VERSION ""

NS_ :

BS_:

BU_: ECM

BO_ 2566841088 EC_s0: 39 Vector__XXX
 SG_ SupportTSC1CtrlPurposeGroup4Of4 : 304|8@1+ (1,0) [0|255] "" Vector__XXX
 SG_ SupportVariableRateTSC1Message : 272|8@1+ (1,0) [0|255] "" Vector__XXX
 SG_ SupportTSC1CtrlPurposeGroup3Of4 : 296|8@1+ (1,0) [0|255] "" Vector__XXX
 SG_ SupportTSC1CtrlPurposeGroup2Of4 : 288|8@1+ (1,0) [0|255] "" Vector__XXX
 SG_ SupportTSC1CtrlPurposeGroup1Of4 : 280|8@1+ (1,0) [0|255] "" Vector__XXX
 SG_ EngDefaultTorqueLimit : 256|16@1+ (1,0) [0|64255] "Nm" Vector__XXX
 SG_ EngMomentOfInertia : 240|16@1+ (0.004,0) [0|257.02] "kg-m²" Vector__XXX
 SG_ EngExRngRqdSpdCtrlRngUpperLimit : 224|16@1+ (0.125,0) [0|8031.875] "rpm" Vector__XXX
 SG_ EngRqdTorqueCtrlRangeUpperLimit : 216|8@1+ (1,-125) [-125|125] "%" Vector__XXX
 SG_ EngRqdTorqueCtrlRangeLowerLimit : 208|8@1+ (1,-125) [-125|125] "%" Vector__XXX
 SG_ EngRqedSpeedCtrlRangeUpperLimit : 200|8@1+ (10,0) [0|2500] "rpm" Vector__XXX
 SG_ EngRqedSpeedCtrlRangeLowerLimit : 192|8@1+ (10,0) [0|2500] "rpm" Vector__XXX
 SG_ EngMxMomentaryOverrideTimeLimit : 184|8@1+ (0.1,0) [0|25] "s" Vector__XXX
 SG_ EngMxMmntaryOverrideSpeedPoint7 : 168|16@1+ (0.125,0) [0|8031.875] "rpm" Vector__XXX
 SG_ EngReferenceTorque : 152|16@1+ (1,0) [0|64255] "Nm" Vector__XXX
 SG_ EngSpeedAtHighIdlePoint6 : 120|16@1+ (0.125,0) [0|8031.875] "rpm" Vector__XXX
 SG_ EngGainOfEndspeedGovernor : 136|16@1+ (0.00078125,0) [0|50.2] "%/rpm" Vector__XXX
 SG_ EngPercentTorqueAtPoint5 : 112|8@1+ (1,-125) [-125|125] "%" Vector__XXX
 SG_ EngSpeedAtPoint5 : 96|16@1+ (0.125,0) [0|8031.875] "rpm" Vector__XXX
 SG_ EngPercentTorqueAtPoint4 : 88|8@1+ (1,-125) [-125|125] "%" Vector__XXX
 SG_ EngSpeedAtPoint4 : 72|16@1+ (0.125,0) [0|8031.875] "rpm" Vector__XXX
 SG_ EngPercentTorqueAtPoint3 : 64|8@1+ (1,-125) [-125|125] "%" Vector__XXX
 SG_ EngSpeedAtPoint3 : 48|16@1+ (0.125,0) [0|8031.875] "rpm" Vector__XXX
 SG_ EngPercentTorqueAtPoint2 : 40|8@1+ (1,-125) [-125|125] "%" Vector__XXX
 SG_ EngSpeedAtPoint2 : 24|16@1+ (0.125,0) [0|8031.875] "rpm" Vector__XXX
 SG_ EngPercentTorqueAtIdlePoint1 : 16|8@1+ (1,-125) [-125|125] "%" Vector__XXX
 SG_ EngSpeedAtIdlePoint1 : 0|16@1+ (0.125,0) [0|8031.875] "rpm" Vector__XXX

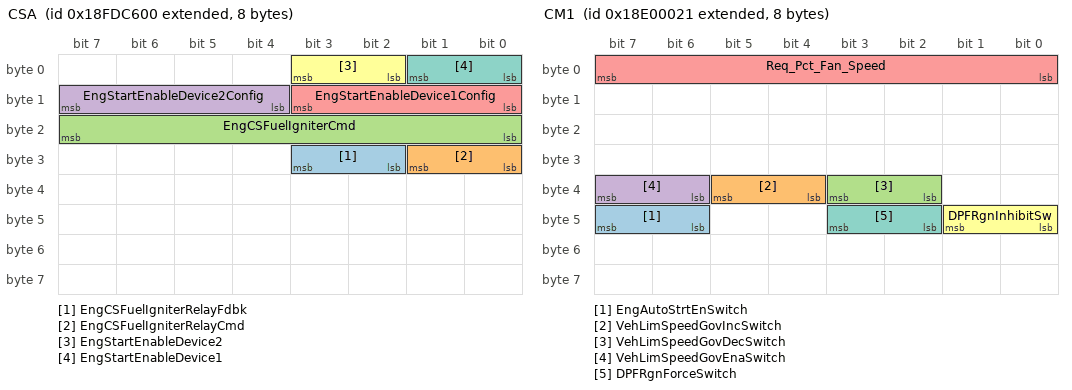
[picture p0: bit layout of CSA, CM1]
BO_ 2566768128 CSA: 8 Vector__XXX
 SG_ EngCSFuelIgniterRelayFdbk : 26|2@1+ (1,0) [0|3] "" Vector__XXX
 SG_ EngCSFuelIgniterRelayCmd : 24|2@1+ (1,0) [0|3] "" Vector__XXX
 SG_ EngCSFuelIgniterCmd : 16|8@1+ (0.4,0) [0|102] "%" Vector__XXX
 SG_ EngStartEnableDevice2Config : 12|4@1+ (1,0) [0|15] "" Vector__XXX
 SG_ EngStartEnableDevice1Config : 8|4@1+ (1,0) [0|15] "" Vector__XXX
 SG_ EngStartEnableDevice2 : 2|2@1+ (1,0) [0|3] "" Vector__XXX
 SG_ EngStartEnableDevice1 : 0|2@1+ (1,0) [0|3] "" Vector__XXX

BO_ 2564816929 CM1: 8 Vector__XXX
 SG_ EngAutoStrtEnSwitch : 46|2@1+ (1,0) [0|0] "" Vector__XXX
 SG_ VehLimSpeedGovIncSwitch : 36|2@1+ (1,0) [0|3] "" Vector__XXX
 SG_ VehLimSpeedGovDecSwitch : 34|2@1+ (1,0) [0|3] "" Vector__XXX
 SG_ VehLimSpeedGovEnaSwitch : 38|2@1+ (1,0) [0|3] "" Vector__XXX
 SG_ Req_Pct_Fan_Speed : 0|8@1+ (0.4,0) [0|100] "%" Vector__XXX
 SG_ DPFRgnInhibitSw : 40|2@1+ (1,0) [0|3] "unitless" Vector__XXX
 SG_ DPFRgnForceSwitch : 42|2@1+ (1,0) [0|3] "unitless" Vector__XXX

BO_ 2566843136 CI: 45 Vector__XXX
 SG_ UnitNumber_B09_B10 : 344|16@1+ (1,0) [0|0] "ASCII" Vector__XXX
 SG_ SerialNumber_B17 : 264|8@1+ (1,0) [0|0] "ASCII" Vector__XXX
 SG_ SerialNumber_B09_B16 : 200|64@1+ (1,0) [0|0] "ASCII" Vector__XXX
 SG_ CI_Delimiter_3 : 272|8@1+ (1,0) [0|0] "ASCII" Vector__XXX
 SG_ CI_Delimiter_2 : 128|8@1+ (1,0) [0|0] "ASCII" Vector__XXX
 SG_ Model_B09_B10 : 112|16@1+ (1,0) [0|0] "ASCII" Vector__XXX
 SG_ CI_Delimiter_1 : 40|8@1+ (1,0) [0|0] "ASCII" Vector__XXX
 SG_ UnitNumber_B01_B08 : 280|64@1+ (1,0) [0|0] "ASCII" Vector__XXX
 SG_ SerialNumber_B01_B08 : 136|64@1+ (1,0) [0|0] "ASCII" Vector__XXX
 SG_ Model_B01_B08 : 48|64@1+ (1,0) [0|0] "ASCII" Vector__XXX
 SG_ Make : 0|40@1+ (1,0) [0|0] "ASCII" Vector__XXX

BO_ 2566844672 CCVS_s0: 8 Vector__XXX
 SG_ EngShutdownOverrideSwitch : 62|2@1+ (1,0) [0|3] "" Vector__XXX
 SG_ EngTestModeSwitch : 60|2@1+ (1,0) [0|3] "" Vector__XXX
 SG_ EngIdleDecrementSwitch : 58|2@1+ (1,0) [0|3] "" Vector__XXX
 SG_ EngIdleIncrementSwitch : 56|2@1+ (1,0) [0|3] "" Vector__XXX
 SG_ CruiseCtrlStates : 53|3@1+ (1,0) [0|7] "" Vector__XXX
 SG_ PTOState : 48|5@1+ (1,0) [0|31] "" Vector__XXX
 SG_ CruiseCtrlSetSpeed : 40|8@1+ (1,0) [0|250] "km/h" Vector__XXX
 SG_ CruiseCtrlAccelerateSwitch : 38|2@1+ (1,0) [0|3] "" Vector__XXX
 SG_ CruiseCtrlResumeSwitch : 36|2@1+ (1,0) [0|3] "" Vector__XXX
 SG_ CruiseCtrlCoastSwitch : 34|2@1+ (1,0) [0|3] "" Vector__XXX
 SG_ CruiseCtrlSetSwitch : 32|2@1+ (1,0) [0|3] "" Vector__XXX
 SG_ ClutchSwitch : 30|2@1+ (1,0) [0|3] "" Vector__XXX
 SG_ BrakeSwitch : 28|2@1+ (1,0) [0|3] "" Vector__XXX
 SG_ CruiseCtrlEnableSwitch : 26|2@1+ (1,0) [0|3] "" Vector__XXX
 SG_ CruiseCtrlActive : 24|2@1+ (1,0) [0|3] "" Vector__XXX
 SG_ WheelBasedVehicleSpeed : 8|16@1+ (0.00390625,0) [0|250.996] "km/h" Vector__XXX
 SG_ CruiseCtrlPauseSwitch : 4|2@1+ (1,0) [0|3] "" Vector__XXX
 SG_ ParkingBrakeSwitch : 2|2@1+ (1,0) [0|3] "" Vector__XXX
 SG_ TwoSpeedAxleSwitch : 0|2@1+ (1,0) [0|3] "" Vector__XXX

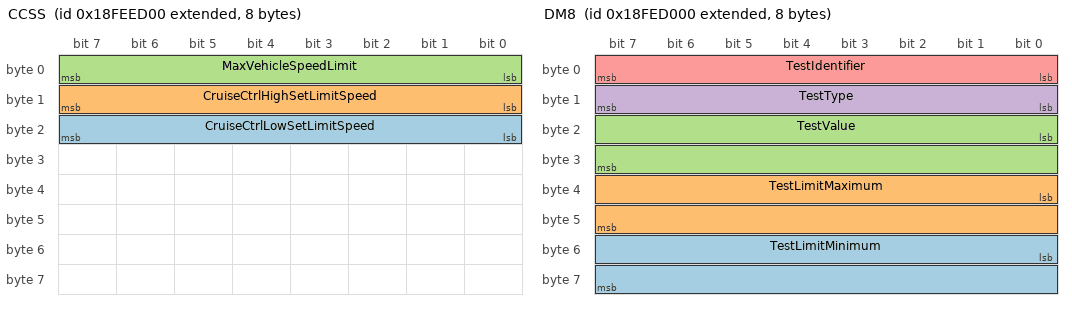
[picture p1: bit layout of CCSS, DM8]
BO_ 2566843648 CCSS: 8 Vector__XXX
 SG_ CruiseCtrlLowSetLimitSpeed : 16|8@1+ (1,0) [0|250] "km/h" Vector__XXX
 SG_ CruiseCtrlHighSetLimitSpeed : 8|8@1+ (1,0) [0|250] "km/h" Vector__XXX
 SG_ MaxVehicleSpeedLimit : 0|8@1+ (1,0) [0|250] "km/h" Vector__XXX

BO_ 2566836224 DM8: 8 Vector__XXX
 SG_ TestLimitMinimum : 48|16@1+ (1,0) [0|64255] "" Vector__XXX
 SG_ TestLimitMaximum : 32|16@1+ (1,0) [0|64255] "" Vector__XXX
 SG_ TestValue : 16|16@1+ (1,0) [0|64255] "" Vector__XXX
 SG_ TestType : 8|8@1+ (1,0) [1|64] "" Vector__XXX
 SG_ TestIdentifier : 0|8@1+ (1,0) [1|64] "" Vector__XXX

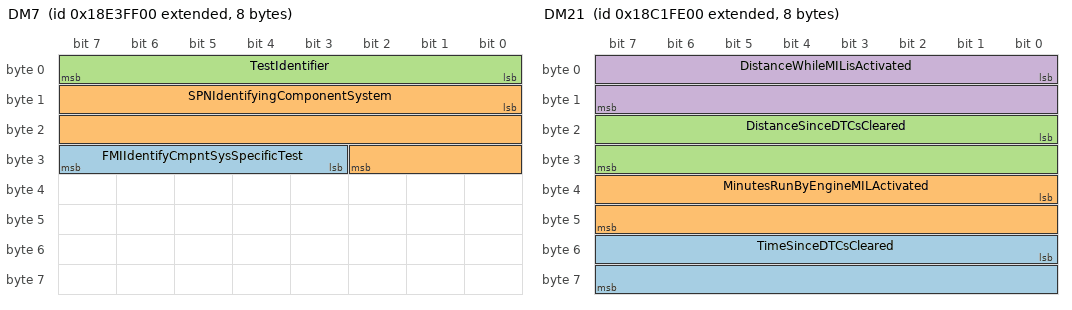
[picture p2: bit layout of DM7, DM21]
BO_ 2565078784 DM7: 8 Vector__XXX
 SG_ FMIIdentifyCmpntSysSpecificTest : 27|5@1+ (1,0) [0|31] "" Vector__XXX
 SG_ SPNIdentifyingComponentSystem : 8|19@1+ (1,0) [0|524287] "" Vector__XXX
 SG_ TestIdentifier : 0|8@1+ (1,0) [1|64] "" Vector__XXX

BO_ 2566835968 DM6: 22 Vector__XXX
 SG_ SPN5 : 144|16@1+ (1,0) [0|65536] "" Vector__XXX
 SG_ SPN4 : 112|16@1+ (1,0) [0|65536] "" Vector__XXX
 SG_ SPN3 : 80|16@1+ (1,0) [0|65536] "" Vector__XXX
 SG_ SPN2 : 48|16@1+ (1,0) [0|65536] "" Vector__XXX
 SG_ SPN1 : 16|16@1+ (1,0) [0|65536] "" Vector__XXX
 SG_ RedStopLampStatus : 4|2@1+ (1,0) [0|3] "" Vector__XXX
 SG_ ProtectLampStatus : 0|2@1+ (1,0) [0|3] "" Vector__XXX
 SG_ AmberWarningLampStatus : 2|2@1+ (1,0) [0|3] "" Vector__XXX
 SG_ MalfunctionIndicatorLampStatus : 6|2@1+ (1,0) [0|3] "" Vector__XXX
 SG_ FailureModeIdentifier5 : 160|5@1+ (1,0) [0|0] "" Vector__XXX
 SG_ FailureModeIdentifier4 : 128|5@1+ (1,0) [0|0] "" Vector__XXX
 SG_ FailureModeIdentifier3 : 96|5@1+ (1,0) [0|0] "" Vector__XXX
 SG_ FailureModeIdentifier2 : 64|5@1+ (1,0) [0|0] "" Vector__XXX
 SG_ SPNConversionMethod5 : 175|1@1+ (1,0) [0|1] "" Vector__XXX
 SG_ SPNConversionMethod4 : 143|1@1+ (1,0) [0|1] "" Vector__XXX
 SG_ SPNConversionMethod3 : 111|1@1+ (1,0) [0|1] "" Vector__XXX
 SG_ SPNConversionMethod2 : 79|1@1+ (1,0) [0|1] "" Vector__XXX
 SG_ OccurenceCount5 : 168|7@1+ (1,0) [0|126] "" Vector__XXX
 SG_ OccurenceCount4 : 136|7@1+ (1,0) [0|126] "" Vector__XXX
 SG_ OccurenceCount3 : 104|7@1+ (1,0) [0|126] "" Vector__XXX
 SG_ OccurenceCount2 : 72|7@1+ (1,0) [0|126] "" Vector__XXX
 SG_ OccurenceCount1 : 40|7@1+ (1,0) [0|126] "" Vector__XXX
 SG_ SPNConversionMethod1 : 47|1@1+ (1,0) [0|1] "" Vector__XXX
 SG_ FailureModeIdentifier1 : 32|5@1+ (1,0) [0|0] "" Vector__XXX
 SG_ SPN5High : 165|3@1+ (1,0) [0|7] "" Vector__XXX
 SG_ SPN4High : 133|3@1+ (1,0) [0|7] "" Vector__XXX
 SG_ SPN3High : 101|3@1+ (1,0) [0|7] "" Vector__XXX
 SG_ SPN2High : 69|3@1+ (1,0) [0|7] "" Vector__XXX
 SG_ SPN1High : 37|3@1+ (1,0) [0|7] "" Vector__XXX

BO_ 2566835712 DM5: 8 Vector__XXX
 SG_ PMFilterMonStatus : 58|1@1+ (1,0) [0|1] "" Vector__XXX
 SG_ NOxCnvrtctlystMonStatus : 59|1@1+ (1,0) [0|1] "" Vector__XXX
 SG_ NHMCCnvrtctlystMonStatus : 60|1@1+ (1,0) [0|1] "" Vector__XXX
 SG_ BstPressCtrlSystemMonStatus : 57|1@1+ (1,0) [0|1] "" Vector__XXX
 SG_ NOxCnvrtctlystMonSupp : 43|1@1+ (1,0) [0|1] "" Vector__XXX
 SG_ PMFilterMonSupp : 42|1@1+ (1,0) [0|1] "" Vector__XXX
 SG_ NHMCCnvrtctlystMonSupp : 44|1@1+ (1,0) [0|1] "" Vector__XXX
 SG_ BstPressCtrlSystemMonSupp : 41|1@1+ (1,0) [0|1] "" Vector__XXX
 SG_ MisfireMonitoringSupport : 24|1@1+ (1,0) [0|0] "" Vector__XXX
 SG_ OBDCompliance : 16|8@1+ (1,0) [0|240] "" Vector__XXX
 SG_ PreviouslyActiveTroubleCodes : 8|8@1+ (1,0) [0|240] "" Vector__XXX
 SG_ ActiveTroubleCodes : 0|8@1+ (1,0) [0|240] "" Vector__XXX
 SG_ SecondAirSystemMonStatus : 51|1@1+ (1,0) [0|1] "" Vector__XXX
 SG_ EvaporativeSystemMonStatus : 50|1@1+ (1,0) [0|1] "" Vector__XXX
 SG_ ACSystemRefrigerantMonStatus : 52|1@1+ (1,0) [0|1] "" Vector__XXX
 SG_ OxygenSensorHeaterMonStatus : 54|1@1+ (1,0) [0|1] "" Vector__XXX
 SG_ OxygenSensorMonStatus : 53|1@1+ (1,0) [0|1] "" Vector__XXX
 SG_ EGRSystemMonitoringStatus : 55|1@1+ (1,0) [0|1] "" Vector__XXX
 SG_ CatalystMonStatus : 48|1@1+ (1,0) [0|1] "" Vector__XXX
 SG_ ColdStartAidSystemMonStatus : 56|1@1+ (1,0) [0|1] "" Vector__XXX
 SG_ HeatedCatalystMonStatus : 49|1@1+ (1,0) [0|0] "" Vector__XXX
 SG_ CatalystMonSupp : 32|1@1+ (1,0) [0|1] "" Vector__XXX
 SG_ ColdStartAidSystemMonSupp : 40|1@1+ (1,0) [0|1] "" Vector__XXX
 SG_ HeatedCatalystMonSupp : 33|1@1+ (1,0) [0|0] "" Vector__XXX
 SG_ EvaporativeSystemMonSupp : 34|1@1+ (1,0) [0|1] "" Vector__XXX
 SG_ SecondAirSystemMonSupp : 35|1@1+ (1,0) [0|1] "" Vector__XXX
 SG_ ACSystemRefrigerantMonSupp : 36|1@1+ (1,0) [0|1] "" Vector__XXX
 SG_ OxygenSensorMonSupp : 37|1@1+ (1,0) [0|1] "" Vector__XXX
 SG_ OxygenSensorHeaterMonSupp : 38|1@1+ (1,0) [0|1] "" Vector__XXX
 SG_ EGRSystemMonitoringSupp : 39|1@1+ (1,0) [0|1] "" Vector__XXX
 SG_ MisfireMonitoringStatus : 28|1@1+ (1,0) [0|0] "" Vector__XXX
 SG_ ComprehensiveCompMonStatus : 30|1@1+ (1,0) [0|1] "" Vector__XXX
 SG_ FuelSystemMonitoringStatus : 29|1@1+ (1,0) [0|1] "" Vector__XXX
 SG_ ComprehensiveComponentMonSupp : 26|1@1+ (1,0) [0|0] "" Vector__XXX
 SG_ FuelSystemMonitoringSupport : 25|1@1+ (1,0) [0|1] "" Vector__XXX

BO_ 2566835456 DM4: 13 Vector__XXX
 SG_ SPN1 : 8|16@1+ (1,0) [0|65536] "" Vector__XXX
 SG_ EngSpeed : 56|16@1+ (0.125,0) [0|8031.875] "rpm" Vector__XXX
 SG_ EngTurboBoostPress : 48|8@1+ (2,0) [0|500] "kPa" Vector__XXX
 SG_ EngPercentLoadAtCurrentSpeed : 72|8@1+ (1,0) [0|250] "%" Vector__XXX
 SG_ WheelBasedVehicleSpeed : 88|16@1+ (0.00390625,0) [0|250.996] "km/h" Vector__XXX
 SG_ OccurenceCount1 : 32|7@1+ (1,0) [0|126] "" Vector__XXX
 SG_ SPNConversionMethod1 : 39|1@1+ (1,0) [0|1] "" Vector__XXX
 SG_ FailureModeIdentifier1 : 24|5@1+ (1,0) [0|0] "" Vector__XXX
 SG_ FreezeFrameLength : 0|8@1+ (1,0) [0|255] "byte" Vector__XXX
 SG_ EngTorqueMode : 40|4@1+ (1,0) [0|15] "" Vector__XXX
 SG_ EngineCoolantTemperature : 80|8@1+ (1,-40) [-40|210] "°C" Vector__XXX
 SG_ SPN1High : 29|3@1+ (1,0) [0|7] "" Vector__XXX

BO_ 2566835200 DM3: 0 Vector__XXX

BO_ 2566763776 DM23: 22 Vector__XXX
 SG_ FailureModeIdentifier5 : 160|5@1+ (1,0) [0|0] "" Vector__XXX
 SG_ FailureModeIdentifier4 : 128|5@1+ (1,0) [0|0] "" Vector__XXX
 SG_ FailureModeIdentifier3 : 96|5@1+ (1,0) [0|0] "" Vector__XXX
 SG_ FailureModeIdentifier2 : 64|5@1+ (1,0) [0|0] "" Vector__XXX
 SG_ FailureModeIdentifier1 : 32|5@1+ (1,0) [0|0] "" Vector__XXX
 SG_ FlashRedStopLamp : 12|2@1+ (1,0) [0|3] "" Vector__XXX
 SG_ FlashProtectLamp : 8|2@1+ (1,0) [0|3] "" Vector__XXX
 SG_ FlashMalfuncIndicatorLamp : 14|2@1+ (1,0) [0|3] "" Vector__XXX
 SG_ FlashAmberWarningLamp : 10|2@1+ (1,0) [0|3] "" Vector__XXX
 SG_ SPN5 : 144|16@1+ (1,0) [0|65536] "" Vector__XXX
 SG_ SPN4 : 112|16@1+ (1,0) [0|65536] "" Vector__XXX
 SG_ SPN3 : 80|16@1+ (1,0) [0|65536] "" Vector__XXX
 SG_ SPN2 : 48|16@1+ (1,0) [0|65536] "" Vector__XXX
 SG_ SPN1 : 16|16@1+ (1,0) [0|65536] "" Vector__XXX
 SG_ RedStopLampStatus : 4|2@1+ (1,0) [0|3] "" Vector__XXX
 SG_ ProtectLampStatus : 0|2@1+ (1,0) [0|3] "" Vector__XXX
 SG_ AmberWarningLampStatus : 2|2@1+ (1,0) [0|3] "" Vector__XXX
 SG_ MalfunctionIndicatorLampStatus : 6|2@1+ (1,0) [0|3] "" Vector__XXX
 SG_ OccurenceCount1 : 40|7@1+ (1,0) [0|126] "" Vector__XXX
 SG_ SPNConversionMethod1 : 47|1@1+ (1,0) [0|1] "" Vector__XXX
 SG_ SPNConversionMethod5 : 175|1@1+ (1,0) [0|1] "" Vector__XXX
 SG_ SPNConversionMethod4 : 143|1@1+ (1,0) [0|1] "" Vector__XXX
 SG_ SPNConversionMethod3 : 111|1@1+ (1,0) [0|1] "" Vector__XXX
 SG_ SPNConversionMethod2 : 79|1@1+ (1,0) [0|1] "" Vector__XXX
 SG_ OccurenceCount5 : 168|7@1+ (1,0) [0|126] "" Vector__XXX
 SG_ OccurenceCount4 : 136|7@1+ (1,0) [0|126] "" Vector__XXX
 SG_ OccurenceCount3 : 104|7@1+ (1,0) [0|126] "" Vector__XXX
 SG_ OccurenceCount2 : 72|7@1+ (1,0) [0|126] "" Vector__XXX
 SG_ SPN5High : 165|3@1+ (1,0) [0|7] "" Vector__XXX
 SG_ SPN4High : 133|3@1+ (1,0) [0|7] "" Vector__XXX
 SG_ SPN3High : 101|3@1+ (1,0) [0|7] "" Vector__XXX
 SG_ SPN2High : 69|3@1+ (1,0) [0|7] "" Vector__XXX
 SG_ SPN1High : 37|3@1+ (1,0) [0|7] "" Vector__XXX

BO_ 2562850304 DM21: 8 Vector__XXX
 SG_ TimeSinceDTCsCleared : 48|16@1+ (1,0) [0|64255] "min" Vector__XXX
 SG_ MinutesRunByEngineMILActivated : 32|16@1+ (1,0) [0|64255] "min" Vector__XXX
 SG_ DistanceSinceDTCsCleared : 16|16@1+ (1,0) [0|64255] "km" Vector__XXX
 SG_ DistanceWhileMILisActivated : 0|16@1+ (1,0) [0|64255] "km" Vector__XXX

BO_ 2562915840 DM20: 11 Vector__XXX
 SG_ ApplSysMonitorDenominator : 72|16@1+ (1,0) [0|65535] "" Vector__XXX
 SG_ ApplSysMonitorNumerator : 56|16@1+ (1,0) [0|65535] "" Vector__XXX
 SG_ SPNofApplSysMonitor : 32|24@1+ (1,0) [0|524287] "" Vector__XXX
 SG_ OBDMonitoringCondEncountered : 16|16@1+ (1,0) [0|65535] "" Vector__XXX
 SG_ IgnitionCycleCounter : 0|16@1+ (1,0) [0|65535] "" Vector__XXX

BO_ 2566834944 DM2_s0: 22 Vector__XXX
 SG_ FailureModeIdentifier5 : 160|5@1+ (1,0) [0|0] "" Vector__XXX
 SG_ FailureModeIdentifier4 : 128|5@1+ (1,0) [0|0] "" Vector__XXX
 SG_ FailureModeIdentifier3 : 96|5@1+ (1,0) [0|0] "" Vector__XXX
 SG_ FailureModeIdentifier2 : 64|5@1+ (1,0) [0|0] "" Vector__XXX
 SG_ FailureModeIdentifier1 : 32|5@1+ (1,0) [0|0] "" Vector__XXX
 SG_ FlashRedStopLamp : 12|2@1+ (1,0) [0|3] "" Vector__XXX
 SG_ FlashProtectLamp : 8|2@1+ (1,0) [0|3] "" Vector__XXX
 SG_ FlashMalfuncIndicatorLamp : 14|2@1+ (1,0) [0|3] "" Vector__XXX
 SG_ FlashAmberWarningLamp : 10|2@1+ (1,0) [0|3] "" Vector__XXX
 SG_ SPN5 : 144|16@1+ (1,0) [0|65536] "" Vector__XXX
 SG_ SPN4 : 112|16@1+ (1,0) [0|65536] "" Vector__XXX
 SG_ SPN3 : 80|16@1+ (1,0) [0|65536] "" Vector__XXX
 SG_ SPN2 : 48|16@1+ (1,0) [0|65536] "" Vector__XXX
 SG_ SPN1 : 16|16@1+ (1,0) [0|65536] "" Vector__XXX
 SG_ RedStopLampStatus : 4|2@1+ (1,0) [0|3] "" Vector__XXX
 SG_ ProtectLampStatus : 0|2@1+ (1,0) [0|3] "" Vector__XXX
 SG_ AmberWarningLampStatus : 2|2@1+ (1,0) [0|3] "" Vector__XXX
 SG_ MalfunctionIndicatorLampStatus : 6|2@1+ (1,0) [0|3] "" Vector__XXX
 SG_ OccurenceCount1 : 40|7@1+ (1,0) [0|126] "" Vector__XXX
 SG_ SPNConversionMethod1 : 47|1@1+ (1,0) [0|1] "" Vector__XXX
 SG_ SPNConversionMethod5 : 175|1@1+ (1,0) [0|1] "" Vector__XXX
 SG_ SPNConversionMethod4 : 143|1@1+ (1,0) [0|1] "" Vector__XXX
 SG_ SPNConversionMethod3 : 111|1@1+ (1,0) [0|1] "" Vector__XXX
 SG_ SPNConversionMethod2 : 79|1@1+ (1,0) [0|1] "" Vector__XXX
 SG_ OccurenceCount5 : 168|7@1+ (1,0) [0|126] "" Vector__XXX
 SG_ OccurenceCount4 : 136|7@1+ (1,0) [0|126] "" Vector__XXX
 SG_ OccurenceCount3 : 104|7@1+ (1,0) [0|126] "" Vector__XXX
 SG_ OccurenceCount2 : 72|7@1+ (1,0) [0|126] "" Vector__XXX
 SG_ SPN5High : 165|3@1+ (1,0) [0|7] "" Vector__XXX
 SG_ SPN4High : 133|3@1+ (1,0) [0|7] "" Vector__XXX
 SG_ SPN3High : 101|3@1+ (1,0) [0|7] "" Vector__XXX
 SG_ SPN2High : 69|3@1+ (1,0) [0|7] "" Vector__XXX
 SG_ SPN1High : 37|3@1+ (1,0) [0|7] "" Vector__XXX

BO_ 2631078400 DM19: 20 Vector__XXX
 SG_ CalibrationID4 : 128|32@1+ (1,0) [0|4294967295] "" Vector__XXX
 SG_ CalibrationID3 : 96|32@1+ (1,0) [0|4294967295] "" Vector__XXX
 SG_ CalibrationID2 : 64|32@1+ (1,0) [0|4294967295] "" Vector__XXX
 SG_ CalibrationID1 : 32|32@1+ (1,0) [0|4294967295] "" Vector__XXX
 SG_ CalibrationVerificationNumber : 0|32@1+ (1,0) [0|4294967295] "" Vector__XXX

BO_ 2566837248 DM12: 22 Vector__XXX
 SG_ FlashRedStopLamp : 12|2@1+ (1,0) [0|3] "" Vector__XXX
 SG_ FlashProtectLamp : 8|2@1+ (1,0) [0|3] "" Vector__XXX
 SG_ FlashMalfuncIndicatorLamp : 14|2@1+ (1,0) [0|3] "" Vector__XXX
 SG_ FlashAmberWarningLamp : 10|2@1+ (1,0) [0|3] "" Vector__XXX
 SG_ FailureModeIdentifier5 : 160|5@1+ (1,0) [0|0] "" Vector__XXX
 SG_ FailureModeIdentifier4 : 128|5@1+ (1,0) [0|0] "" Vector__XXX
 SG_ FailureModeIdentifier3 : 96|5@1+ (1,0) [0|0] "" Vector__XXX
 SG_ FailureModeIdentifier2 : 64|5@1+ (1,0) [0|0] "" Vector__XXX
 SG_ FailureModeIdentifier1 : 32|5@1+ (1,0) [0|0] "" Vector__XXX
 SG_ SPN5 : 144|16@1+ (1,0) [0|65536] "" Vector__XXX
 SG_ SPN4 : 112|16@1+ (1,0) [0|65536] "" Vector__XXX
 SG_ SPN3 : 80|16@1+ (1,0) [0|65536] "" Vector__XXX
 SG_ SPN2 : 48|16@1+ (1,0) [0|65536] "" Vector__XXX
 SG_ SPN1 : 16|16@1+ (1,0) [0|65536] "" Vector__XXX
 SG_ RedStopLampStatus : 4|2@1+ (1,0) [0|3] "" Vector__XXX
 SG_ ProtectLampStatus : 0|2@1+ (1,0) [0|3] "" Vector__XXX
 SG_ AmberWarningLampStatus : 2|2@1+ (1,0) [0|3] "" Vector__XXX
 SG_ MalfunctionIndicatorLampStatus : 6|2@1+ (1,0) [0|3] "" Vector__XXX
 SG_ OccurenceCount1 : 40|7@1+ (1,0) [0|126] "" Vector__XXX
 SG_ SPNConversionMethod1 : 47|1@1+ (1,0) [0|1] "" Vector__XXX
 SG_ SPNConversionMethod5 : 175|1@1+ (1,0) [0|1] "" Vector__XXX
 SG_ SPNConversionMethod4 : 143|1@1+ (1,0) [0|1] "" Vector__XXX
 SG_ SPNConversionMethod3 : 111|1@1+ (1,0) [0|1] "" Vector__XXX
 SG_ SPNConversionMethod2 : 79|1@1+ (1,0) [0|1] "" Vector__XXX
 SG_ OccurenceCount5 : 168|7@1+ (1,0) [0|126] "" Vector__XXX
 SG_ OccurenceCount4 : 136|7@1+ (1,0) [0|126] "" Vector__XXX
 SG_ OccurenceCount3 : 104|7@1+ (1,0) [0|126] "" Vector__XXX
 SG_ OccurenceCount2 : 72|7@1+ (1,0) [0|126] "" Vector__XXX
 SG_ SPN5High : 165|3@1+ (1,0) [0|7] "" Vector__XXX
 SG_ SPN4High : 133|3@1+ (1,0) [0|7] "" Vector__XXX
 SG_ SPN3High : 101|3@1+ (1,0) [0|7] "" Vector__XXX
 SG_ SPN2High : 69|3@1+ (1,0) [0|7] "" Vector__XXX
 SG_ SPN1High : 37|3@1+ (1,0) [0|7] "" Vector__XXX

BO_ 2566836992 DM11: 0 Vector__XXX

BO_ 2566836736 DM10: 8 Vector__XXX
 SG_ TestIdentifierSupported : 0|64@1+ (1,0) [1|1.8446744074E+019] "" Vector__XXX

BO_ 2565603072 TPDT_s0: 8 Vector__XXX
 SG_ SequenceNumber : 0|8@1+ (1,0) [0|252] "" Vector__XXX

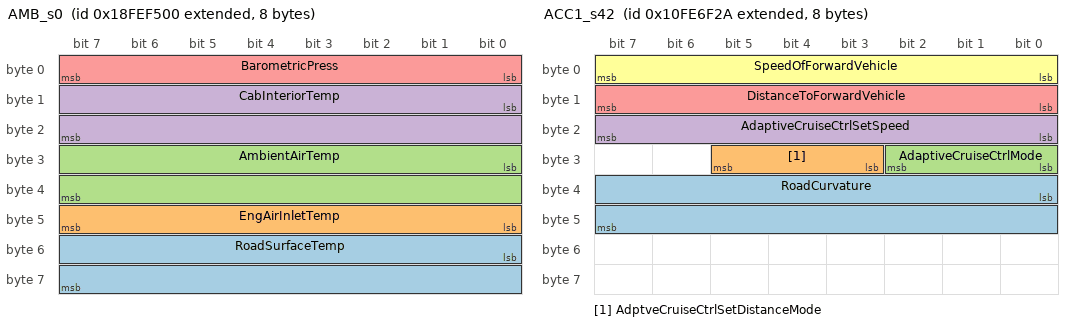
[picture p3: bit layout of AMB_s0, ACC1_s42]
BO_ 2566845696 AMB_s0: 8 Vector__XXX
 SG_ RoadSurfaceTemp : 48|16@1+ (0.03125,-273) [-273|1735] "°C" Vector__XXX
 SG_ EngAirInletTemp : 40|8@1+ (1,-40) [-40|210] "°C" Vector__XXX
 SG_ AmbientAirTemp : 24|16@1+ (0.03125,-273) [-273|1735] "°C" Vector__XXX
 SG_ CabInteriorTemp : 8|16@1+ (0.03125,-273) [-273|1735] "°C" Vector__XXX
 SG_ BarometricPress : 0|8@1+ (0.5,0) [0|125] "kPa" Vector__XXX

BO_ 2633935360 AF2: 8 Vector__XXX
 SG_ EngDsiredAbsIntakeManifoldPress : 8|16@1+ (0.1,0) [0|6425.5] "kPa" Vector__XXX

BO_ 2432593706 ACC1_s42: 8 Vector__XXX
 SG_ RoadCurvature : 32|16@1+ (0.0078125,-250) [-250|251.992] "1/km" Vector__XXX
 SG_ AdptveCruiseCtrlSetDistanceMode : 27|3@1+ (1,0) [0|7] "" Vector__XXX
 SG_ AdaptiveCruiseCtrlMode : 24|3@1+ (1,0) [0|7] "" Vector__XXX
 SG_ AdaptiveCruiseCtrlSetSpeed : 16|8@1+ (1,0) [0|250] "km/h" Vector__XXX
 SG_ DistanceToForwardVehicle : 8|8@1+ (1,0) [0|250] "m" Vector__XXX
 SG_ SpeedOfForwardVehicle : 0|8@1+ (1,0) [0|250] "km/h" Vector__XXX

BO_ 2566763520 ATI2: 8 Vector__XXX
 SG_ ParticulateTrapIntakeGasTemp : 16|16@1- (0.03125,-273) [-273|1735] "DegC" Vector__XXX
 SG_ ExhaustGasTemp1 : 0|16@1+ (0.03125,-273) [-273|1735] "°C" Vector__XXX

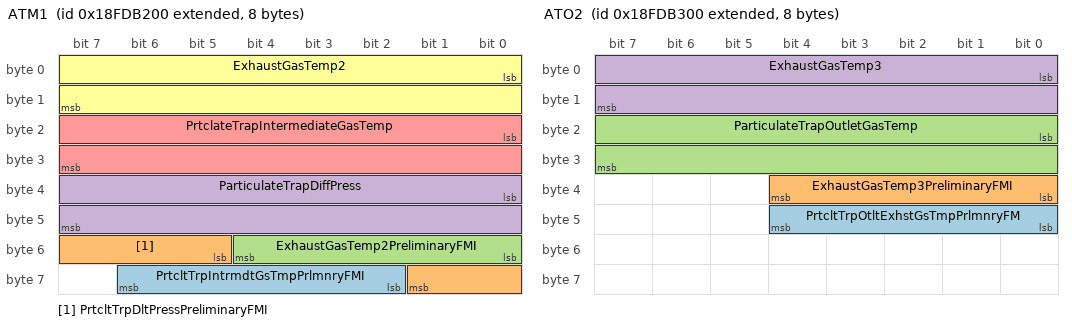
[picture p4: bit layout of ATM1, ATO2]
BO_ 2566763008 ATM1: 8 Vector__XXX
 SG_ PrtcltTrpIntrmdtGsTmpPrlmnryFMI : 58|5@1+ (1,0) [0|31] "" Vector__XXX
 SG_ PrtcltTrpDltPressPreliminaryFMI : 53|5@1+ (1,0) [0|31] "" Vector__XXX
 SG_ ExhaustGasTemp2PreliminaryFMI : 48|5@1+ (1,0) [0|31] "" Vector__XXX
 SG_ ParticulateTrapDiffPress : 32|16@1+ (0.1,0) [0|6425.5] "kPa" Vector__XXX
 SG_ PrtclateTrapIntermediateGasTemp : 16|16@1+ (0.03125,-273) [-273|1735] "°C" Vector__XXX
 SG_ ExhaustGasTemp2 : 0|16@1+ (0.03125,-273) [-273|1735] "°C" Vector__XXX

BO_ 2566763264 ATO2: 8 Vector__XXX
 SG_ PrtcltTrpOtltExhstGsTmpPrlmnryFM : 40|5@1+ (1,0) [0|31] "" Vector__XXX
 SG_ ExhaustGasTemp3PreliminaryFMI : 32|5@1+ (1,0) [0|31] "" Vector__XXX
 SG_ ParticulateTrapOutletGasTemp : 16|16@1+ (0.03125,-273) [-273|1735] "°C" Vector__XXX
 SG_ ExhaustGasTemp3 : 0|16@1+ (0.03125,-273) [-273|1735] "°C" Vector__XXX

CM_ BO_ 2566841088 "Engine Configuration";
CM_ SG_ 2566841088 SupportTSC1CtrlPurposeGroup4Of4 "This parameter indicates which TSC1 control purposes are supported in group 4 of 4.";
CM_ SG_ 2566841088 SupportTSC1CtrlPurposeGroup3Of4 "This parameter indicates which TSC1 control purposes are supported in group 3 of 4.";
CM_ SG_ 2566841088 SupportTSC1CtrlPurposeGroup2Of4 "This parameter indicates which TSC1 control purposes are supported in group 2 of 4.";
CM_ SG_ 2566841088 SupportTSC1CtrlPurposeGroup1Of4 "This parameter indicates which TSC1 control purposes are supported in group 1 of 4.";
CM_ SG_ 2566841088 EngDefaultTorqueLimit "Companion parameter to Transmission Torque Limit (SPN 1845).";
CM_ SG_ 2566841088 EngMomentOfInertia "Moment of inertia for the engine, including items driven full-time by the engine such as fuel, oil and cooling pumps.";
CM_ SG_ 2566841088 EngRqdTorqueCtrlRangeUpperLimit "The maximum engine torque that the engine will allow when operating in a torque control/limit mode.";
CM_ SG_ 2566841088 EngRqdTorqueCtrlRangeLowerLimit "The minimum engine torque that the engine will allow when operating in a torque control/limit mode.";
CM_ SG_ 2566841088 EngRqedSpeedCtrlRangeLowerLimit "The minimum engine speed that the engine will allow when operating in a speed control/limit mode.";
CM_ SG_ 2566841088 EngMxMomentaryOverrideTimeLimit "The maximum time limit allowed to override the engine's high idle speed.";
CM_ SG_ 2566841088 EngMxMmntaryOverrideSpeedPoint7 "The maximum engine speed above high idle allowed by the engine control during a momentary high idle override.";
CM_ SG_ 2566841088 EngReferenceTorque "This parameter is the 100% reference value for all defined indicated engine torque parameters.";
CM_ SG_ 2566841088 EngSpeedAtHighIdlePoint6 "Engine speed of high idle (point 6) of the engine torque map (see PGN 65251 and supporting document).";
CM_ SG_ 2566841088 EngSpeedAtPoint5 "Engine speed of point 3, 4, and 5 of the engine torque map (see PGN 65251 and supporting document).";
CM_ SG_ 2566841088 EngSpeedAtPoint4 "Engine speed of point 3, 4, and 5 of the engine torque map (see PGN 65251 and supporting document).";
CM_ SG_ 2566841088 EngSpeedAtPoint3 "Engine speed of point 3, 4, and 5 of the engine torque map (see PGN 65251 and supporting document).";
CM_ SG_ 2566841088 EngSpeedAtPoint2 "Engine speed of point 2 of the engine torque map (see PGN 65251 and supporting document).";
CM_ SG_ 2566841088 EngPercentTorqueAtIdlePoint1 "The torque limit that indicates the available engine torque which can be provided by the engine at idle speed.";
CM_ BO_ 2566768128 "Cold Start Aids";
CM_ SG_ 2566768128 EngCSFuelIgniterRelayFdbk "Feedback state of the cold start fuel igniter relay";
CM_ SG_ 2566768128 EngCSFuelIgniterRelayCmd "Command to control the cold start fuel igniter relay";
CM_ SG_ 2566768128 EngCSFuelIgniterCmd "Cold start fuel igniter control command
";
CM_ SG_ 2566768128 EngStartEnableDevice2Config "The start enable device installed for start enable device 2.";
CM_ SG_ 2566768128 EngStartEnableDevice1Config "The start enable device installed for start enable device 1.";
CM_ SG_ 2566768128 EngStartEnableDevice2 "Devices that assist an engine in starting, e.";
CM_ SG_ 2566768128 EngStartEnableDevice1 "Devices that assist an Engine in starting, e.";
CM_ BO_ 2564816929 "Cab Message 1";
CM_ SG_ 2564816929 EngAutoStrtEnSwitch "Engine Automatic Start Enable Switch";
CM_ SG_ 2564816929 VehLimSpeedGovIncSwitch "Switch signal which increases the Vehicle Limiting Speed Governor.";
CM_ SG_ 2564816929 VehLimSpeedGovDecSwitch "Switch signal which decreases the Vehicle Limiting Speed Governor.";
CM_ SG_ 2564816929 VehLimSpeedGovEnaSwitch "Switch signal which enables the Vehicle Limiting Speed Governor (VLSG) such that the vehicle speed may be either increased or decreased when the engine is
off idle.";
CM_ SG_ 2564816929 DPFRgnInhibitSw "corrected the spn in db version 1";
CM_ SG_ 2564816929 DPFRgnForceSwitch "corrected the spn in db version1";
CM_ BO_ 2566843136 "Component Identification";
CM_ SG_ 2566843136 UnitNumber_B09_B10 "Newly added to the db ver1
Note: The Unit Number field is 10 bytes long.  This represents the last 2 bytes.";
CM_ SG_ 2566843136 SerialNumber_B17 "Newly added to the db ver1
Note: The Serial Number field is 17 bytes long.  This represents the last byte.";
CM_ SG_ 2566843136 SerialNumber_B09_B16 "Newly added to the db ver1
Note: The Serial Number field is 17 bytes long.  This represents the middle 8 bytes.";
CM_ SG_ 2566843136 CI_Delimiter_3 "This represents the field delimiter * in the CI message.";
CM_ SG_ 2566843136 CI_Delimiter_2 "This represents the field delimiter * in the CI message.";
CM_ SG_ 2566843136 Model_B09_B10 "Newly added to the db ver1
Note: The Model field is 10 bytes long.  This represents the last 2 bytes.";
CM_ SG_ 2566843136 CI_Delimiter_1 "This represents the field delimiter * in the CI message.";
CM_ SG_ 2566843136 UnitNumber_B01_B08 "Newly added to the db ver1
Note: The Unit Number field is 10 bytes long.  This represents the first 8 bytes.";
CM_ SG_ 2566843136 SerialNumber_B01_B08 "Newly added to the db ver1
Note: The Serial Number field is 17 bytes long.  This represents the first 8 bytes.";
CM_ SG_ 2566843136 Model_B01_B08 "Newly added to the db ver1
Note: The Model field is 10 bytes long.  This represents the first 8 bytes.";
CM_ BO_ 2566844672 "Cruise Control/Vehicle Speed";
CM_ SG_ 2566844672 EngShutdownOverrideSwitch "Switch signal which indicates the position of the engine shutdown override switch.";
CM_ SG_ 2566844672 EngTestModeSwitch "Switch signal which indicates the position of the engine test mode switch.";
CM_ SG_ 2566844672 EngIdleDecrementSwitch "Switch signal which indicates the position of the idle decrement switch.";
CM_ SG_ 2566844672 EngIdleIncrementSwitch "Switch signal which indicates the position of the idle increment switch.";
CM_ SG_ 2566844672 CruiseCtrlStates "This parameter is used to indicate the current state, or mode, of operation by the cruise control device.";
CM_ SG_ 2566844672 PTOState "This parameter is used to indicate the current state or mode of operation by the power takeoff (PTO) device.";
CM_ SG_ 2566844672 CruiseCtrlSetSpeed "Value of set (chosen) velocity of velocity control system.";
CM_ SG_ 2566844672 CruiseCtrlAccelerateSwitch "Switch signal of the cruise control activator which indicates that the activator is in the position “accelerate.";
CM_ SG_ 2566844672 CruiseCtrlResumeSwitch "Switch signal of the cruise control activator which indicates that the activator is in the position “resume.";
CM_ SG_ 2566844672 CruiseCtrlCoastSwitch "Switch signal of the cruise control activator which indicates that the activator is in the position “coast (decelerate).";
CM_ SG_ 2566844672 CruiseCtrlSetSwitch "Switch signal of the cruise control activator which indicates that the activator is in the position “set.";
CM_ SG_ 2566844672 ClutchSwitch "Switch signal which indicates that the clutch pedal is being pressed.";
CM_ SG_ 2566844672 BrakeSwitch "Switch signal which indicates that the driver operated brake foot pedal is being pressed.";
CM_ SG_ 2566844672 CruiseCtrlEnableSwitch "Switch signal which indicates that it is possible to manage the cruise control function.";
CM_ SG_ 2566844672 CruiseCtrlActive "Cruise control is switched on.";
CM_ SG_ 2566844672 WheelBasedVehicleSpeed "Speed of the vehicle as calculated from wheel or tailshaft speed.";
CM_ SG_ 2566844672 CruiseCtrlPauseSwitch "Switch signal which indicates the position of the Cruise Control Pause Switch used on Remote Cruise Control applications.";
CM_ SG_ 2566844672 ParkingBrakeSwitch "Switch signal which indicates when the parking brake is set.";
CM_ SG_ 2566844672 TwoSpeedAxleSwitch "Switch signal which indicates the current axle range.";
CM_ BO_ 2566843648 "Cruise Control/Vehicle Speed Setup";
CM_ SG_ 2566843648 CruiseCtrlHighSetLimitSpeed "Maximum vehicle velocity at which cruise can be set.";
CM_ SG_ 2566843648 MaxVehicleSpeedLimit "Maximum vehicle velocity allowed.";
CM_ BO_ 2566836224 "Test results for non-continously monitored systems.";
CM_ SG_ 2566836224 TestLimitMinimum "The threshold which the test value must be above to pass the test.";
CM_ SG_ 2566836224 TestLimitMaximum "The threshold which the test value must be below to pass the test.";
CM_ SG_ 2566836224 TestValue "The test value collected during the test.";
CM_ SG_ 2566836224 TestType "Identifies the non-continously monitored component identifier that was tested.";
CM_ SG_ 2566836224 TestIdentifier "Designates the test to be run.";
CM_ BO_ 2565078784 "Command non-continously monitored test
changed the DA to All";
CM_ SG_ 2565078784 FMIIdentifyCmpntSysSpecificTest "THis Parameter identifies the failure mode identifier wich represents the tests that shall be run in the compoent system that will be tested
Added to the db ver1";
CM_ SG_ 2565078784 SPNIdentifyingComponentSystem "This parameter identfies the compoent system that will be tested.
Added to the ver1 db";
CM_ SG_ 2565078784 TestIdentifier "Designates the test to be run.";
CM_ BO_ 2566835968 "Continously monitored systems test results";
CM_ SG_ 2566835968 SPN5 "SPN #5 (Conversion Version 4)";
CM_ SG_ 2566835968 SPN4 "SPN #4 (Conversion Version 4)";
CM_ SG_ 2566835968 SPN3 "SPN #3 (Conversion Version 4)";
CM_ SG_ 2566835968 SPN2 "SPN #2 (Conversion Version 4)";
CM_ SG_ 2566835968 SPN1 "SPN #1 (Conversion Version 4)";
CM_ SG_ 2566835968 RedStopLampStatus "This lamp is uesed to relay trouble code information that is of a severe enought condition that it warrants stopping the vehicle.";
CM_ SG_ 2566835968 ProtectLampStatus "This lamp is used to relay trouble code informatio that is reporting a problem with a vehicle system that is most
probably not electronic subsystem related.";
CM_ SG_ 2566835968 AmberWarningLampStatus "This lamp is used to relay trouble code information that is reporting a problem with the vehicle system but the vehicle need
not be immediately stopped.";
CM_ SG_ 2566835968 MalfunctionIndicatorLampStatus "A lamp used to relay only emissions-related trouble code information.";
CM_ SG_ 2566835968 FailureModeIdentifier5 "The FMI defines the type of failure detected in the subsystem identified by an SPN.";
CM_ SG_ 2566835968 FailureModeIdentifier4 "The FMI defines the type of failure detected in the subsystem identified by an SPN.";
CM_ SG_ 2566835968 FailureModeIdentifier3 "The FMI defines the type of failure detected in the subsystem identified by an SPN.";
CM_ SG_ 2566835968 FailureModeIdentifier2 "The FMI defines the type of failure detected in the subsystem identified by an SPN.";
CM_ SG_ 2566835968 OccurenceCount5 "The 7 bit occurence count field contains the number of times a fault has gone from active to previously active.";
CM_ SG_ 2566835968 OccurenceCount4 "The 7 bit occurence count field contains the number of times a fault has gone from active to previously active.";
CM_ SG_ 2566835968 OccurenceCount3 "The 7 bit occurence count field contains the number of times a fault has gone from active to previously active.";
CM_ SG_ 2566835968 OccurenceCount2 "The 7 bit occurence count field contains the number of times a fault has gone from active to previously active.";
CM_ SG_ 2566835968 OccurenceCount1 "The 7 bit occurence count field contains the number of times a fault has gone from active to previously active.";
CM_ SG_ 2566835968 FailureModeIdentifier1 "The FMI defines the type of failure detected in the subsystem identified by an SPN.";
CM_ SG_ 2566835968 SPN5High "SPN #5 (Conversion Version 4)";
CM_ SG_ 2566835968 SPN4High "SPN #4 (Conversion Version 4)";
CM_ SG_ 2566835968 SPN3High "SPN #3 (Conversion Version 4)";
CM_ SG_ 2566835968 SPN2High "SPN #2 (Conversion Version 4)";
CM_ SG_ 2566835968 SPN1High "SPN #1 (Conversion Version 4)";
CM_ BO_ 2566835712 "Diagnostic readiness 1";
CM_ SG_ 2566835712 PMFilterMonStatus "Newly added bit to the spn 1223
";
CM_ SG_ 2566835712 NOxCnvrtctlystMonStatus "Newly added bit to the spn 1223
";
CM_ SG_ 2566835712 NHMCCnvrtctlystMonStatus "Newly added bit to the spn 1223
";
CM_ SG_ 2566835712 BstPressCtrlSystemMonStatus "Newly added bit to the spn 1223
";
CM_ SG_ 2566835712 NOxCnvrtctlystMonSupp "Newly added bit to the spn 3305
";
CM_ SG_ 2566835712 PMFilterMonSupp "Newly added bit to the spn 1222

";
CM_ SG_ 2566835712 NHMCCnvrtctlystMonSupp "Newly added bit to the spn 3305
";
CM_ SG_ 2566835712 BstPressCtrlSystemMonSupp "Newly added bit to the spn 1222
";
CM_ SG_ 2566835712 OBDCompliance "Identifies the OBD compliance capabilityof the responding controller.";
CM_ SG_ 2566835712 PreviouslyActiveTroubleCodes "Identifies the number of previously active trouble codes that are present in a specific controller.";
CM_ SG_ 2566835712 ActiveTroubleCodes "Identifies the number of active trouble codes that are present in a specific controller.";
CM_ BO_ 2566835456 "Freeze frame parameters";
CM_ SG_ 2566835456 SPN1 "SPN #1 (Conversion Version 4)";
CM_ SG_ 2566835456 EngSpeed "Actual engine speed which is calculated over a minimum crankshaft angle of 720 degrees divided by the number of cylinders.";
CM_ SG_ 2566835456 EngTurboBoostPress "Gage pressure of air measured downstream on the compressor discharge side of the turbocharger.";
CM_ SG_ 2566835456 WheelBasedVehicleSpeed "Speed of the vehicle as calculated from wheel or tailshaft speed.";
CM_ SG_ 2566835456 OccurenceCount1 "The 7 bit occurence count field contains the number of times a fault has gone from active to previously active.";
CM_ SG_ 2566835456 FailureModeIdentifier1 "The FMI defines the type of failure detected in the subsystem identified by an SPN.";
CM_ SG_ 2566835456 FreezeFrameLength "The freeze frame length shall be equal to the number of bytes in the required parameters plus the number of bytes in the
manufacturer specific parameters.";
CM_ SG_ 2566835456 EngTorqueMode "State signal which indicates which engine torque mode is currently generating, limiting, or controlling the torque.";
CM_ SG_ 2566835456 SPN1High "SPN #1 (Conversion Version 4)";
CM_ BO_ 2566835200 "Diagnostic data clear/reset of previously active DTCs.";
CM_ BO_ 2566763776 "Previously active emission related faults.";
CM_ SG_ 2566763776 FailureModeIdentifier5 "The FMI defines the type of failure detected in the subsystem identified by an SPN.";
CM_ SG_ 2566763776 FailureModeIdentifier4 "The FMI defines the type of failure detected in the subsystem identified by an SPN.";
CM_ SG_ 2566763776 FailureModeIdentifier3 "The FMI defines the type of failure detected in the subsystem identified by an SPN.";
CM_ SG_ 2566763776 FailureModeIdentifier2 "The FMI defines the type of failure detected in the subsystem identified by an SPN.";
CM_ SG_ 2566763776 FailureModeIdentifier1 "The FMI defines the type of failure detected in the subsystem identified by an SPN.";
CM_ SG_ 2566763776 FlashRedStopLamp "This parameter provides the capability to flash the RSL (SPN 3039).";
CM_ SG_ 2566763776 FlashProtectLamp "This parameter provides the capability to flash the engine protect lamp (SPN 3041).";
CM_ SG_ 2566763776 FlashMalfuncIndicatorLamp "This parameter provides the capability to flash the MIL (SPN 3038).";
CM_ SG_ 2566763776 FlashAmberWarningLamp "This parameter provides the capability to flash the AWL (SPN 3040). ";
CM_ SG_ 2566763776 SPN5 "SPN #5 (Conversion Version 4)";
CM_ SG_ 2566763776 SPN4 "SPN #4 (Conversion Version 4)";
CM_ SG_ 2566763776 SPN3 "SPN #3 (Conversion Version 4)";
CM_ SG_ 2566763776 SPN2 "SPN #2 (Conversion Version 4)";
CM_ SG_ 2566763776 SPN1 "SPN #1 (Conversion Version 4)";
CM_ SG_ 2566763776 RedStopLampStatus "This lamp is uesed to relay trouble code information that is of a severe enought condition that it warrants stopping the vehicle.";
CM_ SG_ 2566763776 ProtectLampStatus "This lamp is used to relay trouble code informatio that is reporting a problem with a vehicle system that is most
probably not electronic subsystem related.";
CM_ SG_ 2566763776 AmberWarningLampStatus "This lamp is used to relay trouble code information that is reporting a problem with the vehicle system but the vehicle need
not be immediately stopped.";
CM_ SG_ 2566763776 MalfunctionIndicatorLampStatus "A lamp used to relay only emissions-related trouble code information.";
CM_ SG_ 2566763776 OccurenceCount1 "The 7 bit occurence count field contains the number of times a fault has gone from active to previously active.";
CM_ SG_ 2566763776 OccurenceCount5 "The 7 bit occurence count field contains the number of times a fault has gone from active to previously active.";
CM_ SG_ 2566763776 OccurenceCount4 "The 7 bit occurence count field contains the number of times a fault has gone from active to previously active.";
CM_ SG_ 2566763776 OccurenceCount3 "The 7 bit occurence count field contains the number of times a fault has gone from active to previously active.";
CM_ SG_ 2566763776 OccurenceCount2 "The 7 bit occurence count field contains the number of times a fault has gone from active to previously active.";
CM_ SG_ 2566763776 SPN5High "SPN #5 (Conversion Version 4)";
CM_ SG_ 2566763776 SPN4High "SPN #4 (Conversion Version 4)";
CM_ SG_ 2566763776 SPN3High "SPN #3 (Conversion Version 4)";
CM_ SG_ 2566763776 SPN2High "SPN #2 (Conversion Version 4)";
CM_ SG_ 2566763776 SPN1High "SPN #1 (Conversion Version 4)";
CM_ BO_ 2562850304 "Diagnostic readiness 2";
CM_ SG_ 2562850304 TimeSinceDTCsCleared "Time accumulated since DTCs were cleared (via an external test equipment or possibly, a battery disconnect) (SPN=?).
corrected the spn from 3145 to 3296.version1 database";
CM_ SG_ 2562850304 MinutesRunByEngineMILActivated "Accumulated count (in minutes) while the MIL is activated (on) (SPN=?).
corrected the spn from 3144 to 3295 version1";
CM_ SG_ 2562850304 DistanceSinceDTCsCleared "Distance accumulated since DTCs were cleared (SPN=?)
version 1 corrected the spn from 3143 to 3294 ";
CM_ SG_ 2562850304 DistanceWhileMILisActivated "The kilometers accumulated while the MIL is activated (SPN 3060).";
CM_ BO_ 2562915840 "Monitor Performance Ratio";
CM_ SG_ 2562915840 ApplSysMonitorDenominator "The number of times a vehicle has been operated that constitutes a driving cycle where this Applicable System Monitor could be operated per regulatory requirements (SPN 3068).";
CM_ SG_ 2562915840 ApplSysMonitorNumerator "The number of times a vehicle has been operated such that all conditions necessary for the Applicable System Monitor to detect a malfunction have been encountered (SPN 3067).";
CM_ SG_ 2562915840 SPNofApplSysMonitor "Contain the SPN of the system monitor for which Monitor ratio is being reported (SPN 3066).";
CM_ SG_ 2562915840 OBDMonitoringCondEncountered "Displays the number of times that the vehicle has been operated in the specified OBD monitoring conditions (SPN 3049).";
CM_ SG_ 2562915840 IgnitionCycleCounter "A single counter that defines the number of ignition cycles (SPN 3048).";
CM_ BO_ 2566834944 "Previously active diagnostic trouble codes";
CM_ SG_ 2566834944 FailureModeIdentifier5 "The FMI defines the type of failure detected in the subsystem identified by an SPN.";
CM_ SG_ 2566834944 FailureModeIdentifier4 "The FMI defines the type of failure detected in the subsystem identified by an SPN.";
CM_ SG_ 2566834944 FailureModeIdentifier3 "The FMI defines the type of failure detected in the subsystem identified by an SPN.";
CM_ SG_ 2566834944 FailureModeIdentifier2 "The FMI defines the type of failure detected in the subsystem identified by an SPN.";
CM_ SG_ 2566834944 FailureModeIdentifier1 "The FMI defines the type of failure detected in the subsystem identified by an SPN.";
CM_ SG_ 2566834944 FlashRedStopLamp "This parameter provides the capability to flash the RSL (SPN 3039).";
CM_ SG_ 2566834944 FlashProtectLamp "This parameter provides the capability to flash the engine protect lamp (SPN 3041).";
CM_ SG_ 2566834944 FlashMalfuncIndicatorLamp "This parameter provides the capability to flash the MIL (SPN 3038).";
CM_ SG_ 2566834944 FlashAmberWarningLamp "This parameter provides the capability to flash the AWL (SPN 3040). ";
CM_ SG_ 2566834944 SPN5 "SPN #5 (Conversion Version 4)";
CM_ SG_ 2566834944 SPN4 "SPN #4 (Conversion Version 4)";
CM_ SG_ 2566834944 SPN3 "SPN #3 (Conversion Version 4)";
CM_ SG_ 2566834944 SPN2 "SPN #2 (Conversion Version 4)";
CM_ SG_ 2566834944 SPN1 "SPN #1 (Conversion Version 4)";
CM_ SG_ 2566834944 RedStopLampStatus "This lamp is uesed to relay trouble code information that is of a severe enought condition that it warrants stopping the vehicle.";
CM_ SG_ 2566834944 ProtectLampStatus "This lamp is used to relay trouble code informatio that is reporting a problem with a vehicle system that is most
probably not electronic subsystem related.";
CM_ SG_ 2566834944 AmberWarningLampStatus "This lamp is used to relay trouble code information that is reporting a problem with the vehicle system but the vehicle need
not be immediately stopped.";
CM_ SG_ 2566834944 MalfunctionIndicatorLampStatus "A lamp used to relay only emissions-related trouble code information.";
CM_ SG_ 2566834944 OccurenceCount1 "The 7 bit occurence count field contains the number of times a fault has gone from active to previously active.";
CM_ SG_ 2566834944 OccurenceCount5 "The 7 bit occurence count field contains the number of times a fault has gone from active to previously active.";
CM_ SG_ 2566834944 OccurenceCount4 "The 7 bit occurence count field contains the number of times a fault has gone from active to previously active.";
CM_ SG_ 2566834944 OccurenceCount3 "The 7 bit occurence count field contains the number of times a fault has gone from active to previously active.";
CM_ SG_ 2566834944 OccurenceCount2 "The 7 bit occurence count field contains the number of times a fault has gone from active to previously active.";
CM_ SG_ 2566834944 SPN5High "SPN #5 (Conversion Version 4)";
CM_ SG_ 2566834944 SPN4High "SPN #4 (Conversion Version 4)";
CM_ SG_ 2566834944 SPN3High "SPN #3 (Conversion Version 4)";
CM_ SG_ 2566834944 SPN2High "SPN #2 (Conversion Version 4)";
CM_ SG_ 2566834944 SPN1High "SPN #1 (Conversion Version 4)";
CM_ BO_ 2631078400 "Calibration Information";
CM_ BO_ 2566837248 "Emissions-related active diagnostic trouble codes.";
CM_ SG_ 2566837248 FlashRedStopLamp "This parameter provides the capability to flash the RSL (SPN 3039).";
CM_ SG_ 2566837248 FlashProtectLamp "This parameter provides the capability to flash the engine protect lamp (SPN 3041).";
CM_ SG_ 2566837248 FlashMalfuncIndicatorLamp "This parameter provides the capability to flash the MIL (SPN 3038).";
CM_ SG_ 2566837248 FlashAmberWarningLamp "This parameter provides the capability to flash the AWL (SPN 3040). ";
CM_ SG_ 2566837248 FailureModeIdentifier5 "The FMI defines the type of failure detected in the subsystem identified by an SPN.";
CM_ SG_ 2566837248 FailureModeIdentifier4 "The FMI defines the type of failure detected in the subsystem identified by an SPN.";
CM_ SG_ 2566837248 FailureModeIdentifier3 "The FMI defines the type of failure detected in the subsystem identified by an SPN.";
CM_ SG_ 2566837248 FailureModeIdentifier2 "The FMI defines the type of failure detected in the subsystem identified by an SPN.";
CM_ SG_ 2566837248 FailureModeIdentifier1 "The FMI defines the type of failure detected in the subsystem identified by an SPN.";
CM_ SG_ 2566837248 SPN5 "SPN #5 (Conversion Version 4)";
CM_ SG_ 2566837248 SPN4 "SPN #4 (Conversion Version 4)";
CM_ SG_ 2566837248 SPN3 "SPN #3 (Conversion Version 4)";
CM_ SG_ 2566837248 SPN2 "SPN #2 (Conversion Version 4)";
CM_ SG_ 2566837248 SPN1 "SPN #1 (Conversion Version 4)";
CM_ SG_ 2566837248 RedStopLampStatus "This lamp is uesed to relay trouble code information that is of a severe enought condition that it warrants stopping the vehicle.";
CM_ SG_ 2566837248 ProtectLampStatus "This lamp is used to relay trouble code informatio that is reporting a problem with a vehicle system that is most
probably not electronic subsystem related.";
CM_ SG_ 2566837248 AmberWarningLampStatus "This lamp is used to relay trouble code information that is reporting a problem with the vehicle system but the vehicle need
not be immediately stopped.";
CM_ SG_ 2566837248 MalfunctionIndicatorLampStatus "A lamp used to relay only emissions-related trouble code information.";
CM_ SG_ 2566837248 OccurenceCount1 "The 7 bit occurence count field contains the number of times a fault has gone from active to previously active.";
CM_ SG_ 2566837248 OccurenceCount5 "The 7 bit occurence count field contains the number of times a fault has gone from active to previously active.";
CM_ SG_ 2566837248 OccurenceCount4 "The 7 bit occurence count field contains the number of times a fault has gone from active to previously active.";
CM_ SG_ 2566837248 OccurenceCount3 "The 7 bit occurence count field contains the number of times a fault has gone from active to previously active.";
CM_ SG_ 2566837248 OccurenceCount2 "The 7 bit occurence count field contains the number of times a fault has gone from active to previously active.";
CM_ SG_ 2566837248 SPN5High "SPN #5 (Conversion Version 4)";
CM_ SG_ 2566837248 SPN4High "SPN #4 (Conversion Version 4)";
CM_ SG_ 2566837248 SPN3High "SPN #3 (Conversion Version 4)";
CM_ SG_ 2566837248 SPN2High "SPN #2 (Conversion Version 4)";
CM_ SG_ 2566837248 SPN1High "SPN #1 (Conversion Version 4)";
CM_ BO_ 2566836992 "Diagnostic data clear/Reset for active DTCs";
CM_ BO_ 2566836736 "Non-continously monitored systems test identifiers support";
CM_ SG_ 2566836736 TestIdentifierSupported "Indicates the test identifiers that the controller supports.";
CM_ BO_ 2565603072 "Transport Protocol - Data Transfer";
CM_ BO_ 2566845696 "Ambient Conditions";
CM_ SG_ 2566845696 RoadSurfaceTemp "Indicated temperature of road surface over which vehicle is operating.";
CM_ SG_ 2566845696 EngAirInletTemp "Temperature of air entering vehicle air induction system.";
CM_ SG_ 2566845696 AmbientAirTemp "Temperature of air surrounding vehicle.";
CM_ SG_ 2566845696 CabInteriorTemp "Temperature of air inside the part of the vehicle that encloses the driver and vehicle operating controls.";
CM_ SG_ 2566845696 BarometricPress "Absolute air pressure of the atmosphere.";
CM_ BO_ 2633935360 "Alternate Fuel 2";
CM_ SG_ 2633935360 EngDsiredAbsIntakeManifoldPress "The desired absolute intake manifold pressure of the engine.";
CM_ BO_ 2432593706 "Adaptive Cruise Control";
CM_ SG_ 2432593706 RoadCurvature "Estimated value of the current road curvature for use by the adaptive cruise control system.";
CM_ SG_ 2432593706 AdptveCruiseCtrlSetDistanceMode "Selected distance mode for adaptive cruise control.";
CM_ SG_ 2432593706 AdaptiveCruiseCtrlMode "This parameter is used to indicate the current state, or mode, of operation by the Adaptive Cruise Control (ACC) device.";
CM_ SG_ 2432593706 AdaptiveCruiseCtrlSetSpeed "Value of the desired (chosen) velocity of the adaptive cruise control system.";
CM_ SG_ 2432593706 DistanceToForwardVehicle "Distance to the preceding vehicle situated within 250 m in the same lane and moving in the same direction.";
CM_ SG_ 2432593706 SpeedOfForwardVehicle "Absolute velocity of the preceding vehicle situated within 250 m in the same lane and moving in the same direction.";
CM_ BO_ 2566763520 "After Treatment Intake Gas 2";
CM_ SG_ 2566763520 ParticulateTrapIntakeGasTemp "Newly added to db ver1";
CM_ SG_ 2566763520 ExhaustGasTemp1 "The reading from the exhaust gas temperature sensor located farthest upstream in the after-treatment system.";
CM_ BO_ 2566763008 "After Treatment Intermediate Gas 1";
CM_ SG_ 2566763008 PrtcltTrpIntrmdtGsTmpPrlmnryFMI "changed the spn from 3288 to 3254 version 1 database";
CM_ SG_ 2566763008 PrtcltTrpDltPressPreliminaryFMI "changed the spn from 3287 to 3253";
CM_ SG_ 2566763008 ExhaustGasTemp2PreliminaryFMI "changed the spn from 3286 to 3252 in version 1 database";
CM_ SG_ 2566763008 ParticulateTrapDiffPress "Exhaust differential pressure measured between the intake and exhaust of a particulate trap.
changed the spn from 3285 to 3251 version1";
CM_ SG_ 2566763008 PrtclateTrapIntermediateGasTemp "Temperature of engine combustion byproducts at a mid-point in the particulate trap.
Changed the SPN from 3284 to 3250 version 1
";
CM_ SG_ 2566763008 ExhaustGasTemp2 "changed the SPN from 3283 to 3249";
CM_ BO_ 2566763264 "After Treatment Outlet Gas 2";
CM_ SG_ 2566763264 ExhaustGasTemp3PreliminaryFMI "corrected the spn from 3281 to 3247";
CM_ SG_ 2566763264 ParticulateTrapOutletGasTemp "Temperature of engine combustion byproducts leaving the particulate trap exhaust.
corrected the spn from 3280 to 3246";
CM_ SG_ 2566763264 ExhaustGasTemp3 "The reading from the exhaust gas temperature sensor located farthest downstream in the after-treatment system.
corrected the database from spn 3279 to 3245";
BA_DEF_ SG_  "Status" STRING ;
BA_DEF_ SG_  "Variable" STRING ;
BA_DEF_ SG_  "SigType" STRING ;
BA_DEF_ SG_  "SPN" INT 0 524287;
BA_DEF_ SG_  "DDI" INT 0 65535;
BA_DEF_ SG_  "SAEDocument" STRING ;
BA_DEF_ BO_  "GenMsgRequestable" INT 0 1;
BA_DEF_ BO_  "GenMsgSendType" ENUM  "cyclic","reserved","cyclicIfActive","reserved","reserved","reserved","reserved","On Request","noMsgSendType";
BA_DEF_ BO_  "VFrameFormat" ENUM  "StandardCAN","ExtendedCAN","reserved","J1939PG";
BA_DEF_ BO_  "SingleFrame" INT 0 1;
BA_DEF_ BO_  "GenMsgCycleTime" INT 0 3600000;
BA_DEF_ BO_  "SAE_Document" STRING ;
BA_DEF_DEF_  "Status" "";
BA_DEF_DEF_  "Variable" "";
BA_DEF_DEF_  "SigType" "";
BA_DEF_DEF_  "SPN" 0;
BA_DEF_DEF_  "DDI" 0;
BA_DEF_DEF_  "SAEDocument" "";
BA_DEF_DEF_  "GenMsgRequestable" 1;
BA_DEF_DEF_  "GenMsgSendType" "noMsgSendType";
BA_DEF_DEF_  "VFrameFormat" "J1939PG";
BA_DEF_DEF_  "SingleFrame" 1;
BA_DEF_DEF_  "GenMsgCycleTime" 0;
BA_DEF_DEF_  "SAE_Document" "";
BA_ "SAE_Document" BO_ 2566841088 "J1939-71";
BA_ "SAE_Document" BO_ 2566768128 "J1939-71";
BA_ "GenMsgSendType" BO_ 2564816929 0;
BA_ "GenMsgCycleTime" BO_ 2564816929 1000;
BA_ "SAE_Document" BO_ 2564816929 "J1939-71";
BA_ "GenMsgSendType" BO_ 2566843136 7;
BA_ "SAE_Document" BO_ 2566843136 "J1939-71";
BA_ "GenMsgSendType" BO_ 2566844672 0;
BA_ "GenMsgCycleTime" BO_ 2566844672 100;
BA_ "SAE_Document" BO_ 2566844672 "J1939-71";
BA_ "GenMsgSendType" BO_ 2566843648 7;
BA_ "SAE_Document" BO_ 2566843648 "J1939-71";
BA_ "SAE_Document" BO_ 2566836224 "J1939-73";
BA_ "SAE_Document" BO_ 2565078784 "J1939-73";
BA_ "SAE_Document" BO_ 2566835968 "J1939-73";
BA_ "SAE_Document" BO_ 2566835712 "J1939-73";
BA_ "SAE_Document" BO_ 2566835456 "J1939-73";
BA_ "SAE_Document" BO_ 2566835200 "J1939-73";
BA_ "SAE_Document" BO_ 2566763776 "J1939-73";
BA_ "SAE_Document" BO_ 2562850304 "J1939-73";
BA_ "SAE_Document" BO_ 2562915840 "J1939-73";
BA_ "SAE_Document" BO_ 2566834944 "J1939-73";
BA_ "SAE_Document" BO_ 2631078400 "J1939-73";
BA_ "SAE_Document" BO_ 2566837248 "J1939-73";
BA_ "SAE_Document" BO_ 2566836992 "J1939-73";
BA_ "SAE_Document" BO_ 2566836736 "J1939-73";
BA_ "SAE_Document" BO_ 2565603072 "J1939-21";
BA_ "GenMsgSendType" BO_ 2566845696 0;
BA_ "GenMsgCycleTime" BO_ 2566845696 1000;
BA_ "SAE_Document" BO_ 2566845696 "J1939-71";
BA_ "GenMsgSendType" BO_ 2633935360 7;
BA_ "SAE_Document" BO_ 2633935360 "J1939-71";
BA_ "GenMsgSendType" BO_ 2432593706 0;
BA_ "GenMsgCycleTime" BO_ 2432593706 100;
BA_ "SAE_Document" BO_ 2432593706 "J1939-71";
BA_ "GenMsgSendType" BO_ 2566763520 0;
BA_ "GenMsgCycleTime" BO_ 2566763520 500;
BA_ "SAE_Document" BO_ 2566763520 "J1939-71";
BA_ "GenMsgSendType" BO_ 2566763008 0;
BA_ "GenMsgCycleTime" BO_ 2566763008 500;
BA_ "SAE_Document" BO_ 2566763008 "J1939-71";
BA_ "GenMsgSendType" BO_ 2566763264 0;
BA_ "GenMsgCycleTime" BO_ 2566763264 500;
BA_ "SAE_Document" BO_ 2566763264 "J1939-71";
BA_ "SigType" SG_ 2566841088 SupportTSC1CtrlPurposeGroup4Of4 "RANGE";
BA_ "SPN" SG_ 2566841088 SupportTSC1CtrlPurposeGroup4Of4 3348;
BA_ "SAEDocument" SG_ 2566841088 SupportTSC1CtrlPurposeGroup4Of4 "J1939-71";
BA_ "Status" SG_ 2566841088 SupportTSC1CtrlPurposeGroup4Of4 "Not needed";
BA_ "SigType" SG_ 2566841088 SupportVariableRateTSC1Message "RANGE";
BA_ "SPN" SG_ 2566841088 SupportVariableRateTSC1Message 3344;
BA_ "SAEDocument" SG_ 2566841088 SupportVariableRateTSC1Message "J1939-71";
BA_ "Status" SG_ 2566841088 SupportVariableRateTSC1Message "Not needed";
BA_ "SigType" SG_ 2566841088 SupportTSC1CtrlPurposeGroup3Of4 "RANGE";
BA_ "SPN" SG_ 2566841088 SupportTSC1CtrlPurposeGroup3Of4 3347;
BA_ "SAEDocument" SG_ 2566841088 SupportTSC1CtrlPurposeGroup3Of4 "J1939-71";
BA_ "Status" SG_ 2566841088 SupportTSC1CtrlPurposeGroup3Of4 "Not needed";
BA_ "SigType" SG_ 2566841088 SupportTSC1CtrlPurposeGroup2Of4 "RANGE";
BA_ "SPN" SG_ 2566841088 SupportTSC1CtrlPurposeGroup2Of4 3346;
BA_ "SAEDocument" SG_ 2566841088 SupportTSC1CtrlPurposeGroup2Of4 "J1939-71";
BA_ "Status" SG_ 2566841088 SupportTSC1CtrlPurposeGroup2Of4 "Not needed";
BA_ "SigType" SG_ 2566841088 SupportTSC1CtrlPurposeGroup1Of4 "RANGE";
BA_ "SPN" SG_ 2566841088 SupportTSC1CtrlPurposeGroup1Of4 3345;
BA_ "SAEDocument" SG_ 2566841088 SupportTSC1CtrlPurposeGroup1Of4 "J1939-71";
BA_ "Status" SG_ 2566841088 SupportTSC1CtrlPurposeGroup1Of4 "Not needed";
BA_ "Variable" SG_ 2566841088 EngDefaultTorqueLimit "Com_dEngCfgPByte6";
BA_ "Status" SG_ 2566841088 EngDefaultTorqueLimit "3.4.0";
BA_ "SigType" SG_ 2566841088 EngDefaultTorqueLimit "RANGE";
BA_ "SPN" SG_ 2566841088 EngDefaultTorqueLimit 1846;
BA_ "SAEDocument" SG_ 2566841088 EngDefaultTorqueLimit "J1939-71";
BA_ "SigType" SG_ 2566841088 EngMomentOfInertia "RANGE";
BA_ "SPN" SG_ 2566841088 EngMomentOfInertia 1794;
BA_ "SAEDocument" SG_ 2566841088 EngMomentOfInertia "J1939-71";
BA_ "Status" SG_ 2566841088 EngMomentOfInertia "3.4.0";
BA_ "Variable" SG_ 2566841088 EngMomentOfInertia "Function of Tra_stTraType_C";
BA_ "SigType" SG_ 2566841088 EngExRngRqdSpdCtrlRngUpperLimit "RANGE";
BA_ "SPN" SG_ 2566841088 EngExRngRqdSpdCtrlRngUpperLimit 1712;
BA_ "SAEDocument" SG_ 2566841088 EngExRngRqdSpdCtrlRngUpperLimit "J1939-71";
BA_ "Status" SG_ 2566841088 EngExRngRqdSpdCtrlRngUpperLimit "Not needed";
BA_ "Status" SG_ 2566841088 EngRqdTorqueCtrlRangeUpperLimit "3.4.0";
BA_ "Variable" SG_ 2566841088 EngRqdTorqueCtrlRangeUpperLimit "Frm_trqLimMaxEngCfg_C";
BA_ "SigType" SG_ 2566841088 EngRqdTorqueCtrlRangeUpperLimit "RANGE";
BA_ "SPN" SG_ 2566841088 EngRqdTorqueCtrlRangeUpperLimit 538;
BA_ "SAEDocument" SG_ 2566841088 EngRqdTorqueCtrlRangeUpperLimit "J1939-71";
BA_ "Status" SG_ 2566841088 EngRqdTorqueCtrlRangeLowerLimit "3.4.0";
BA_ "Variable" SG_ 2566841088 EngRqdTorqueCtrlRangeLowerLimit "Frm_trqLimMinEngCfg_C";
BA_ "SigType" SG_ 2566841088 EngRqdTorqueCtrlRangeLowerLimit "RANGE";
BA_ "SPN" SG_ 2566841088 EngRqdTorqueCtrlRangeLowerLimit 537;
BA_ "SAEDocument" SG_ 2566841088 EngRqdTorqueCtrlRangeLowerLimit "J1939-71";
BA_ "SigType" SG_ 2566841088 EngRqedSpeedCtrlRangeUpperLimit "RANGE";
BA_ "SPN" SG_ 2566841088 EngRqedSpeedCtrlRangeUpperLimit 536;
BA_ "SAEDocument" SG_ 2566841088 EngRqedSpeedCtrlRangeUpperLimit "J1939-71";
BA_ "Status" SG_ 2566841088 EngRqedSpeedCtrlRangeUpperLimit "3.5.0";
BA_ "Variable" SG_ 2566841088 EngRqedSpeedCtrlRangeUpperLimit "HLSDem_nProShftEngMax";
BA_ "SigType" SG_ 2566841088 EngRqedSpeedCtrlRangeLowerLimit "RANGE";
BA_ "SPN" SG_ 2566841088 EngRqedSpeedCtrlRangeLowerLimit 535;
BA_ "SAEDocument" SG_ 2566841088 EngRqedSpeedCtrlRangeLowerLimit "J1939-71";
BA_ "Status" SG_ 2566841088 EngRqedSpeedCtrlRangeLowerLimit "3.4.0";
BA_ "Variable" SG_ 2566841088 EngRqedSpeedCtrlRangeLowerLimit "HLSDem_nSetPLoDia_C";
BA_ "Variable" SG_ 2566841088 EngMxMomentaryOverrideTimeLimit "RngMod_tiMaxCfgPnt7";
BA_ "SigType" SG_ 2566841088 EngMxMomentaryOverrideTimeLimit "RANGE";
BA_ "SPN" SG_ 2566841088 EngMxMomentaryOverrideTimeLimit 534;
BA_ "SAEDocument" SG_ 2566841088 EngMxMomentaryOverrideTimeLimit "J1939-71";
BA_ "Status" SG_ 2566841088 EngMxMomentaryOverrideTimeLimit "2.1.0";
BA_ "Variable" SG_ 2566841088 EngMxMmntaryOverrideSpeedPoint7 "HLSDem_nEngCfgPnt7";
BA_ "SigType" SG_ 2566841088 EngMxMmntaryOverrideSpeedPoint7 "RANGE";
BA_ "SPN" SG_ 2566841088 EngMxMmntaryOverrideSpeedPoint7 533;
BA_ "SAEDocument" SG_ 2566841088 EngMxMmntaryOverrideSpeedPoint7 "J1939-71";
BA_ "Status" SG_ 2566841088 EngMxMmntaryOverrideSpeedPoint7 "2.1.0";
BA_ "Variable" SG_ 2566841088 EngReferenceTorque "Frm_trqRef_C";
BA_ "SigType" SG_ 2566841088 EngReferenceTorque "RANGE";
BA_ "SPN" SG_ 2566841088 EngReferenceTorque 544;
BA_ "SAEDocument" SG_ 2566841088 EngReferenceTorque "J1939-71";
BA_ "Status" SG_ 2566841088 EngReferenceTorque "2.1.0";
BA_ "Variable" SG_ 2566841088 EngSpeedAtHighIdlePoint6 "HLSDem_nEngCfgPnt6";
BA_ "SigType" SG_ 2566841088 EngSpeedAtHighIdlePoint6 "RANGE";
BA_ "SPN" SG_ 2566841088 EngSpeedAtHighIdlePoint6 532;
BA_ "SAEDocument" SG_ 2566841088 EngSpeedAtHighIdlePoint6 "J1939-71";
BA_ "Status" SG_ 2566841088 EngSpeedAtHighIdlePoint6 "2.1.0";
BA_ "Variable" SG_ 2566841088 EngGainOfEndspeedGovernor "HLSDem_facFdbk";
BA_ "SigType" SG_ 2566841088 EngGainOfEndspeedGovernor "RANGE";
BA_ "SPN" SG_ 2566841088 EngGainOfEndspeedGovernor 545;
BA_ "SAEDocument" SG_ 2566841088 EngGainOfEndspeedGovernor "J1939-71";
BA_ "Status" SG_ 2566841088 EngGainOfEndspeedGovernor "2.1.0";
BA_ "Variable" SG_ 2566841088 EngPercentTorqueAtPoint5 "RngMod_trqCfgPnt5";
BA_ "SigType" SG_ 2566841088 EngPercentTorqueAtPoint5 "RANGE";
BA_ "SPN" SG_ 2566841088 EngPercentTorqueAtPoint5 543;
BA_ "SAEDocument" SG_ 2566841088 EngPercentTorqueAtPoint5 "J1939-71";
BA_ "Status" SG_ 2566841088 EngPercentTorqueAtPoint5 "2.1.0";
BA_ "Variable" SG_ 2566841088 EngSpeedAtPoint5 "RngMod_nCfgPnt5";
BA_ "SigType" SG_ 2566841088 EngSpeedAtPoint5 "RANGE";
BA_ "SPN" SG_ 2566841088 EngSpeedAtPoint5 531;
BA_ "SAEDocument" SG_ 2566841088 EngSpeedAtPoint5 "J1939-71";
BA_ "Status" SG_ 2566841088 EngSpeedAtPoint5 "2.1.0";
BA_ "Variable" SG_ 2566841088 EngPercentTorqueAtPoint4 "RngMod_trqCfgPnt4";
BA_ "SigType" SG_ 2566841088 EngPercentTorqueAtPoint4 "RANGE";
BA_ "SPN" SG_ 2566841088 EngPercentTorqueAtPoint4 542;
BA_ "SAEDocument" SG_ 2566841088 EngPercentTorqueAtPoint4 "J1939-71";
BA_ "Status" SG_ 2566841088 EngPercentTorqueAtPoint4 "2.1.0";
BA_ "Variable" SG_ 2566841088 EngSpeedAtPoint4 "RngMod_nCfgPnt4";
BA_ "SigType" SG_ 2566841088 EngSpeedAtPoint4 "RANGE";
BA_ "SPN" SG_ 2566841088 EngSpeedAtPoint4 530;
BA_ "SAEDocument" SG_ 2566841088 EngSpeedAtPoint4 "J1939-71";
BA_ "Status" SG_ 2566841088 EngSpeedAtPoint4 "2.1.0";
BA_ "Variable" SG_ 2566841088 EngPercentTorqueAtPoint3 "RngMod_trqCfgPnt3";
BA_ "SigType" SG_ 2566841088 EngPercentTorqueAtPoint3 "RANGE";
BA_ "SPN" SG_ 2566841088 EngPercentTorqueAtPoint3 541;
BA_ "SAEDocument" SG_ 2566841088 EngPercentTorqueAtPoint3 "J1939-71";
BA_ "Status" SG_ 2566841088 EngPercentTorqueAtPoint3 "2.1.0";
BA_ "Variable" SG_ 2566841088 EngSpeedAtPoint3 "RngMod_nCfgPnt3";
BA_ "SigType" SG_ 2566841088 EngSpeedAtPoint3 "RANGE";
BA_ "SPN" SG_ 2566841088 EngSpeedAtPoint3 529;
BA_ "SAEDocument" SG_ 2566841088 EngSpeedAtPoint3 "J1939-71";
BA_ "Status" SG_ 2566841088 EngSpeedAtPoint3 "2.1.0";
BA_ "Variable" SG_ 2566841088 EngPercentTorqueAtPoint2 "RngMod_trqCfgPnt2";
BA_ "SigType" SG_ 2566841088 EngPercentTorqueAtPoint2 "RANGE";
BA_ "SPN" SG_ 2566841088 EngPercentTorqueAtPoint2 540;
BA_ "SAEDocument" SG_ 2566841088 EngPercentTorqueAtPoint2 "J1939-71";
BA_ "Status" SG_ 2566841088 EngPercentTorqueAtPoint2 "2.1.0";
BA_ "Variable" SG_ 2566841088 EngSpeedAtPoint2 "RngMod_nCfgPnt2";
BA_ "SigType" SG_ 2566841088 EngSpeedAtPoint2 "RANGE";
BA_ "SPN" SG_ 2566841088 EngSpeedAtPoint2 528;
BA_ "SAEDocument" SG_ 2566841088 EngSpeedAtPoint2 "J1939-71";
BA_ "Status" SG_ 2566841088 EngSpeedAtPoint2 "2.1.0";
BA_ "Variable" SG_ 2566841088 EngPercentTorqueAtIdlePoint1 "RngMod_trqCfgPnt1";
BA_ "SigType" SG_ 2566841088 EngPercentTorqueAtIdlePoint1 "RANGE";
BA_ "SPN" SG_ 2566841088 EngPercentTorqueAtIdlePoint1 539;
BA_ "SAEDocument" SG_ 2566841088 EngPercentTorqueAtIdlePoint1 "J1939-71";
BA_ "Status" SG_ 2566841088 EngPercentTorqueAtIdlePoint1 "2.1.0";
BA_ "Variable" SG_ 2566841088 EngSpeedAtIdlePoint1 "RngMod_nCfgPnt1";
BA_ "SigType" SG_ 2566841088 EngSpeedAtIdlePoint1 "RANGE";
BA_ "SPN" SG_ 2566841088 EngSpeedAtIdlePoint1 188;
BA_ "SAEDocument" SG_ 2566841088 EngSpeedAtIdlePoint1 "J1939-71";
BA_ "Status" SG_ 2566841088 EngSpeedAtIdlePoint1 "2.1.0";
BA_ "Status" SG_ 2566768128 EngCSFuelIgniterRelayFdbk "3.2.0";
BA_ "SPN" SG_ 2566768128 EngCSFuelIgniterRelayFdbk 5550;
BA_ "Variable" SG_ 2566768128 EngCSFuelIgniterRelayFdbk "GlwPlg_stSVS";
BA_ "Status" SG_ 2566768128 EngCSFuelIgniterRelayCmd "3.4.x";
BA_ "SPN" SG_ 2566768128 EngCSFuelIgniterRelayCmd 5549;
BA_ "Variable" SG_ 2566768128 EngCSFuelIgniterRelayCmd "GlwPlg_stOn";
BA_ "Status" SG_ 2566768128 EngCSFuelIgniterCmd "3.2.0";
BA_ "SigType" SG_ 2566768128 EngCSFuelIgniterCmd "RANGE";
BA_ "SPN" SG_ 2566768128 EngCSFuelIgniterCmd 5548;
BA_ "SAEDocument" SG_ 2566768128 EngCSFuelIgniterCmd "J1939-71";
BA_ "Variable" SG_ 2566768128 EngCSFuelIgniterCmd "GlwPlg_rPs";
BA_ "SigType" SG_ 2566768128 EngStartEnableDevice2Config "DISCRETE";
BA_ "SPN" SG_ 2566768128 EngStartEnableDevice2Config 2898;
BA_ "SAEDocument" SG_ 2566768128 EngStartEnableDevice2Config "J1939-71";
BA_ "Status" SG_ 2566768128 EngStartEnableDevice2Config "Not needed";
BA_ "SigType" SG_ 2566768128 EngStartEnableDevice1Config "DISCRETE";
BA_ "SPN" SG_ 2566768128 EngStartEnableDevice1Config 2899;
BA_ "SAEDocument" SG_ 2566768128 EngStartEnableDevice1Config "J1939-71";
BA_ "Variable" SG_ 2566768128 EngStartEnableDevice1Config "Com_stStrtEnableDev1_C";
BA_ "Status" SG_ 2566768128 EngStartEnableDevice1Config "2.3.0";
BA_ "SigType" SG_ 2566768128 EngStartEnableDevice2 "DISCRETE";
BA_ "SPN" SG_ 2566768128 EngStartEnableDevice2 1804;
BA_ "SAEDocument" SG_ 2566768128 EngStartEnableDevice2 "J1939-71";
BA_ "Status" SG_ 2566768128 EngStartEnableDevice2 "Not needed";
BA_ "Variable" SG_ 2566768128 EngStartEnableDevice1 "Com_stFlmeStrt";
BA_ "SigType" SG_ 2566768128 EngStartEnableDevice1 "DISCRETE";
BA_ "SPN" SG_ 2566768128 EngStartEnableDevice1 626;
BA_ "SAEDocument" SG_ 2566768128 EngStartEnableDevice1 "J1939-71";
BA_ "Status" SG_ 2566768128 EngStartEnableDevice1 "3.4.9";
BA_ "SigType" SG_ 2564816929 EngAutoStrtEnSwitch "DISCRETE";
BA_ "Status" SG_ 2564816929 EngAutoStrtEnSwitch "Requested 3.9.0";
BA_ "SPN" SG_ 2564816929 EngAutoStrtEnSwitch 1656;
BA_ "Variable" SG_ 2564816929 EngAutoStrtEnSwitch "Com_stAutoStartStop";
BA_ "SAEDocument" SG_ 2564816929 EngAutoStrtEnSwitch "J1939-71";
BA_ "SAEDocument" SG_ 2564816929 VehLimSpeedGovIncSwitch "J1939-71";
BA_ "SPN" SG_ 2564816929 VehLimSpeedGovIncSwitch 1654;
BA_ "SigType" SG_ 2564816929 VehLimSpeedGovIncSwitch "DISCRETE";
BA_ "Variable" SG_ 2564816929 VehLimSpeedGovIncSwitch "Com_stVslIncrSwt";
BA_ "Status" SG_ 2564816929 VehLimSpeedGovIncSwitch "3.4.0";
BA_ "SAEDocument" SG_ 2564816929 VehLimSpeedGovDecSwitch "J1939-71";
BA_ "SPN" SG_ 2564816929 VehLimSpeedGovDecSwitch 1655;
BA_ "SigType" SG_ 2564816929 VehLimSpeedGovDecSwitch "DISCRETE";
BA_ "Variable" SG_ 2564816929 VehLimSpeedGovDecSwitch "Com_stVslDecrSwt";
BA_ "Status" SG_ 2564816929 VehLimSpeedGovDecSwitch "3.4.0";
BA_ "Status" SG_ 2564816929 VehLimSpeedGovEnaSwitch "3.4.0";
BA_ "Variable" SG_ 2564816929 VehLimSpeedGovEnaSwitch "Com_stVMSAdjBtn";
BA_ "SigType" SG_ 2564816929 VehLimSpeedGovEnaSwitch "DISCRETE";
BA_ "SPN" SG_ 2564816929 VehLimSpeedGovEnaSwitch 1653;
BA_ "SAEDocument" SG_ 2564816929 VehLimSpeedGovEnaSwitch "J1939-71";
BA_ "Variable" SG_ 2564816929 Req_Pct_Fan_Speed "Com_rFanReq";
BA_ "Status" SG_ 2564816929 Req_Pct_Fan_Speed "3.1.0";
BA_ "SAEDocument" SG_ 2564816929 Req_Pct_Fan_Speed "J1939-71";
BA_ "SPN" SG_ 2564816929 Req_Pct_Fan_Speed 986;
BA_ "SigType" SG_ 2564816929 Req_Pct_Fan_Speed "RANGE";
BA_ "Status" SG_ 2564816929 DPFRgnInhibitSw "2.2.0";
BA_ "Variable" SG_ 2564816929 DPFRgnInhibitSw "PFltRgn_stRgnInhExt";
BA_ "SPN" SG_ 2564816929 DPFRgnInhibitSw 3695;
BA_ "Variable" SG_ 2564816929 DPFRgnForceSwitch "PFltSrv_stRgnDemExt";
BA_ "Status" SG_ 2564816929 DPFRgnForceSwitch "2.2.0";
BA_ "SPN" SG_ 2564816929 DPFRgnForceSwitch 3696;
BA_ "Status" SG_ 2566843136 UnitNumber_B09_B10 "2.1.0";
BA_ "Variable" SG_ 2566843136 UnitNumber_B09_B10 "Frm_dCI_CA";
BA_ "SigType" SG_ 2566843136 UnitNumber_B09_B10 "RANGE";
BA_ "SPN" SG_ 2566843136 UnitNumber_B09_B10 233;
BA_ "SAEDocument" SG_ 2566843136 UnitNumber_B09_B10 "J1939_71";
BA_ "Status" SG_ 2566843136 SerialNumber_B17 "2.1.0";
BA_ "Variable" SG_ 2566843136 SerialNumber_B17 "Frm_dCI_CA";
BA_ "SigType" SG_ 2566843136 SerialNumber_B17 "RANGE";
BA_ "SPN" SG_ 2566843136 SerialNumber_B17 588;
BA_ "SAEDocument" SG_ 2566843136 SerialNumber_B17 "J1939_71";
BA_ "Status" SG_ 2566843136 SerialNumber_B09_B16 "2.1.0";
BA_ "Variable" SG_ 2566843136 SerialNumber_B09_B16 "Frm_dCI_CA";
BA_ "SigType" SG_ 2566843136 SerialNumber_B09_B16 "RANGE";
BA_ "SPN" SG_ 2566843136 SerialNumber_B09_B16 588;
BA_ "SAEDocument" SG_ 2566843136 SerialNumber_B09_B16 "J1939_71";
BA_ "Status" SG_ 2566843136 CI_Delimiter_3 "Ok";
BA_ "Variable" SG_ 2566843136 CI_Delimiter_3 "N/A";
BA_ "SigType" SG_ 2566843136 CI_Delimiter_3 "RANGE";
BA_ "SAEDocument" SG_ 2566843136 CI_Delimiter_3 "J1939_71";
BA_ "Status" SG_ 2566843136 CI_Delimiter_2 "Ok";
BA_ "Variable" SG_ 2566843136 CI_Delimiter_2 "N/A";
BA_ "SigType" SG_ 2566843136 CI_Delimiter_2 "RANGE";
BA_ "SAEDocument" SG_ 2566843136 CI_Delimiter_2 "J1939_71";
BA_ "Status" SG_ 2566843136 Model_B09_B10 "2.1.0";
BA_ "Variable" SG_ 2566843136 Model_B09_B10 "Frm_dCI_CA";
BA_ "SigType" SG_ 2566843136 Model_B09_B10 "RANGE";
BA_ "SPN" SG_ 2566843136 Model_B09_B10 587;
BA_ "SAEDocument" SG_ 2566843136 Model_B09_B10 "J1939_71";
BA_ "Status" SG_ 2566843136 CI_Delimiter_1 "Ok";
BA_ "Variable" SG_ 2566843136 CI_Delimiter_1 "N/A";
BA_ "SigType" SG_ 2566843136 CI_Delimiter_1 "RANGE";
BA_ "SAEDocument" SG_ 2566843136 CI_Delimiter_1 "J1939_71";
BA_ "Variable" SG_ 2566843136 UnitNumber_B01_B08 "Frm_dCI_CA";
BA_ "SigType" SG_ 2566843136 UnitNumber_B01_B08 "RANGE";
BA_ "SPN" SG_ 2566843136 UnitNumber_B01_B08 233;
BA_ "SAEDocument" SG_ 2566843136 UnitNumber_B01_B08 "J1939_71";
BA_ "Status" SG_ 2566843136 UnitNumber_B01_B08 "2.1.0";
BA_ "Variable" SG_ 2566843136 SerialNumber_B01_B08 "Frm_dCI_CA";
BA_ "SigType" SG_ 2566843136 SerialNumber_B01_B08 "RANGE";
BA_ "SPN" SG_ 2566843136 SerialNumber_B01_B08 588;
BA_ "SAEDocument" SG_ 2566843136 SerialNumber_B01_B08 "J1939_71";
BA_ "Status" SG_ 2566843136 SerialNumber_B01_B08 "2.1.0";
BA_ "Variable" SG_ 2566843136 Model_B01_B08 "Frm_dCI_CA";
BA_ "SigType" SG_ 2566843136 Model_B01_B08 "RANGE";
BA_ "SPN" SG_ 2566843136 Model_B01_B08 587;
BA_ "SAEDocument" SG_ 2566843136 Model_B01_B08 "J1939_71";
BA_ "Status" SG_ 2566843136 Model_B01_B08 "2.1.0";
BA_ "Variable" SG_ 2566843136 Make "Frm_dCI_CA";
BA_ "SPN" SG_ 2566843136 Make 586;
BA_ "SAEDocument" SG_ 2566843136 Make "J1939_71";
BA_ "SigType" SG_ 2566843136 Make "RANGE";
BA_ "Status" SG_ 2566843136 Make "2.1.0";
BA_ "SigType" SG_ 2566844672 EngShutdownOverrideSwitch "DISCRETE";
BA_ "SPN" SG_ 2566844672 EngShutdownOverrideSwitch 1237;
BA_ "SAEDocument" SG_ 2566844672 EngShutdownOverrideSwitch "J1939-71";
BA_ "Status" SG_ 2566844672 EngShutdownOverrideSwitch "Not needed";
BA_ "Variable" SG_ 2566844672 EngTestModeSwitch "Com_swtEngTstMode";
BA_ "SigType" SG_ 2566844672 EngTestModeSwitch "DISCRETE";
BA_ "SPN" SG_ 2566844672 EngTestModeSwitch 966;
BA_ "SAEDocument" SG_ 2566844672 EngTestModeSwitch "J1939-71";
BA_ "Status" SG_ 2566844672 EngTestModeSwitch "2.1.0";
BA_ "Variable" SG_ 2566844672 EngIdleDecrementSwitch "Com_swtEngIdlDec";
BA_ "SigType" SG_ 2566844672 EngIdleDecrementSwitch "DISCRETE";
BA_ "SPN" SG_ 2566844672 EngIdleDecrementSwitch 967;
BA_ "SAEDocument" SG_ 2566844672 EngIdleDecrementSwitch "J1939-71";
BA_ "Status" SG_ 2566844672 EngIdleDecrementSwitch "2.1.0";
BA_ "Variable" SG_ 2566844672 EngIdleIncrementSwitch "Com_swtEngIdlInc";
BA_ "SigType" SG_ 2566844672 EngIdleIncrementSwitch "DISCRETE";
BA_ "SPN" SG_ 2566844672 EngIdleIncrementSwitch 968;
BA_ "SAEDocument" SG_ 2566844672 EngIdleIncrementSwitch "J1939-71";
BA_ "Status" SG_ 2566844672 EngIdleIncrementSwitch "2.1.0";
BA_ "Variable" SG_ 2566844672 CruiseCtrlStates "Com_stCrCtlModeState";
BA_ "SigType" SG_ 2566844672 CruiseCtrlStates "DISCRETE";
BA_ "SPN" SG_ 2566844672 CruiseCtrlStates 527;
BA_ "SAEDocument" SG_ 2566844672 CruiseCtrlStates "J1939-71";
BA_ "Status" SG_ 2566844672 CruiseCtrlStates "2.1.0";
BA_ "Variable" SG_ 2566844672 PTOState "Com_stPTOState";
BA_ "SigType" SG_ 2566844672 PTOState "DISCRETE";
BA_ "SPN" SG_ 2566844672 PTOState 976;
BA_ "SAEDocument" SG_ 2566844672 PTOState "J1939-71";
BA_ "Status" SG_ 2566844672 PTOState "2.1.0";
BA_ "Variable" SG_ 2566844672 CruiseCtrlSetSpeed "CrCtl_vDes";
BA_ "SigType" SG_ 2566844672 CruiseCtrlSetSpeed "RANGE";
BA_ "SPN" SG_ 2566844672 CruiseCtrlSetSpeed 86;
BA_ "SAEDocument" SG_ 2566844672 CruiseCtrlSetSpeed "J1939-71";
BA_ "Status" SG_ 2566844672 CruiseCtrlSetSpeed "2.1.0";
BA_ "Variable" SG_ 2566844672 CruiseCtrlAccelerateSwitch "Com_swtCrCtlAccl";
BA_ "SigType" SG_ 2566844672 CruiseCtrlAccelerateSwitch "DISCRETE";
BA_ "SPN" SG_ 2566844672 CruiseCtrlAccelerateSwitch 602;
BA_ "SAEDocument" SG_ 2566844672 CruiseCtrlAccelerateSwitch "J1939-71";
BA_ "Status" SG_ 2566844672 CruiseCtrlAccelerateSwitch "Change requested 3.6.0";
BA_ "Variable" SG_ 2566844672 CruiseCtrlResumeSwitch "Com_swtCrCtlResu";
BA_ "SigType" SG_ 2566844672 CruiseCtrlResumeSwitch "DISCRETE";
BA_ "SPN" SG_ 2566844672 CruiseCtrlResumeSwitch 601;
BA_ "SAEDocument" SG_ 2566844672 CruiseCtrlResumeSwitch "J1939-71";
BA_ "Status" SG_ 2566844672 CruiseCtrlResumeSwitch "Change requested 3.6.0";
BA_ "Variable" SG_ 2566844672 CruiseCtrlCoastSwitch "Com_swtCrCtlDecl";
BA_ "SigType" SG_ 2566844672 CruiseCtrlCoastSwitch "DISCRETE";
BA_ "SPN" SG_ 2566844672 CruiseCtrlCoastSwitch 600;
BA_ "SAEDocument" SG_ 2566844672 CruiseCtrlCoastSwitch "J1939-71";
BA_ "Status" SG_ 2566844672 CruiseCtrlCoastSwitch "Change requested 3.6.0";
BA_ "Variable" SG_ 2566844672 CruiseCtrlSetSwitch "Com_swtCrCtl";
BA_ "SigType" SG_ 2566844672 CruiseCtrlSetSwitch "DISCRETE";
BA_ "SPN" SG_ 2566844672 CruiseCtrlSetSwitch 599;
BA_ "SAEDocument" SG_ 2566844672 CruiseCtrlSetSwitch "J1939-71";
BA_ "Status" SG_ 2566844672 CruiseCtrlSetSwitch "Change requested 3.6.0";
BA_ "Variable" SG_ 2566844672 ClutchSwitch "Clth_st";
BA_ "SigType" SG_ 2566844672 ClutchSwitch "DISCRETE";
BA_ "SPN" SG_ 2566844672 ClutchSwitch 598;
BA_ "SAEDocument" SG_ 2566844672 ClutchSwitch "J1939-71";
BA_ "Status" SG_ 2566844672 ClutchSwitch "2.1.0";
BA_ "Variable" SG_ 2566844672 BrakeSwitch "Brk_st";
BA_ "SigType" SG_ 2566844672 BrakeSwitch "DISCRETE";
BA_ "SPN" SG_ 2566844672 BrakeSwitch 597;
BA_ "SAEDocument" SG_ 2566844672 BrakeSwitch "J1939-71";
BA_ "Status" SG_ 2566844672 BrakeSwitch "2.1.0";
BA_ "SigType" SG_ 2566844672 CruiseCtrlEnableSwitch "DISCRETE";
BA_ "SPN" SG_ 2566844672 CruiseCtrlEnableSwitch 596;
BA_ "SAEDocument" SG_ 2566844672 CruiseCtrlEnableSwitch "J1939-71";
BA_ "Status" SG_ 2566844672 CruiseCtrlEnableSwitch "3.4.0";
BA_ "Variable" SG_ 2566844672 CruiseCtrlEnableSwitch "Com_CrCtlEnblSwt";
BA_ "Variable" SG_ 2566844672 CruiseCtrlActive "CrCtl_stReq";
BA_ "SigType" SG_ 2566844672 CruiseCtrlActive "DISCRETE";
BA_ "SPN" SG_ 2566844672 CruiseCtrlActive 595;
BA_ "SAEDocument" SG_ 2566844672 CruiseCtrlActive "J1939-71";
BA_ "Status" SG_ 2566844672 CruiseCtrlActive "2.1.0";
BA_ "Variable" SG_ 2566844672 WheelBasedVehicleSpeed "VehV_v";
BA_ "SigType" SG_ 2566844672 WheelBasedVehicleSpeed "RANGE";
BA_ "SPN" SG_ 2566844672 WheelBasedVehicleSpeed 84;
BA_ "SAEDocument" SG_ 2566844672 WheelBasedVehicleSpeed "J1939-71";
BA_ "Status" SG_ 2566844672 WheelBasedVehicleSpeed "2.1.0";
BA_ "SigType" SG_ 2566844672 CruiseCtrlPauseSwitch "DISCRETE";
BA_ "SPN" SG_ 2566844672 CruiseCtrlPauseSwitch 1633;
BA_ "SAEDocument" SG_ 2566844672 CruiseCtrlPauseSwitch "J1939-71";
BA_ "Status" SG_ 2566844672 CruiseCtrlPauseSwitch "Not needed";
BA_ "Variable" SG_ 2566844672 ParkingBrakeSwitch "HndBrk_stDebVal";
BA_ "SigType" SG_ 2566844672 ParkingBrakeSwitch "DISCRETE";
BA_ "SPN" SG_ 2566844672 ParkingBrakeSwitch 70;
BA_ "SAEDocument" SG_ 2566844672 ParkingBrakeSwitch "J1939-71";
BA_ "Status" SG_ 2566844672 ParkingBrakeSwitch "2.1.0";
BA_ "SigType" SG_ 2566844672 TwoSpeedAxleSwitch "DISCRETE";
BA_ "SPN" SG_ 2566844672 TwoSpeedAxleSwitch 69;
BA_ "SAEDocument" SG_ 2566844672 TwoSpeedAxleSwitch "J1939-71";
BA_ "Variable" SG_ 2566844672 TwoSpeedAxleSwitch "VehV_swtTwoSpdAxleSel or Com_stTwoSpdAxlSwt";
BA_ "Status" SG_ 2566844672 TwoSpeedAxleSwitch "3.4.0";
BA_ "Variable" SG_ 2566843648 CruiseCtrlLowSetLimitSpeed "CrCtl_vMin";
BA_ "SigType" SG_ 2566843648 CruiseCtrlLowSetLimitSpeed "RANGE";
BA_ "SPN" SG_ 2566843648 CruiseCtrlLowSetLimitSpeed 88;
BA_ "SAEDocument" SG_ 2566843648 CruiseCtrlLowSetLimitSpeed "J1939-71";
BA_ "Status" SG_ 2566843648 CruiseCtrlLowSetLimitSpeed "2.1.0";
BA_ "Variable" SG_ 2566843648 CruiseCtrlHighSetLimitSpeed "CrCtl_vMax";
BA_ "SigType" SG_ 2566843648 CruiseCtrlHighSetLimitSpeed "RANGE";
BA_ "SPN" SG_ 2566843648 CruiseCtrlHighSetLimitSpeed 87;
BA_ "SAEDocument" SG_ 2566843648 CruiseCtrlHighSetLimitSpeed "J1939-71";
BA_ "Status" SG_ 2566843648 CruiseCtrlHighSetLimitSpeed "2.1.0";
BA_ "Variable" SG_ 2566843648 MaxVehicleSpeedLimit "LLim_vMax";
BA_ "SigType" SG_ 2566843648 MaxVehicleSpeedLimit "RANGE";
BA_ "SPN" SG_ 2566843648 MaxVehicleSpeedLimit 74;
BA_ "SAEDocument" SG_ 2566843648 MaxVehicleSpeedLimit "J1939-71";
BA_ "Status" SG_ 2566843648 MaxVehicleSpeedLimit "2.1.0";
BA_ "Status" SG_ 2566836224 TestLimitMinimum "Ok";
BA_ "SigType" SG_ 2566836224 TestLimitMinimum "RANGE";
BA_ "SPN" SG_ 2566836224 TestLimitMinimum 1228;
BA_ "SAEDocument" SG_ 2566836224 TestLimitMinimum "J1939-73";
BA_ "Variable" SG_ 2566836224 TestLimitMinimum "N/A";
BA_ "Status" SG_ 2566836224 TestLimitMaximum "Ok";
BA_ "SigType" SG_ 2566836224 TestLimitMaximum "RANGE";
BA_ "SPN" SG_ 2566836224 TestLimitMaximum 1227;
BA_ "SAEDocument" SG_ 2566836224 TestLimitMaximum "J1939-73";
BA_ "Variable" SG_ 2566836224 TestLimitMaximum "N/A";
BA_ "Status" SG_ 2566836224 TestValue "Ok";
BA_ "SigType" SG_ 2566836224 TestValue "RANGE";
BA_ "SPN" SG_ 2566836224 TestValue 1226;
BA_ "SAEDocument" SG_ 2566836224 TestValue "J1939-73";
BA_ "Variable" SG_ 2566836224 TestValue "N/A";
BA_ "Status" SG_ 2566836224 TestType "Ok";
BA_ "SigType" SG_ 2566836224 TestType "RANGE";
BA_ "SPN" SG_ 2566836224 TestType 1225;
BA_ "SAEDocument" SG_ 2566836224 TestType "J1939-73";
BA_ "Variable" SG_ 2566836224 TestType "N/A";
BA_ "Status" SG_ 2566836224 TestIdentifier "Ok";
BA_ "SigType" SG_ 2566836224 TestIdentifier "RANGE";
BA_ "SPN" SG_ 2566836224 TestIdentifier 1224;
BA_ "SAEDocument" SG_ 2566836224 TestIdentifier "J1939-73";
BA_ "Variable" SG_ 2566836224 TestIdentifier "N/A";
BA_ "Status" SG_ 2565078784 FMIIdentifyCmpntSysSpecificTest "2.1.0";
BA_ "SigType" SG_ 2565078784 FMIIdentifyCmpntSysSpecificTest "RANGE";
BA_ "SPN" SG_ 2565078784 FMIIdentifyCmpntSysSpecificTest 4149;
BA_ "SAEDocument" SG_ 2565078784 FMIIdentifyCmpntSysSpecificTest "J1939-73";
BA_ "Variable" SG_ 2565078784 FMIIdentifyCmpntSysSpecificTest "N/A";
BA_ "Status" SG_ 2565078784 SPNIdentifyingComponentSystem "2.1.0";
BA_ "SigType" SG_ 2565078784 SPNIdentifyingComponentSystem "RANGE";
BA_ "SPN" SG_ 2565078784 SPNIdentifyingComponentSystem 4148;
BA_ "SAEDocument" SG_ 2565078784 SPNIdentifyingComponentSystem "J1939-73";
BA_ "Variable" SG_ 2565078784 SPNIdentifyingComponentSystem "N/A";
BA_ "Status" SG_ 2565078784 TestIdentifier "2.1.0";
BA_ "SigType" SG_ 2565078784 TestIdentifier "RANGE";
BA_ "SPN" SG_ 2565078784 TestIdentifier 1224;
BA_ "SAEDocument" SG_ 2565078784 TestIdentifier "J1939-73";
BA_ "Variable" SG_ 2565078784 TestIdentifier "N/A";
BA_ "Status" SG_ 2566835968 SPN5 "2.1.0";
BA_ "SAEDocument" SG_ 2566835968 SPN5 "J1939-73";
BA_ "Variable" SG_ 2566835968 SPN5 "N/A";
BA_ "SPN" SG_ 2566835968 SPN5 1214;
BA_ "Status" SG_ 2566835968 SPN4 "2.1.0";
BA_ "SAEDocument" SG_ 2566835968 SPN4 "J1939-73";
BA_ "Variable" SG_ 2566835968 SPN4 "N/A";
BA_ "SPN" SG_ 2566835968 SPN4 1214;
BA_ "Status" SG_ 2566835968 SPN3 "2.1.0";
BA_ "SAEDocument" SG_ 2566835968 SPN3 "J1939-73";
BA_ "Variable" SG_ 2566835968 SPN3 "N/A";
BA_ "SPN" SG_ 2566835968 SPN3 1214;
BA_ "Status" SG_ 2566835968 SPN2 "2.1.0";
BA_ "SAEDocument" SG_ 2566835968 SPN2 "J1939-73";
BA_ "Variable" SG_ 2566835968 SPN2 "N/A";
BA_ "SPN" SG_ 2566835968 SPN2 1214;
BA_ "Status" SG_ 2566835968 SPN1 "2.1.0";
BA_ "SPN" SG_ 2566835968 SPN1 1214;
BA_ "SAEDocument" SG_ 2566835968 SPN1 "J1939-73";
BA_ "Variable" SG_ 2566835968 SPN1 "N/A";
BA_ "Status" SG_ 2566835968 RedStopLampStatus "2.1.0";
BA_ "SigType" SG_ 2566835968 RedStopLampStatus "DISCRETE";
BA_ "SPN" SG_ 2566835968 RedStopLampStatus 623;
BA_ "SAEDocument" SG_ 2566835968 RedStopLampStatus "J1939-73";
BA_ "Variable" SG_ 2566835968 RedStopLampStatus "N/A";
BA_ "Status" SG_ 2566835968 ProtectLampStatus "2.1.0";
BA_ "SigType" SG_ 2566835968 ProtectLampStatus "DISCRETE";
BA_ "SPN" SG_ 2566835968 ProtectLampStatus 987;
BA_ "SAEDocument" SG_ 2566835968 ProtectLampStatus "J1939-73";
BA_ "Variable" SG_ 2566835968 ProtectLampStatus "N/A";
BA_ "Status" SG_ 2566835968 AmberWarningLampStatus "2.1.0";
BA_ "SigType" SG_ 2566835968 AmberWarningLampStatus "DISCRETE";
BA_ "SPN" SG_ 2566835968 AmberWarningLampStatus 624;
BA_ "SAEDocument" SG_ 2566835968 AmberWarningLampStatus "J1939-73";
BA_ "Variable" SG_ 2566835968 AmberWarningLampStatus "N/A";
BA_ "Status" SG_ 2566835968 MalfunctionIndicatorLampStatus "2.1.0";
BA_ "SigType" SG_ 2566835968 MalfunctionIndicatorLampStatus "DISCRETE";
BA_ "SPN" SG_ 2566835968 MalfunctionIndicatorLampStatus 1213;
BA_ "SAEDocument" SG_ 2566835968 MalfunctionIndicatorLampStatus "J1939-73";
BA_ "Variable" SG_ 2566835968 MalfunctionIndicatorLampStatus "N/A";
BA_ "Status" SG_ 2566835968 FailureModeIdentifier5 "2.1.0";
BA_ "SAEDocument" SG_ 2566835968 FailureModeIdentifier5 "J1939-73";
BA_ "Variable" SG_ 2566835968 FailureModeIdentifier5 "N/A";
BA_ "SPN" SG_ 2566835968 FailureModeIdentifier5 1215;
BA_ "Status" SG_ 2566835968 FailureModeIdentifier4 "2.1.0";
BA_ "SAEDocument" SG_ 2566835968 FailureModeIdentifier4 "J1939-73";
BA_ "Variable" SG_ 2566835968 FailureModeIdentifier4 "N/A";
BA_ "SPN" SG_ 2566835968 FailureModeIdentifier4 1215;
BA_ "Status" SG_ 2566835968 FailureModeIdentifier3 "2.1.0";
BA_ "SAEDocument" SG_ 2566835968 FailureModeIdentifier3 "J1939-73";
BA_ "Variable" SG_ 2566835968 FailureModeIdentifier3 "N/A";
BA_ "SPN" SG_ 2566835968 FailureModeIdentifier3 1215;
BA_ "Status" SG_ 2566835968 FailureModeIdentifier2 "2.1.0";
BA_ "SAEDocument" SG_ 2566835968 FailureModeIdentifier2 "J1939-73";
BA_ "Variable" SG_ 2566835968 FailureModeIdentifier2 "N/A";
BA_ "SPN" SG_ 2566835968 FailureModeIdentifier2 1215;
BA_ "Status" SG_ 2566835968 SPNConversionMethod5 "2.1.0";
BA_ "SAEDocument" SG_ 2566835968 SPNConversionMethod5 "J1939-73";
BA_ "Variable" SG_ 2566835968 SPNConversionMethod5 "N/A";
BA_ "SPN" SG_ 2566835968 SPNConversionMethod5 1706;
BA_ "Status" SG_ 2566835968 SPNConversionMethod4 "2.1.0";
BA_ "SAEDocument" SG_ 2566835968 SPNConversionMethod4 "J1939-73";
BA_ "Variable" SG_ 2566835968 SPNConversionMethod4 "N/A";
BA_ "SPN" SG_ 2566835968 SPNConversionMethod4 1706;
BA_ "Status" SG_ 2566835968 SPNConversionMethod3 "2.1.0";
BA_ "SAEDocument" SG_ 2566835968 SPNConversionMethod3 "J1939-73";
BA_ "Variable" SG_ 2566835968 SPNConversionMethod3 "N/A";
BA_ "SPN" SG_ 2566835968 SPNConversionMethod3 1706;
BA_ "Status" SG_ 2566835968 SPNConversionMethod2 "2.1.0";
BA_ "SAEDocument" SG_ 2566835968 SPNConversionMethod2 "J1939-73";
BA_ "Variable" SG_ 2566835968 SPNConversionMethod2 "N/A";
BA_ "SPN" SG_ 2566835968 SPNConversionMethod2 1706;
BA_ "Status" SG_ 2566835968 OccurenceCount5 "2.1.0";
BA_ "SigType" SG_ 2566835968 OccurenceCount5 "RANGE";
BA_ "SAEDocument" SG_ 2566835968 OccurenceCount5 "J1939-73";
BA_ "Variable" SG_ 2566835968 OccurenceCount5 "N/A";
BA_ "SPN" SG_ 2566835968 OccurenceCount5 1216;
BA_ "Status" SG_ 2566835968 OccurenceCount4 "2.1.0";
BA_ "SigType" SG_ 2566835968 OccurenceCount4 "RANGE";
BA_ "SAEDocument" SG_ 2566835968 OccurenceCount4 "J1939-73";
BA_ "Variable" SG_ 2566835968 OccurenceCount4 "N/A";
BA_ "SPN" SG_ 2566835968 OccurenceCount4 1216;
BA_ "Status" SG_ 2566835968 OccurenceCount3 "2.1.0";
BA_ "SigType" SG_ 2566835968 OccurenceCount3 "RANGE";
BA_ "SAEDocument" SG_ 2566835968 OccurenceCount3 "J1939-73";
BA_ "Variable" SG_ 2566835968 OccurenceCount3 "N/A";
BA_ "SPN" SG_ 2566835968 OccurenceCount3 1216;
BA_ "Status" SG_ 2566835968 OccurenceCount2 "2.1.0";
BA_ "SigType" SG_ 2566835968 OccurenceCount2 "RANGE";
BA_ "SAEDocument" SG_ 2566835968 OccurenceCount2 "J1939-73";
BA_ "Variable" SG_ 2566835968 OccurenceCount2 "N/A";
BA_ "SPN" SG_ 2566835968 OccurenceCount2 1216;
BA_ "Status" SG_ 2566835968 OccurenceCount1 "2.1.0";
BA_ "SigType" SG_ 2566835968 OccurenceCount1 "RANGE";
BA_ "SPN" SG_ 2566835968 OccurenceCount1 1216;
BA_ "SAEDocument" SG_ 2566835968 OccurenceCount1 "J1939-73";
BA_ "Variable" SG_ 2566835968 OccurenceCount1 "N/A";
BA_ "Status" SG_ 2566835968 SPNConversionMethod1 "2.1.0";
BA_ "SPN" SG_ 2566835968 SPNConversionMethod1 1706;
BA_ "SAEDocument" SG_ 2566835968 SPNConversionMethod1 "J1939-73";
BA_ "Variable" SG_ 2566835968 SPNConversionMethod1 "N/A";
BA_ "Status" SG_ 2566835968 FailureModeIdentifier1 "2.1.0";
BA_ "SPN" SG_ 2566835968 FailureModeIdentifier1 1215;
BA_ "SAEDocument" SG_ 2566835968 FailureModeIdentifier1 "J1939-73";
BA_ "Variable" SG_ 2566835968 FailureModeIdentifier1 "N/A";
BA_ "Status" SG_ 2566835968 SPN5High "2.1.0";
BA_ "SAEDocument" SG_ 2566835968 SPN5High "J1939-73";
BA_ "Variable" SG_ 2566835968 SPN5High "N/A";
BA_ "SPN" SG_ 2566835968 SPN5High 1214;
BA_ "Status" SG_ 2566835968 SPN4High "2.1.0";
BA_ "SAEDocument" SG_ 2566835968 SPN4High "J1939-73";
BA_ "Variable" SG_ 2566835968 SPN4High "N/A";
BA_ "SPN" SG_ 2566835968 SPN4High 1214;
BA_ "Status" SG_ 2566835968 SPN3High "2.1.0";
BA_ "SAEDocument" SG_ 2566835968 SPN3High "J1939-73";
BA_ "Variable" SG_ 2566835968 SPN3High "N/A";
BA_ "SPN" SG_ 2566835968 SPN3High 1214;
BA_ "Status" SG_ 2566835968 SPN2High "2.1.0";
BA_ "SAEDocument" SG_ 2566835968 SPN2High "J1939-73";
BA_ "Variable" SG_ 2566835968 SPN2High "N/A";
BA_ "SPN" SG_ 2566835968 SPN2High 1214;
BA_ "Status" SG_ 2566835968 SPN1High "2.1.0";
BA_ "SPN" SG_ 2566835968 SPN1High 1214;
BA_ "SAEDocument" SG_ 2566835968 SPN1High "J1939-73";
BA_ "Variable" SG_ 2566835968 SPN1High "N/A";
BA_ "Status" SG_ 2566835712 PMFilterMonStatus "2.1.0";
BA_ "SPN" SG_ 2566835712 PMFilterMonStatus 1223;
BA_ "SAEDocument" SG_ 2566835712 PMFilterMonStatus "J1939-73";
BA_ "Variable" SG_ 2566835712 PMFilterMonStatus "N/A";
BA_ "Status" SG_ 2566835712 NOxCnvrtctlystMonStatus "2.1.0";
BA_ "SPN" SG_ 2566835712 NOxCnvrtctlystMonStatus 1223;
BA_ "SAEDocument" SG_ 2566835712 NOxCnvrtctlystMonStatus "J1939-73";
BA_ "Variable" SG_ 2566835712 NOxCnvrtctlystMonStatus "N/A";
BA_ "Status" SG_ 2566835712 NHMCCnvrtctlystMonStatus "2.1.0";
BA_ "SPN" SG_ 2566835712 NHMCCnvrtctlystMonStatus 1223;
BA_ "SAEDocument" SG_ 2566835712 NHMCCnvrtctlystMonStatus "J1939-73";
BA_ "Variable" SG_ 2566835712 NHMCCnvrtctlystMonStatus "N/A";
BA_ "Status" SG_ 2566835712 BstPressCtrlSystemMonStatus "2.1.0";
BA_ "SPN" SG_ 2566835712 BstPressCtrlSystemMonStatus 1223;
BA_ "SAEDocument" SG_ 2566835712 BstPressCtrlSystemMonStatus "J1939-73";
BA_ "Variable" SG_ 2566835712 BstPressCtrlSystemMonStatus "N/A";
BA_ "Status" SG_ 2566835712 NOxCnvrtctlystMonSupp "2.1.0";
BA_ "SPN" SG_ 2566835712 NOxCnvrtctlystMonSupp 1222;
BA_ "SAEDocument" SG_ 2566835712 NOxCnvrtctlystMonSupp "J1939-73";
BA_ "Variable" SG_ 2566835712 NOxCnvrtctlystMonSupp "N/A";
BA_ "Status" SG_ 2566835712 PMFilterMonSupp "2.1.0";
BA_ "SPN" SG_ 2566835712 PMFilterMonSupp 1222;
BA_ "SAEDocument" SG_ 2566835712 PMFilterMonSupp "J1939-73";
BA_ "Variable" SG_ 2566835712 PMFilterMonSupp "N/A";
BA_ "Status" SG_ 2566835712 NHMCCnvrtctlystMonSupp "2.1.0";
BA_ "SPN" SG_ 2566835712 NHMCCnvrtctlystMonSupp 1222;
BA_ "SAEDocument" SG_ 2566835712 NHMCCnvrtctlystMonSupp "J1939-73";
BA_ "Variable" SG_ 2566835712 NHMCCnvrtctlystMonSupp "N/A";
BA_ "Status" SG_ 2566835712 BstPressCtrlSystemMonSupp "2.1.0";
BA_ "SPN" SG_ 2566835712 BstPressCtrlSystemMonSupp 1222;
BA_ "SAEDocument" SG_ 2566835712 BstPressCtrlSystemMonSupp "J1939-73";
BA_ "Variable" SG_ 2566835712 BstPressCtrlSystemMonSupp "N/A";
BA_ "Status" SG_ 2566835712 MisfireMonitoringSupport "2.1.0";
BA_ "SPN" SG_ 2566835712 MisfireMonitoringSupport 1221;
BA_ "SAEDocument" SG_ 2566835712 MisfireMonitoringSupport "J1939-73";
BA_ "Variable" SG_ 2566835712 MisfireMonitoringSupport "N/A";
BA_ "Status" SG_ 2566835712 OBDCompliance "2.1.0";
BA_ "SigType" SG_ 2566835712 OBDCompliance "RANGE";
BA_ "SPN" SG_ 2566835712 OBDCompliance 1220;
BA_ "SAEDocument" SG_ 2566835712 OBDCompliance "J1939-73";
BA_ "Variable" SG_ 2566835712 OBDCompliance "N/A";
BA_ "Status" SG_ 2566835712 PreviouslyActiveTroubleCodes "2.1.0";
BA_ "SigType" SG_ 2566835712 PreviouslyActiveTroubleCodes "RANGE";
BA_ "SPN" SG_ 2566835712 PreviouslyActiveTroubleCodes 1219;
BA_ "SAEDocument" SG_ 2566835712 PreviouslyActiveTroubleCodes "J1939-73";
BA_ "Variable" SG_ 2566835712 PreviouslyActiveTroubleCodes "N/A";
BA_ "Status" SG_ 2566835712 ActiveTroubleCodes "2.1.0";
BA_ "SigType" SG_ 2566835712 ActiveTroubleCodes "RANGE";
BA_ "SPN" SG_ 2566835712 ActiveTroubleCodes 1218;
BA_ "SAEDocument" SG_ 2566835712 ActiveTroubleCodes "J1939-73";
BA_ "Variable" SG_ 2566835712 ActiveTroubleCodes "N/A";
BA_ "Status" SG_ 2566835712 SecondAirSystemMonStatus "2.1.0";
BA_ "SPN" SG_ 2566835712 SecondAirSystemMonStatus 1223;
BA_ "SAEDocument" SG_ 2566835712 SecondAirSystemMonStatus "J1939-73";
BA_ "Variable" SG_ 2566835712 SecondAirSystemMonStatus "N/A";
BA_ "Status" SG_ 2566835712 EvaporativeSystemMonStatus "2.1.0";
BA_ "SPN" SG_ 2566835712 EvaporativeSystemMonStatus 1223;
BA_ "SAEDocument" SG_ 2566835712 EvaporativeSystemMonStatus "J1939-73";
BA_ "Variable" SG_ 2566835712 EvaporativeSystemMonStatus "N/A";
BA_ "Status" SG_ 2566835712 ACSystemRefrigerantMonStatus "2.1.0";
BA_ "SPN" SG_ 2566835712 ACSystemRefrigerantMonStatus 1223;
BA_ "SAEDocument" SG_ 2566835712 ACSystemRefrigerantMonStatus "J1939-73";
BA_ "Variable" SG_ 2566835712 ACSystemRefrigerantMonStatus "N/A";
BA_ "Status" SG_ 2566835712 OxygenSensorHeaterMonStatus "2.1.0";
BA_ "SPN" SG_ 2566835712 OxygenSensorHeaterMonStatus 1223;
BA_ "SAEDocument" SG_ 2566835712 OxygenSensorHeaterMonStatus "J1939-73";
BA_ "Variable" SG_ 2566835712 OxygenSensorHeaterMonStatus "N/A";
BA_ "Status" SG_ 2566835712 OxygenSensorMonStatus "2.1.0";
BA_ "SPN" SG_ 2566835712 OxygenSensorMonStatus 1223;
BA_ "SAEDocument" SG_ 2566835712 OxygenSensorMonStatus "J1939-73";
BA_ "Variable" SG_ 2566835712 OxygenSensorMonStatus "N/A";
BA_ "Status" SG_ 2566835712 EGRSystemMonitoringStatus "2.1.0";
BA_ "SPN" SG_ 2566835712 EGRSystemMonitoringStatus 1223;
BA_ "SAEDocument" SG_ 2566835712 EGRSystemMonitoringStatus "J1939-73";
BA_ "Variable" SG_ 2566835712 EGRSystemMonitoringStatus "N/A";
BA_ "Status" SG_ 2566835712 CatalystMonStatus "2.1.0";
BA_ "SPN" SG_ 2566835712 CatalystMonStatus 1223;
BA_ "SAEDocument" SG_ 2566835712 CatalystMonStatus "J1939-73";
BA_ "Variable" SG_ 2566835712 CatalystMonStatus "N/A";
BA_ "Status" SG_ 2566835712 ColdStartAidSystemMonStatus "2.1.0";
BA_ "SPN" SG_ 2566835712 ColdStartAidSystemMonStatus 1223;
BA_ "SAEDocument" SG_ 2566835712 ColdStartAidSystemMonStatus "J1939-73";
BA_ "Variable" SG_ 2566835712 ColdStartAidSystemMonStatus "N/A";
BA_ "Status" SG_ 2566835712 HeatedCatalystMonStatus "2.1.0";
BA_ "SPN" SG_ 2566835712 HeatedCatalystMonStatus 1223;
BA_ "SAEDocument" SG_ 2566835712 HeatedCatalystMonStatus "J1939-73";
BA_ "Variable" SG_ 2566835712 HeatedCatalystMonStatus "N/A";
BA_ "Status" SG_ 2566835712 CatalystMonSupp "2.1.0";
BA_ "SPN" SG_ 2566835712 CatalystMonSupp 1222;
BA_ "SAEDocument" SG_ 2566835712 CatalystMonSupp "J1939-73";
BA_ "Variable" SG_ 2566835712 CatalystMonSupp "N/A";
BA_ "Status" SG_ 2566835712 ColdStartAidSystemMonSupp "2.1.0";
BA_ "SPN" SG_ 2566835712 ColdStartAidSystemMonSupp 1222;
BA_ "SAEDocument" SG_ 2566835712 ColdStartAidSystemMonSupp "J1939-73";
BA_ "Variable" SG_ 2566835712 ColdStartAidSystemMonSupp "N/A";
BA_ "Status" SG_ 2566835712 HeatedCatalystMonSupp "2.1.0";
BA_ "SPN" SG_ 2566835712 HeatedCatalystMonSupp 1222;
BA_ "SAEDocument" SG_ 2566835712 HeatedCatalystMonSupp "J1939-73";
BA_ "Variable" SG_ 2566835712 HeatedCatalystMonSupp "N/A";
BA_ "Status" SG_ 2566835712 EvaporativeSystemMonSupp "2.1.0";
BA_ "SPN" SG_ 2566835712 EvaporativeSystemMonSupp 1222;
BA_ "SAEDocument" SG_ 2566835712 EvaporativeSystemMonSupp "J1939-73";
BA_ "Variable" SG_ 2566835712 EvaporativeSystemMonSupp "N/A";
BA_ "Status" SG_ 2566835712 SecondAirSystemMonSupp "2.1.0";
BA_ "SPN" SG_ 2566835712 SecondAirSystemMonSupp 1222;
BA_ "SAEDocument" SG_ 2566835712 SecondAirSystemMonSupp "J1939-73";
BA_ "Variable" SG_ 2566835712 SecondAirSystemMonSupp "N/A";
BA_ "Status" SG_ 2566835712 ACSystemRefrigerantMonSupp "2.1.0";
BA_ "SPN" SG_ 2566835712 ACSystemRefrigerantMonSupp 1222;
BA_ "SAEDocument" SG_ 2566835712 ACSystemRefrigerantMonSupp "J1939-73";
BA_ "Variable" SG_ 2566835712 ACSystemRefrigerantMonSupp "N/A";
BA_ "Status" SG_ 2566835712 OxygenSensorMonSupp "2.1.0";
BA_ "SPN" SG_ 2566835712 OxygenSensorMonSupp 1222;
BA_ "SAEDocument" SG_ 2566835712 OxygenSensorMonSupp "J1939-73";
BA_ "Variable" SG_ 2566835712 OxygenSensorMonSupp "N/A";
BA_ "Status" SG_ 2566835712 OxygenSensorHeaterMonSupp "2.1.0";
BA_ "SPN" SG_ 2566835712 OxygenSensorHeaterMonSupp 1222;
BA_ "SAEDocument" SG_ 2566835712 OxygenSensorHeaterMonSupp "J1939-73";
BA_ "Variable" SG_ 2566835712 OxygenSensorHeaterMonSupp "N/A";
BA_ "Status" SG_ 2566835712 EGRSystemMonitoringSupp "2.1.0";
BA_ "SPN" SG_ 2566835712 EGRSystemMonitoringSupp 1222;
BA_ "SAEDocument" SG_ 2566835712 EGRSystemMonitoringSupp "J1939-73";
BA_ "Variable" SG_ 2566835712 EGRSystemMonitoringSupp "N/A";
BA_ "Status" SG_ 2566835712 MisfireMonitoringStatus "2.1.0";
BA_ "SPN" SG_ 2566835712 MisfireMonitoringStatus 1221;
BA_ "SAEDocument" SG_ 2566835712 MisfireMonitoringStatus "J1939-73";
BA_ "Variable" SG_ 2566835712 MisfireMonitoringStatus "N/A";
BA_ "Status" SG_ 2566835712 ComprehensiveCompMonStatus "2.1.0";
BA_ "SPN" SG_ 2566835712 ComprehensiveCompMonStatus 1221;
BA_ "SAEDocument" SG_ 2566835712 ComprehensiveCompMonStatus "J1939-73";
BA_ "Variable" SG_ 2566835712 ComprehensiveCompMonStatus "N/A";
BA_ "Status" SG_ 2566835712 FuelSystemMonitoringStatus "2.1.0";
BA_ "SPN" SG_ 2566835712 FuelSystemMonitoringStatus 1221;
BA_ "SAEDocument" SG_ 2566835712 FuelSystemMonitoringStatus "J1939-73";
BA_ "Variable" SG_ 2566835712 FuelSystemMonitoringStatus "N/A";
BA_ "Status" SG_ 2566835712 ComprehensiveComponentMonSupp "2.1.0";
BA_ "SPN" SG_ 2566835712 ComprehensiveComponentMonSupp 1221;
BA_ "SAEDocument" SG_ 2566835712 ComprehensiveComponentMonSupp "J1939-73";
BA_ "Variable" SG_ 2566835712 ComprehensiveComponentMonSupp "N/A";
BA_ "Status" SG_ 2566835712 FuelSystemMonitoringSupport "2.1.0";
BA_ "SPN" SG_ 2566835712 FuelSystemMonitoringSupport 1221;
BA_ "SAEDocument" SG_ 2566835712 FuelSystemMonitoringSupport "J1939-73";
BA_ "Variable" SG_ 2566835712 FuelSystemMonitoringSupport "N/A";
BA_ "Status" SG_ 2566835456 SPN1 "2.1.0";
BA_ "SPN" SG_ 2566835456 SPN1 1214;
BA_ "SAEDocument" SG_ 2566835456 SPN1 "J1939-73";
BA_ "Variable" SG_ 2566835456 SPN1 "N/A";
BA_ "Variable" SG_ 2566835456 EngSpeed "N/A";
BA_ "Status" SG_ 2566835456 EngSpeed "2.1.0";
BA_ "SigType" SG_ 2566835456 EngSpeed "RANGE";
BA_ "SPN" SG_ 2566835456 EngSpeed 190;
BA_ "SAEDocument" SG_ 2566835456 EngSpeed "J1939-71";
BA_ "Variable" SG_ 2566835456 EngTurboBoostPress "N/A";
BA_ "Status" SG_ 2566835456 EngTurboBoostPress "2.1.0";
BA_ "SigType" SG_ 2566835456 EngTurboBoostPress "RANGE";
BA_ "SPN" SG_ 2566835456 EngTurboBoostPress 102;
BA_ "SAEDocument" SG_ 2566835456 EngTurboBoostPress "J1939-71";
BA_ "Variable" SG_ 2566835456 EngPercentLoadAtCurrentSpeed "N/A";
BA_ "Status" SG_ 2566835456 EngPercentLoadAtCurrentSpeed "2.1.0";
BA_ "SigType" SG_ 2566835456 EngPercentLoadAtCurrentSpeed "RANGE";
BA_ "SPN" SG_ 2566835456 EngPercentLoadAtCurrentSpeed 92;
BA_ "SAEDocument" SG_ 2566835456 EngPercentLoadAtCurrentSpeed "J1939-71";
BA_ "Variable" SG_ 2566835456 WheelBasedVehicleSpeed "N/A";
BA_ "Status" SG_ 2566835456 WheelBasedVehicleSpeed "2.1.0";
BA_ "SigType" SG_ 2566835456 WheelBasedVehicleSpeed "RANGE";
BA_ "SPN" SG_ 2566835456 WheelBasedVehicleSpeed 84;
BA_ "SAEDocument" SG_ 2566835456 WheelBasedVehicleSpeed "J1939-71";
BA_ "Status" SG_ 2566835456 OccurenceCount1 "2.1.0";
BA_ "SigType" SG_ 2566835456 OccurenceCount1 "RANGE";
BA_ "SPN" SG_ 2566835456 OccurenceCount1 1216;
BA_ "SAEDocument" SG_ 2566835456 OccurenceCount1 "J1939-73";
BA_ "Variable" SG_ 2566835456 OccurenceCount1 "N/A";
BA_ "Status" SG_ 2566835456 SPNConversionMethod1 "2.1.0";
BA_ "SPN" SG_ 2566835456 SPNConversionMethod1 1706;
BA_ "SAEDocument" SG_ 2566835456 SPNConversionMethod1 "J1939-73";
BA_ "Variable" SG_ 2566835456 SPNConversionMethod1 "N/A";
BA_ "Status" SG_ 2566835456 FailureModeIdentifier1 "2.1.0";
BA_ "SPN" SG_ 2566835456 FailureModeIdentifier1 1215;
BA_ "SAEDocument" SG_ 2566835456 FailureModeIdentifier1 "J1939-73";
BA_ "Variable" SG_ 2566835456 FailureModeIdentifier1 "N/A";
BA_ "Status" SG_ 2566835456 FreezeFrameLength "2.1.0";
BA_ "SPN" SG_ 2566835456 FreezeFrameLength 1217;
BA_ "SAEDocument" SG_ 2566835456 FreezeFrameLength "J1939-73";
BA_ "Variable" SG_ 2566835456 FreezeFrameLength "N/A";
BA_ "Status" SG_ 2566835456 EngTorqueMode "2.1.0";
BA_ "SigType" SG_ 2566835456 EngTorqueMode "DISCRETE";
BA_ "SPN" SG_ 2566835456 EngTorqueMode 899;
BA_ "SAEDocument" SG_ 2566835456 EngTorqueMode "J1939-71";
BA_ "Variable" SG_ 2566835456 EngTorqueMode "N/A";
BA_ "Variable" SG_ 2566835456 EngineCoolantTemperature "N/A";
BA_ "Status" SG_ 2566835456 EngineCoolantTemperature "2.1.0";
BA_ "SigType" SG_ 2566835456 EngineCoolantTemperature "RANGE";
BA_ "SPN" SG_ 2566835456 EngineCoolantTemperature 110;
BA_ "SAEDocument" SG_ 2566835456 EngineCoolantTemperature "J1939-71";
BA_ "Status" SG_ 2566835456 SPN1High "2.1.0";
BA_ "SPN" SG_ 2566835456 SPN1High 1214;
BA_ "SAEDocument" SG_ 2566835456 SPN1High "J1939-73";
BA_ "Variable" SG_ 2566835456 SPN1High "N/A";
BA_ "SAEDocument" SG_ 2566763776 FailureModeIdentifier5 "J1939-73";
BA_ "Variable" SG_ 2566763776 FailureModeIdentifier5 "N/A";
BA_ "Status" SG_ 2566763776 FailureModeIdentifier5 "2.1.0";
BA_ "SPN" SG_ 2566763776 FailureModeIdentifier5 1215;
BA_ "SAEDocument" SG_ 2566763776 FailureModeIdentifier4 "J1939-73";
BA_ "Variable" SG_ 2566763776 FailureModeIdentifier4 "N/A";
BA_ "Status" SG_ 2566763776 FailureModeIdentifier4 "2.1.0";
BA_ "SPN" SG_ 2566763776 FailureModeIdentifier4 1215;
BA_ "SAEDocument" SG_ 2566763776 FailureModeIdentifier3 "J1939-73";
BA_ "Variable" SG_ 2566763776 FailureModeIdentifier3 "N/A";
BA_ "Status" SG_ 2566763776 FailureModeIdentifier3 "2.1.0";
BA_ "SPN" SG_ 2566763776 FailureModeIdentifier3 1215;
BA_ "SAEDocument" SG_ 2566763776 FailureModeIdentifier2 "J1939-73";
BA_ "Variable" SG_ 2566763776 FailureModeIdentifier2 "N/A";
BA_ "Status" SG_ 2566763776 FailureModeIdentifier2 "2.1.0";
BA_ "SPN" SG_ 2566763776 FailureModeIdentifier2 1215;
BA_ "SPN" SG_ 2566763776 FailureModeIdentifier1 1215;
BA_ "SAEDocument" SG_ 2566763776 FailureModeIdentifier1 "J1939-73";
BA_ "Variable" SG_ 2566763776 FailureModeIdentifier1 "N/A";
BA_ "Status" SG_ 2566763776 FailureModeIdentifier1 "2.1.0";
BA_ "SPN" SG_ 2566763776 FlashRedStopLamp 3039;
BA_ "SAEDocument" SG_ 2566763776 FlashRedStopLamp "J1939-73";
BA_ "Variable" SG_ 2566763776 FlashRedStopLamp "N/A";
BA_ "Status" SG_ 2566763776 FlashRedStopLamp "2.1.0";
BA_ "SPN" SG_ 2566763776 FlashProtectLamp 3041;
BA_ "SAEDocument" SG_ 2566763776 FlashProtectLamp "J1939-73";
BA_ "Variable" SG_ 2566763776 FlashProtectLamp "N/A";
BA_ "Status" SG_ 2566763776 FlashProtectLamp "2.1.0";
BA_ "SigType" SG_ 2566763776 FlashMalfuncIndicatorLamp "DISCRETE";
BA_ "SPN" SG_ 2566763776 FlashMalfuncIndicatorLamp 3038;
BA_ "SAEDocument" SG_ 2566763776 FlashMalfuncIndicatorLamp "J1939-73";
BA_ "Variable" SG_ 2566763776 FlashMalfuncIndicatorLamp "N/A";
BA_ "Status" SG_ 2566763776 FlashMalfuncIndicatorLamp "2.1.0";
BA_ "SPN" SG_ 2566763776 FlashAmberWarningLamp 3040;
BA_ "SAEDocument" SG_ 2566763776 FlashAmberWarningLamp "J1939-73";
BA_ "Variable" SG_ 2566763776 FlashAmberWarningLamp "N/A";
BA_ "Status" SG_ 2566763776 FlashAmberWarningLamp "2.1.0";
BA_ "SAEDocument" SG_ 2566763776 SPN5 "J1939-73";
BA_ "Variable" SG_ 2566763776 SPN5 "N/A";
BA_ "Status" SG_ 2566763776 SPN5 "2.1.0";
BA_ "SPN" SG_ 2566763776 SPN5 1214;
BA_ "SAEDocument" SG_ 2566763776 SPN4 "J1939-73";
BA_ "Variable" SG_ 2566763776 SPN4 "N/A";
BA_ "Status" SG_ 2566763776 SPN4 "2.1.0";
BA_ "SPN" SG_ 2566763776 SPN4 1214;
BA_ "SAEDocument" SG_ 2566763776 SPN3 "J1939-73";
BA_ "Variable" SG_ 2566763776 SPN3 "N/A";
BA_ "Status" SG_ 2566763776 SPN3 "2.1.0";
BA_ "SPN" SG_ 2566763776 SPN3 1214;
BA_ "SAEDocument" SG_ 2566763776 SPN2 "J1939-73";
BA_ "Variable" SG_ 2566763776 SPN2 "N/A";
BA_ "Status" SG_ 2566763776 SPN2 "2.1.0";
BA_ "SPN" SG_ 2566763776 SPN2 1214;
BA_ "SPN" SG_ 2566763776 SPN1 1214;
BA_ "SAEDocument" SG_ 2566763776 SPN1 "J1939-73";
BA_ "Variable" SG_ 2566763776 SPN1 "N/A";
BA_ "Status" SG_ 2566763776 SPN1 "2.1.0";
BA_ "SigType" SG_ 2566763776 RedStopLampStatus "DISCRETE";
BA_ "SPN" SG_ 2566763776 RedStopLampStatus 623;
BA_ "SAEDocument" SG_ 2566763776 RedStopLampStatus "J1939-73";
BA_ "Variable" SG_ 2566763776 RedStopLampStatus "N/A";
BA_ "Status" SG_ 2566763776 RedStopLampStatus "2.1.0";
BA_ "SigType" SG_ 2566763776 ProtectLampStatus "DISCRETE";
BA_ "SPN" SG_ 2566763776 ProtectLampStatus 987;
BA_ "SAEDocument" SG_ 2566763776 ProtectLampStatus "J1939-73";
BA_ "Variable" SG_ 2566763776 ProtectLampStatus "N/A";
BA_ "Status" SG_ 2566763776 ProtectLampStatus "2.1.0";
BA_ "SigType" SG_ 2566763776 AmberWarningLampStatus "DISCRETE";
BA_ "SPN" SG_ 2566763776 AmberWarningLampStatus 624;
BA_ "SAEDocument" SG_ 2566763776 AmberWarningLampStatus "J1939-73";
BA_ "Variable" SG_ 2566763776 AmberWarningLampStatus "N/A";
BA_ "Status" SG_ 2566763776 AmberWarningLampStatus "2.1.0";
BA_ "SigType" SG_ 2566763776 MalfunctionIndicatorLampStatus "DISCRETE";
BA_ "SPN" SG_ 2566763776 MalfunctionIndicatorLampStatus 1213;
BA_ "SAEDocument" SG_ 2566763776 MalfunctionIndicatorLampStatus "J1939-73";
BA_ "Variable" SG_ 2566763776 MalfunctionIndicatorLampStatus "N/A";
BA_ "Status" SG_ 2566763776 MalfunctionIndicatorLampStatus "2.1.0";
BA_ "SigType" SG_ 2566763776 OccurenceCount1 "RANGE";
BA_ "SPN" SG_ 2566763776 OccurenceCount1 1216;
BA_ "SAEDocument" SG_ 2566763776 OccurenceCount1 "J1939-73";
BA_ "Variable" SG_ 2566763776 OccurenceCount1 "N/A";
BA_ "Status" SG_ 2566763776 OccurenceCount1 "2.1.0";
BA_ "SPN" SG_ 2566763776 SPNConversionMethod1 1706;
BA_ "SAEDocument" SG_ 2566763776 SPNConversionMethod1 "J1939-73";
BA_ "Variable" SG_ 2566763776 SPNConversionMethod1 "N/A";
BA_ "Status" SG_ 2566763776 SPNConversionMethod1 "2.1.0";
BA_ "SAEDocument" SG_ 2566763776 SPNConversionMethod5 "J1939-73";
BA_ "Variable" SG_ 2566763776 SPNConversionMethod5 "N/A";
BA_ "Status" SG_ 2566763776 SPNConversionMethod5 "2.1.0";
BA_ "SPN" SG_ 2566763776 SPNConversionMethod5 1706;
BA_ "SAEDocument" SG_ 2566763776 SPNConversionMethod4 "J1939-73";
BA_ "Variable" SG_ 2566763776 SPNConversionMethod4 "N/A";
BA_ "Status" SG_ 2566763776 SPNConversionMethod4 "2.1.0";
BA_ "SPN" SG_ 2566763776 SPNConversionMethod4 1706;
BA_ "SAEDocument" SG_ 2566763776 SPNConversionMethod3 "J1939-73";
BA_ "Variable" SG_ 2566763776 SPNConversionMethod3 "N/A";
BA_ "Status" SG_ 2566763776 SPNConversionMethod3 "2.1.0";
BA_ "SPN" SG_ 2566763776 SPNConversionMethod3 1706;
BA_ "SAEDocument" SG_ 2566763776 SPNConversionMethod2 "J1939-73";
BA_ "Variable" SG_ 2566763776 SPNConversionMethod2 "N/A";
BA_ "Status" SG_ 2566763776 SPNConversionMethod2 "2.1.0";
BA_ "SPN" SG_ 2566763776 SPNConversionMethod2 1706;
BA_ "SigType" SG_ 2566763776 OccurenceCount5 "RANGE";
BA_ "SAEDocument" SG_ 2566763776 OccurenceCount5 "J1939-73";
BA_ "Variable" SG_ 2566763776 OccurenceCount5 "N/A";
BA_ "Status" SG_ 2566763776 OccurenceCount5 "2.1.0";
BA_ "SPN" SG_ 2566763776 OccurenceCount5 1216;
BA_ "SigType" SG_ 2566763776 OccurenceCount4 "RANGE";
BA_ "SAEDocument" SG_ 2566763776 OccurenceCount4 "J1939-73";
BA_ "Variable" SG_ 2566763776 OccurenceCount4 "N/A";
BA_ "Status" SG_ 2566763776 OccurenceCount4 "2.1.0";
BA_ "SPN" SG_ 2566763776 OccurenceCount4 1216;
BA_ "SigType" SG_ 2566763776 OccurenceCount3 "RANGE";
BA_ "SAEDocument" SG_ 2566763776 OccurenceCount3 "J1939-73";
BA_ "Variable" SG_ 2566763776 OccurenceCount3 "N/A";
BA_ "Status" SG_ 2566763776 OccurenceCount3 "2.1.0";
BA_ "SPN" SG_ 2566763776 OccurenceCount3 1216;
BA_ "SigType" SG_ 2566763776 OccurenceCount2 "RANGE";
BA_ "SAEDocument" SG_ 2566763776 OccurenceCount2 "J1939-73";
BA_ "Variable" SG_ 2566763776 OccurenceCount2 "N/A";
BA_ "Status" SG_ 2566763776 OccurenceCount2 "2.1.0";
BA_ "SPN" SG_ 2566763776 OccurenceCount2 1216;
BA_ "SAEDocument" SG_ 2566763776 SPN5High "J1939-73";
BA_ "Variable" SG_ 2566763776 SPN5High "N/A";
BA_ "Status" SG_ 2566763776 SPN5High "2.1.0";
BA_ "SPN" SG_ 2566763776 SPN5High 1214;
BA_ "SAEDocument" SG_ 2566763776 SPN4High "J1939-73";
BA_ "Variable" SG_ 2566763776 SPN4High "N/A";
BA_ "Status" SG_ 2566763776 SPN4High "2.1.0";
BA_ "SPN" SG_ 2566763776 SPN4High 1214;
BA_ "SAEDocument" SG_ 2566763776 SPN3High "J1939-73";
BA_ "Variable" SG_ 2566763776 SPN3High "N/A";
BA_ "Status" SG_ 2566763776 SPN3High "2.1.0";
BA_ "SPN" SG_ 2566763776 SPN3High 1214;
BA_ "SAEDocument" SG_ 2566763776 SPN2High "J1939-73";
BA_ "Variable" SG_ 2566763776 SPN2High "N/A";
BA_ "Status" SG_ 2566763776 SPN2High "2.1.0";
BA_ "SPN" SG_ 2566763776 SPN2High 1214;
BA_ "SPN" SG_ 2566763776 SPN1High 1214;
BA_ "SAEDocument" SG_ 2566763776 SPN1High "J1939-73";
BA_ "Variable" SG_ 2566763776 SPN1High "N/A";
BA_ "Status" SG_ 2566763776 SPN1High "2.1.0";
BA_ "Status" SG_ 2562850304 TimeSinceDTCsCleared "2.1.0";
BA_ "SigType" SG_ 2562850304 TimeSinceDTCsCleared "RANGE";
BA_ "SPN" SG_ 2562850304 TimeSinceDTCsCleared 3296;
BA_ "SAEDocument" SG_ 2562850304 TimeSinceDTCsCleared "J1939-73";
BA_ "Variable" SG_ 2562850304 TimeSinceDTCsCleared "N/A";
BA_ "Status" SG_ 2562850304 MinutesRunByEngineMILActivated "2.1.0";
BA_ "SigType" SG_ 2562850304 MinutesRunByEngineMILActivated "RANGE";
BA_ "SPN" SG_ 2562850304 MinutesRunByEngineMILActivated 3295;
BA_ "SAEDocument" SG_ 2562850304 MinutesRunByEngineMILActivated "J1939-73";
BA_ "Variable" SG_ 2562850304 MinutesRunByEngineMILActivated "N/A";
BA_ "Status" SG_ 2562850304 DistanceSinceDTCsCleared "2.1.0";
BA_ "SigType" SG_ 2562850304 DistanceSinceDTCsCleared "RANGE";
BA_ "SPN" SG_ 2562850304 DistanceSinceDTCsCleared 3294;
BA_ "SAEDocument" SG_ 2562850304 DistanceSinceDTCsCleared "J1939-73";
BA_ "Variable" SG_ 2562850304 DistanceSinceDTCsCleared "N/A";
BA_ "Status" SG_ 2562850304 DistanceWhileMILisActivated "2.1.0";
BA_ "SigType" SG_ 2562850304 DistanceWhileMILisActivated "RANGE";
BA_ "SPN" SG_ 2562850304 DistanceWhileMILisActivated 3069;
BA_ "SAEDocument" SG_ 2562850304 DistanceWhileMILisActivated "J1939-73";
BA_ "Variable" SG_ 2562850304 DistanceWhileMILisActivated "N/A";
BA_ "Status" SG_ 2562915840 ApplSysMonitorDenominator "2.1.0";
BA_ "SigType" SG_ 2562915840 ApplSysMonitorDenominator "RANGE";
BA_ "SPN" SG_ 2562915840 ApplSysMonitorDenominator 3068;
BA_ "SAEDocument" SG_ 2562915840 ApplSysMonitorDenominator "J1939-73";
BA_ "Variable" SG_ 2562915840 ApplSysMonitorDenominator "N/A";
BA_ "Status" SG_ 2562915840 ApplSysMonitorNumerator "2.1.0";
BA_ "SigType" SG_ 2562915840 ApplSysMonitorNumerator "RANGE";
BA_ "SPN" SG_ 2562915840 ApplSysMonitorNumerator 3067;
BA_ "SAEDocument" SG_ 2562915840 ApplSysMonitorNumerator "J1939-73";
BA_ "Variable" SG_ 2562915840 ApplSysMonitorNumerator "N/A";
BA_ "Status" SG_ 2562915840 SPNofApplSysMonitor "2.1.0";
BA_ "SigType" SG_ 2562915840 SPNofApplSysMonitor "RANGE";
BA_ "SPN" SG_ 2562915840 SPNofApplSysMonitor 3066;
BA_ "SAEDocument" SG_ 2562915840 SPNofApplSysMonitor "J1939-73";
BA_ "Variable" SG_ 2562915840 SPNofApplSysMonitor "N/A";
BA_ "Status" SG_ 2562915840 OBDMonitoringCondEncountered "2.1.0";
BA_ "SigType" SG_ 2562915840 OBDMonitoringCondEncountered "RANGE";
BA_ "SPN" SG_ 2562915840 OBDMonitoringCondEncountered 3049;
BA_ "SAEDocument" SG_ 2562915840 OBDMonitoringCondEncountered "J1939-73";
BA_ "Variable" SG_ 2562915840 OBDMonitoringCondEncountered "N/A";
BA_ "Status" SG_ 2562915840 IgnitionCycleCounter "2.1.0";
BA_ "SigType" SG_ 2562915840 IgnitionCycleCounter "RANGE";
BA_ "SPN" SG_ 2562915840 IgnitionCycleCounter 3048;
BA_ "SAEDocument" SG_ 2562915840 IgnitionCycleCounter "J1939-73";
BA_ "Variable" SG_ 2562915840 IgnitionCycleCounter "N/A";
BA_ "Status" SG_ 2566834944 FailureModeIdentifier5 "2.1.0";
BA_ "SAEDocument" SG_ 2566834944 FailureModeIdentifier5 "J1939-73";
BA_ "Variable" SG_ 2566834944 FailureModeIdentifier5 "N/A";
BA_ "SPN" SG_ 2566834944 FailureModeIdentifier5 1215;
BA_ "Status" SG_ 2566834944 FailureModeIdentifier4 "2.1.0";
BA_ "SAEDocument" SG_ 2566834944 FailureModeIdentifier4 "J1939-73";
BA_ "Variable" SG_ 2566834944 FailureModeIdentifier4 "N/A";
BA_ "SPN" SG_ 2566834944 FailureModeIdentifier4 1215;
BA_ "Status" SG_ 2566834944 FailureModeIdentifier3 "2.1.0";
BA_ "SAEDocument" SG_ 2566834944 FailureModeIdentifier3 "J1939-73";
BA_ "Variable" SG_ 2566834944 FailureModeIdentifier3 "N/A";
BA_ "SPN" SG_ 2566834944 FailureModeIdentifier3 1215;
BA_ "Status" SG_ 2566834944 FailureModeIdentifier2 "2.1.0";
BA_ "SAEDocument" SG_ 2566834944 FailureModeIdentifier2 "J1939-73";
BA_ "Variable" SG_ 2566834944 FailureModeIdentifier2 "N/A";
BA_ "SPN" SG_ 2566834944 FailureModeIdentifier2 1215;
BA_ "Status" SG_ 2566834944 FailureModeIdentifier1 "2.1.0";
BA_ "SPN" SG_ 2566834944 FailureModeIdentifier1 1215;
BA_ "SAEDocument" SG_ 2566834944 FailureModeIdentifier1 "J1939-73";
BA_ "Variable" SG_ 2566834944 FailureModeIdentifier1 "N/A";
BA_ "Status" SG_ 2566834944 FlashRedStopLamp "2.1.0";
BA_ "SPN" SG_ 2566834944 FlashRedStopLamp 3039;
BA_ "SAEDocument" SG_ 2566834944 FlashRedStopLamp "J1939-73";
BA_ "Variable" SG_ 2566834944 FlashRedStopLamp "N/A";
BA_ "Status" SG_ 2566834944 FlashProtectLamp "2.1.0";
BA_ "SPN" SG_ 2566834944 FlashProtectLamp 3041;
BA_ "SAEDocument" SG_ 2566834944 FlashProtectLamp "J1939-73";
BA_ "Variable" SG_ 2566834944 FlashProtectLamp "N/A";
BA_ "Status" SG_ 2566834944 FlashMalfuncIndicatorLamp "2.1.0";
BA_ "SigType" SG_ 2566834944 FlashMalfuncIndicatorLamp "DISCRETE";
BA_ "SPN" SG_ 2566834944 FlashMalfuncIndicatorLamp 3038;
BA_ "SAEDocument" SG_ 2566834944 FlashMalfuncIndicatorLamp "J1939-73";
BA_ "Variable" SG_ 2566834944 FlashMalfuncIndicatorLamp "N/A";
BA_ "Status" SG_ 2566834944 FlashAmberWarningLamp "2.1.0";
BA_ "SPN" SG_ 2566834944 FlashAmberWarningLamp 3040;
BA_ "SAEDocument" SG_ 2566834944 FlashAmberWarningLamp "J1939-73";
BA_ "Variable" SG_ 2566834944 FlashAmberWarningLamp "N/A";
BA_ "Status" SG_ 2566834944 SPN5 "2.1.0";
BA_ "SAEDocument" SG_ 2566834944 SPN5 "J1939-73";
BA_ "Variable" SG_ 2566834944 SPN5 "N/A";
BA_ "SPN" SG_ 2566834944 SPN5 1214;
BA_ "Status" SG_ 2566834944 SPN4 "2.1.0";
BA_ "SAEDocument" SG_ 2566834944 SPN4 "J1939-73";
BA_ "Variable" SG_ 2566834944 SPN4 "N/A";
BA_ "SPN" SG_ 2566834944 SPN4 1214;
BA_ "Status" SG_ 2566834944 SPN3 "2.1.0";
BA_ "SAEDocument" SG_ 2566834944 SPN3 "J1939-73";
BA_ "Variable" SG_ 2566834944 SPN3 "N/A";
BA_ "SPN" SG_ 2566834944 SPN3 1214;
BA_ "Status" SG_ 2566834944 SPN2 "2.1.0";
BA_ "SAEDocument" SG_ 2566834944 SPN2 "J1939-73";
BA_ "Variable" SG_ 2566834944 SPN2 "N/A";
BA_ "SPN" SG_ 2566834944 SPN2 1214;
BA_ "Status" SG_ 2566834944 SPN1 "2.1.0";
BA_ "SPN" SG_ 2566834944 SPN1 1214;
BA_ "SAEDocument" SG_ 2566834944 SPN1 "J1939-73";
BA_ "Variable" SG_ 2566834944 SPN1 "N/A";
BA_ "Status" SG_ 2566834944 RedStopLampStatus "2.1.0";
BA_ "SigType" SG_ 2566834944 RedStopLampStatus "DISCRETE";
BA_ "SPN" SG_ 2566834944 RedStopLampStatus 623;
BA_ "SAEDocument" SG_ 2566834944 RedStopLampStatus "J1939-73";
BA_ "Variable" SG_ 2566834944 RedStopLampStatus "N/A";
BA_ "Status" SG_ 2566834944 ProtectLampStatus "2.1.0";
BA_ "SigType" SG_ 2566834944 ProtectLampStatus "DISCRETE";
BA_ "SPN" SG_ 2566834944 ProtectLampStatus 987;
BA_ "SAEDocument" SG_ 2566834944 ProtectLampStatus "J1939-73";
BA_ "Variable" SG_ 2566834944 ProtectLampStatus "N/A";
BA_ "Status" SG_ 2566834944 AmberWarningLampStatus "2.1.0";
BA_ "SigType" SG_ 2566834944 AmberWarningLampStatus "DISCRETE";
BA_ "SPN" SG_ 2566834944 AmberWarningLampStatus 624;
BA_ "SAEDocument" SG_ 2566834944 AmberWarningLampStatus "J1939-73";
BA_ "Variable" SG_ 2566834944 AmberWarningLampStatus "N/A";
BA_ "Status" SG_ 2566834944 MalfunctionIndicatorLampStatus "2.1.0";
BA_ "SigType" SG_ 2566834944 MalfunctionIndicatorLampStatus "DISCRETE";
BA_ "SPN" SG_ 2566834944 MalfunctionIndicatorLampStatus 1213;
BA_ "SAEDocument" SG_ 2566834944 MalfunctionIndicatorLampStatus "J1939-73";
BA_ "Variable" SG_ 2566834944 MalfunctionIndicatorLampStatus "N/A";
BA_ "Status" SG_ 2566834944 OccurenceCount1 "2.1.0";
BA_ "SigType" SG_ 2566834944 OccurenceCount1 "RANGE";
BA_ "SPN" SG_ 2566834944 OccurenceCount1 1216;
BA_ "SAEDocument" SG_ 2566834944 OccurenceCount1 "J1939-73";
BA_ "Variable" SG_ 2566834944 OccurenceCount1 "N/A";
BA_ "Status" SG_ 2566834944 SPNConversionMethod1 "2.1.0";
BA_ "SPN" SG_ 2566834944 SPNConversionMethod1 1706;
BA_ "SAEDocument" SG_ 2566834944 SPNConversionMethod1 "J1939-73";
BA_ "Variable" SG_ 2566834944 SPNConversionMethod1 "N/A";
BA_ "Status" SG_ 2566834944 SPNConversionMethod5 "2.1.0";
BA_ "SAEDocument" SG_ 2566834944 SPNConversionMethod5 "J1939-73";
BA_ "Variable" SG_ 2566834944 SPNConversionMethod5 "N/A";
BA_ "SPN" SG_ 2566834944 SPNConversionMethod5 1706;
BA_ "Status" SG_ 2566834944 SPNConversionMethod4 "2.1.0";
BA_ "SAEDocument" SG_ 2566834944 SPNConversionMethod4 "J1939-73";
BA_ "Variable" SG_ 2566834944 SPNConversionMethod4 "N/A";
BA_ "SPN" SG_ 2566834944 SPNConversionMethod4 1706;
BA_ "Status" SG_ 2566834944 SPNConversionMethod3 "2.1.0";
BA_ "SAEDocument" SG_ 2566834944 SPNConversionMethod3 "J1939-73";
BA_ "Variable" SG_ 2566834944 SPNConversionMethod3 "N/A";
BA_ "SPN" SG_ 2566834944 SPNConversionMethod3 1706;
BA_ "Status" SG_ 2566834944 SPNConversionMethod2 "2.1.0";
BA_ "SAEDocument" SG_ 2566834944 SPNConversionMethod2 "J1939-73";
BA_ "Variable" SG_ 2566834944 SPNConversionMethod2 "N/A";
BA_ "SPN" SG_ 2566834944 SPNConversionMethod2 1706;
BA_ "Status" SG_ 2566834944 OccurenceCount5 "2.1.0";
BA_ "SigType" SG_ 2566834944 OccurenceCount5 "RANGE";
BA_ "SAEDocument" SG_ 2566834944 OccurenceCount5 "J1939-73";
BA_ "Variable" SG_ 2566834944 OccurenceCount5 "N/A";
BA_ "SPN" SG_ 2566834944 OccurenceCount5 1216;
BA_ "Status" SG_ 2566834944 OccurenceCount4 "2.1.0";
BA_ "SigType" SG_ 2566834944 OccurenceCount4 "RANGE";
BA_ "SAEDocument" SG_ 2566834944 OccurenceCount4 "J1939-73";
BA_ "Variable" SG_ 2566834944 OccurenceCount4 "N/A";
BA_ "SPN" SG_ 2566834944 OccurenceCount4 1216;
BA_ "Status" SG_ 2566834944 OccurenceCount3 "2.1.0";
BA_ "SigType" SG_ 2566834944 OccurenceCount3 "RANGE";
BA_ "SAEDocument" SG_ 2566834944 OccurenceCount3 "J1939-73";
BA_ "Variable" SG_ 2566834944 OccurenceCount3 "N/A";
BA_ "SPN" SG_ 2566834944 OccurenceCount3 1216;
BA_ "Status" SG_ 2566834944 OccurenceCount2 "2.1.0";
BA_ "SigType" SG_ 2566834944 OccurenceCount2 "RANGE";
BA_ "SAEDocument" SG_ 2566834944 OccurenceCount2 "J1939-73";
BA_ "Variable" SG_ 2566834944 OccurenceCount2 "N/A";
BA_ "SPN" SG_ 2566834944 OccurenceCount2 1216;
BA_ "Status" SG_ 2566834944 SPN5High "2.1.0";
BA_ "SAEDocument" SG_ 2566834944 SPN5High "J1939-73";
BA_ "Variable" SG_ 2566834944 SPN5High "N/A";
BA_ "SPN" SG_ 2566834944 SPN5High 1214;
BA_ "Status" SG_ 2566834944 SPN4High "2.1.0";
BA_ "SAEDocument" SG_ 2566834944 SPN4High "J1939-73";
BA_ "Variable" SG_ 2566834944 SPN4High "N/A";
BA_ "SPN" SG_ 2566834944 SPN4High 1214;
BA_ "Status" SG_ 2566834944 SPN3High "2.1.0";
BA_ "SAEDocument" SG_ 2566834944 SPN3High "J1939-73";
BA_ "Variable" SG_ 2566834944 SPN3High "N/A";
BA_ "SPN" SG_ 2566834944 SPN3High 1214;
BA_ "Status" SG_ 2566834944 SPN2High "2.1.0";
BA_ "SAEDocument" SG_ 2566834944 SPN2High "J1939-73";
BA_ "Variable" SG_ 2566834944 SPN2High "N/A";
BA_ "SPN" SG_ 2566834944 SPN2High 1214;
BA_ "Status" SG_ 2566834944 SPN1High "2.1.0";
BA_ "SPN" SG_ 2566834944 SPN1High 1214;
BA_ "SAEDocument" SG_ 2566834944 SPN1High "J1939-73";
BA_ "Variable" SG_ 2566834944 SPN1High "N/A";
BA_ "Status" SG_ 2631078400 CalibrationID4 "3.4.9";
BA_ "SPN" SG_ 2631078400 CalibrationID4 1635;
BA_ "SAEDocument" SG_ 2631078400 CalibrationID4 "J1939-73";
BA_ "Variable" SG_ 2631078400 CalibrationID4 "medc_datasetid";
BA_ "Status" SG_ 2631078400 CalibrationID3 "3.4.9";
BA_ "SPN" SG_ 2631078400 CalibrationID3 1635;
BA_ "SAEDocument" SG_ 2631078400 CalibrationID3 "J1939-73";
BA_ "Variable" SG_ 2631078400 CalibrationID3 "medc_datasetid";
BA_ "Status" SG_ 2631078400 CalibrationID2 "3.4.9";
BA_ "SPN" SG_ 2631078400 CalibrationID2 1635;
BA_ "SAEDocument" SG_ 2631078400 CalibrationID2 "J1939-73";
BA_ "Variable" SG_ 2631078400 CalibrationID2 "medc_datasetid";
BA_ "Status" SG_ 2631078400 CalibrationID1 "3.4.9";
BA_ "SPN" SG_ 2631078400 CalibrationID1 1635;
BA_ "SAEDocument" SG_ 2631078400 CalibrationID1 "J1939-73";
BA_ "Variable" SG_ 2631078400 CalibrationID1 "medc_datasetid";
BA_ "Status" SG_ 2631078400 CalibrationVerificationNumber "2.1.0";
BA_ "SigType" SG_ 2631078400 CalibrationVerificationNumber "RANGE";
BA_ "SPN" SG_ 2631078400 CalibrationVerificationNumber 1634;
BA_ "SAEDocument" SG_ 2631078400 CalibrationVerificationNumber "J1939-73";
BA_ "SPN" SG_ 2566837248 FlashRedStopLamp 3039;
BA_ "SAEDocument" SG_ 2566837248 FlashRedStopLamp "J1939-73";
BA_ "Variable" SG_ 2566837248 FlashRedStopLamp "N/A";
BA_ "Status" SG_ 2566837248 FlashRedStopLamp "2.1.0";
BA_ "SPN" SG_ 2566837248 FlashProtectLamp 3041;
BA_ "SAEDocument" SG_ 2566837248 FlashProtectLamp "J1939-73";
BA_ "Variable" SG_ 2566837248 FlashProtectLamp "N/A";
BA_ "Status" SG_ 2566837248 FlashProtectLamp "2.1.0";
BA_ "SigType" SG_ 2566837248 FlashMalfuncIndicatorLamp "DISCRETE";
BA_ "SPN" SG_ 2566837248 FlashMalfuncIndicatorLamp 3038;
BA_ "SAEDocument" SG_ 2566837248 FlashMalfuncIndicatorLamp "J1939-73";
BA_ "Variable" SG_ 2566837248 FlashMalfuncIndicatorLamp "N/A";
BA_ "Status" SG_ 2566837248 FlashMalfuncIndicatorLamp "2.1.0";
BA_ "SPN" SG_ 2566837248 FlashAmberWarningLamp 3040;
BA_ "SAEDocument" SG_ 2566837248 FlashAmberWarningLamp "J1939-73";
BA_ "Variable" SG_ 2566837248 FlashAmberWarningLamp "N/A";
BA_ "Status" SG_ 2566837248 FlashAmberWarningLamp "2.1.0";
BA_ "SAEDocument" SG_ 2566837248 FailureModeIdentifier5 "J1939-73";
BA_ "Variable" SG_ 2566837248 FailureModeIdentifier5 "N/A";
BA_ "Status" SG_ 2566837248 FailureModeIdentifier5 "2.1.0";
BA_ "SPN" SG_ 2566837248 FailureModeIdentifier5 1215;
BA_ "SAEDocument" SG_ 2566837248 FailureModeIdentifier4 "J1939-73";
BA_ "Variable" SG_ 2566837248 FailureModeIdentifier4 "N/A";
BA_ "Status" SG_ 2566837248 FailureModeIdentifier4 "2.1.0";
BA_ "SPN" SG_ 2566837248 FailureModeIdentifier4 1215;
BA_ "SAEDocument" SG_ 2566837248 FailureModeIdentifier3 "J1939-73";
BA_ "Variable" SG_ 2566837248 FailureModeIdentifier3 "N/A";
BA_ "Status" SG_ 2566837248 FailureModeIdentifier3 "2.1.0";
BA_ "SPN" SG_ 2566837248 FailureModeIdentifier3 1215;
BA_ "SAEDocument" SG_ 2566837248 FailureModeIdentifier2 "J1939-73";
BA_ "Variable" SG_ 2566837248 FailureModeIdentifier2 "N/A";
BA_ "Status" SG_ 2566837248 FailureModeIdentifier2 "2.1.0";
BA_ "SPN" SG_ 2566837248 FailureModeIdentifier2 1215;
BA_ "SPN" SG_ 2566837248 FailureModeIdentifier1 1215;
BA_ "SAEDocument" SG_ 2566837248 FailureModeIdentifier1 "J1939-73";
BA_ "Variable" SG_ 2566837248 FailureModeIdentifier1 "N/A";
BA_ "Status" SG_ 2566837248 FailureModeIdentifier1 "2.1.0";
BA_ "SAEDocument" SG_ 2566837248 SPN5 "J1939-73";
BA_ "Variable" SG_ 2566837248 SPN5 "N/A";
BA_ "Status" SG_ 2566837248 SPN5 "2.1.0";
BA_ "SPN" SG_ 2566837248 SPN5 1214;
BA_ "SAEDocument" SG_ 2566837248 SPN4 "J1939-73";
BA_ "Variable" SG_ 2566837248 SPN4 "N/A";
BA_ "Status" SG_ 2566837248 SPN4 "2.1.0";
BA_ "SPN" SG_ 2566837248 SPN4 1214;
BA_ "SAEDocument" SG_ 2566837248 SPN3 "J1939-73";
BA_ "Variable" SG_ 2566837248 SPN3 "N/A";
BA_ "Status" SG_ 2566837248 SPN3 "2.1.0";
BA_ "SPN" SG_ 2566837248 SPN3 1214;
BA_ "SAEDocument" SG_ 2566837248 SPN2 "J1939-73";
BA_ "Variable" SG_ 2566837248 SPN2 "N/A";
BA_ "Status" SG_ 2566837248 SPN2 "2.1.0";
BA_ "SPN" SG_ 2566837248 SPN2 1214;
BA_ "SPN" SG_ 2566837248 SPN1 1214;
BA_ "SAEDocument" SG_ 2566837248 SPN1 "J1939-73";
BA_ "Variable" SG_ 2566837248 SPN1 "N/A";
BA_ "Status" SG_ 2566837248 SPN1 "2.1.0";
BA_ "SigType" SG_ 2566837248 RedStopLampStatus "DISCRETE";
BA_ "SPN" SG_ 2566837248 RedStopLampStatus 623;
BA_ "SAEDocument" SG_ 2566837248 RedStopLampStatus "J1939-73";
BA_ "Variable" SG_ 2566837248 RedStopLampStatus "N/A";
BA_ "Status" SG_ 2566837248 RedStopLampStatus "2.1.0";
BA_ "Status" SG_ 2566837248 ProtectLampStatus "2.1.0";
BA_ "SigType" SG_ 2566837248 ProtectLampStatus "DISCRETE";
BA_ "SPN" SG_ 2566837248 ProtectLampStatus 987;
BA_ "SAEDocument" SG_ 2566837248 ProtectLampStatus "J1939-73";
BA_ "Variable" SG_ 2566837248 ProtectLampStatus "N/A";
BA_ "SigType" SG_ 2566837248 AmberWarningLampStatus "DISCRETE";
BA_ "SPN" SG_ 2566837248 AmberWarningLampStatus 624;
BA_ "SAEDocument" SG_ 2566837248 AmberWarningLampStatus "J1939-73";
BA_ "Variable" SG_ 2566837248 AmberWarningLampStatus "N/A";
BA_ "Status" SG_ 2566837248 AmberWarningLampStatus "2.1.0";
BA_ "SigType" SG_ 2566837248 MalfunctionIndicatorLampStatus "DISCRETE";
BA_ "SPN" SG_ 2566837248 MalfunctionIndicatorLampStatus 1213;
BA_ "SAEDocument" SG_ 2566837248 MalfunctionIndicatorLampStatus "J1939-73";
BA_ "Variable" SG_ 2566837248 MalfunctionIndicatorLampStatus "N/A";
BA_ "Status" SG_ 2566837248 MalfunctionIndicatorLampStatus "2.1.0";
BA_ "SigType" SG_ 2566837248 OccurenceCount1 "RANGE";
BA_ "SPN" SG_ 2566837248 OccurenceCount1 1216;
BA_ "SAEDocument" SG_ 2566837248 OccurenceCount1 "J1939-73";
BA_ "Variable" SG_ 2566837248 OccurenceCount1 "N/A";
BA_ "Status" SG_ 2566837248 OccurenceCount1 "2.1.0";
BA_ "SPN" SG_ 2566837248 SPNConversionMethod1 1706;
BA_ "SAEDocument" SG_ 2566837248 SPNConversionMethod1 "J1939-73";
BA_ "Variable" SG_ 2566837248 SPNConversionMethod1 "N/A";
BA_ "Status" SG_ 2566837248 SPNConversionMethod1 "2.1.0";
BA_ "SAEDocument" SG_ 2566837248 SPNConversionMethod5 "J1939-73";
BA_ "Variable" SG_ 2566837248 SPNConversionMethod5 "N/A";
BA_ "Status" SG_ 2566837248 SPNConversionMethod5 "2.1.0";
BA_ "SPN" SG_ 2566837248 SPNConversionMethod5 1706;
BA_ "Status" SG_ 2566837248 SPNConversionMethod4 "2.1.0";
BA_ "SAEDocument" SG_ 2566837248 SPNConversionMethod4 "J1939-73";
BA_ "Variable" SG_ 2566837248 SPNConversionMethod4 "N/A";
BA_ "SPN" SG_ 2566837248 SPNConversionMethod4 1706;
BA_ "SAEDocument" SG_ 2566837248 SPNConversionMethod3 "J1939-73";
BA_ "Variable" SG_ 2566837248 SPNConversionMethod3 "N/A";
BA_ "Status" SG_ 2566837248 SPNConversionMethod3 "2.1.0";
BA_ "SPN" SG_ 2566837248 SPNConversionMethod3 1706;
BA_ "SAEDocument" SG_ 2566837248 SPNConversionMethod2 "J1939-73";
BA_ "Variable" SG_ 2566837248 SPNConversionMethod2 "N/A";
BA_ "Status" SG_ 2566837248 SPNConversionMethod2 "2.1.0";
BA_ "SPN" SG_ 2566837248 SPNConversionMethod2 1706;
BA_ "SigType" SG_ 2566837248 OccurenceCount5 "RANGE";
BA_ "SAEDocument" SG_ 2566837248 OccurenceCount5 "J1939-73";
BA_ "Variable" SG_ 2566837248 OccurenceCount5 "N/A";
BA_ "Status" SG_ 2566837248 OccurenceCount5 "2.1.0";
BA_ "SPN" SG_ 2566837248 OccurenceCount5 1216;
BA_ "SigType" SG_ 2566837248 OccurenceCount4 "RANGE";
BA_ "SAEDocument" SG_ 2566837248 OccurenceCount4 "J1939-73";
BA_ "Variable" SG_ 2566837248 OccurenceCount4 "N/A";
BA_ "Status" SG_ 2566837248 OccurenceCount4 "2.1.0";
BA_ "SPN" SG_ 2566837248 OccurenceCount4 1216;
BA_ "SigType" SG_ 2566837248 OccurenceCount3 "RANGE";
BA_ "SAEDocument" SG_ 2566837248 OccurenceCount3 "J1939-73";
BA_ "Variable" SG_ 2566837248 OccurenceCount3 "N/A";
BA_ "Status" SG_ 2566837248 OccurenceCount3 "2.1.0";
BA_ "SPN" SG_ 2566837248 OccurenceCount3 1216;
BA_ "SigType" SG_ 2566837248 OccurenceCount2 "RANGE";
BA_ "SAEDocument" SG_ 2566837248 OccurenceCount2 "J1939-73";
BA_ "Variable" SG_ 2566837248 OccurenceCount2 "N/A";
BA_ "Status" SG_ 2566837248 OccurenceCount2 "2.1.0";
BA_ "SPN" SG_ 2566837248 OccurenceCount2 1216;
BA_ "SAEDocument" SG_ 2566837248 SPN5High "J1939-73";
BA_ "Variable" SG_ 2566837248 SPN5High "N/A";
BA_ "Status" SG_ 2566837248 SPN5High "2.1.0";
BA_ "SPN" SG_ 2566837248 SPN5High 1214;
BA_ "SAEDocument" SG_ 2566837248 SPN4High "J1939-73";
BA_ "Variable" SG_ 2566837248 SPN4High "N/A";
BA_ "Status" SG_ 2566837248 SPN4High "2.1.0";
BA_ "SPN" SG_ 2566837248 SPN4High 1214;
BA_ "SAEDocument" SG_ 2566837248 SPN3High "J1939-73";
BA_ "Variable" SG_ 2566837248 SPN3High "N/A";
BA_ "Status" SG_ 2566837248 SPN3High "2.1.0";
BA_ "SPN" SG_ 2566837248 SPN3High 1214;
BA_ "SAEDocument" SG_ 2566837248 SPN2High "J1939-73";
BA_ "Variable" SG_ 2566837248 SPN2High "N/A";
BA_ "Status" SG_ 2566837248 SPN2High "2.1.0";
BA_ "SPN" SG_ 2566837248 SPN2High 1214;
BA_ "SPN" SG_ 2566837248 SPN1High 1214;
BA_ "SAEDocument" SG_ 2566837248 SPN1High "J1939-73";
BA_ "Variable" SG_ 2566837248 SPN1High "N/A";
BA_ "Status" SG_ 2566837248 SPN1High "2.1.0";
BA_ "SigType" SG_ 2566836736 TestIdentifierSupported "RANGE";
BA_ "SPN" SG_ 2566836736 TestIdentifierSupported 1229;
BA_ "SAEDocument" SG_ 2566836736 TestIdentifierSupported "J1939-73";
BA_ "Variable" SG_ 2566836736 TestIdentifierSupported "N/A";
BA_ "Status" SG_ 2566836736 TestIdentifierSupported "2.1.0";
BA_ "Status" SG_ 2565603072 SequenceNumber "Ok";
BA_ "Variable" SG_ 2565603072 SequenceNumber "N/A";
BA_ "SigType" SG_ 2565603072 SequenceNumber "RANGE";
BA_ "SPN" SG_ 2565603072 SequenceNumber 2572;
BA_ "SAEDocument" SG_ 2565603072 SequenceNumber "J1939-21";
BA_ "SigType" SG_ 2566845696 RoadSurfaceTemp "RANGE";
BA_ "SPN" SG_ 2566845696 RoadSurfaceTemp 79;
BA_ "SAEDocument" SG_ 2566845696 RoadSurfaceTemp "J1939-71";
BA_ "Status" SG_ 2566845696 RoadSurfaceTemp "Not needed";
BA_ "Variable" SG_ 2566845696 EngAirInletTemp "ATHEval_tSensTemp";
BA_ "Status" SG_ 2566845696 EngAirInletTemp "3.4.0";
BA_ "SigType" SG_ 2566845696 EngAirInletTemp "RANGE";
BA_ "SPN" SG_ 2566845696 EngAirInletTemp 172;
BA_ "SAEDocument" SG_ 2566845696 EngAirInletTemp "J1939-71";
BA_ "SigType" SG_ 2566845696 AmbientAirTemp "RANGE";
BA_ "SPN" SG_ 2566845696 AmbientAirTemp 171;
BA_ "SAEDocument" SG_ 2566845696 AmbientAirTemp "J1939-71";
BA_ "Status" SG_ 2566845696 AmbientAirTemp "3.4.0";
BA_ "Variable" SG_ 2566845696 AmbientAirTemp "EnvT_tSens";
BA_ "SigType" SG_ 2566845696 CabInteriorTemp "RANGE";
BA_ "SPN" SG_ 2566845696 CabInteriorTemp 170;
BA_ "SAEDocument" SG_ 2566845696 CabInteriorTemp "J1939-71";
BA_ "Status" SG_ 2566845696 CabInteriorTemp "Not needed";
BA_ "SigType" SG_ 2566845696 BarometricPress "RANGE";
BA_ "SPN" SG_ 2566845696 BarometricPress 108;
BA_ "SAEDocument" SG_ 2566845696 BarometricPress "J1939-71";
BA_ "Variable" SG_ 2566845696 BarometricPress "EnvP_pSens";
BA_ "Status" SG_ 2566845696 BarometricPress "2.3.0";
BA_ "Variable" SG_ 2633935360 EngDsiredAbsIntakeManifoldPress "PCR_pDesVal";
BA_ "SigType" SG_ 2633935360 EngDsiredAbsIntakeManifoldPress "RANGE";
BA_ "SPN" SG_ 2633935360 EngDsiredAbsIntakeManifoldPress 1692;
BA_ "SAEDocument" SG_ 2633935360 EngDsiredAbsIntakeManifoldPress "J1939-71";
BA_ "Status" SG_ 2633935360 EngDsiredAbsIntakeManifoldPress "2.1.0";
BA_ "SigType" SG_ 2432593706 RoadCurvature "RANGE";
BA_ "SPN" SG_ 2432593706 RoadCurvature 1591;
BA_ "SAEDocument" SG_ 2432593706 RoadCurvature "J1939-71";
BA_ "Status" SG_ 2432593706 RoadCurvature "Not needed";
BA_ "SigType" SG_ 2432593706 AdptveCruiseCtrlSetDistanceMode "DISCRETE";
BA_ "SPN" SG_ 2432593706 AdptveCruiseCtrlSetDistanceMode 1589;
BA_ "SAEDocument" SG_ 2432593706 AdptveCruiseCtrlSetDistanceMode "J1939-71";
BA_ "Status" SG_ 2432593706 AdptveCruiseCtrlSetDistanceMode "Not needed";
BA_ "Variable" SG_ 2432593706 AdaptiveCruiseCtrlMode "Com_stACCMode";
BA_ "Status" SG_ 2432593706 AdaptiveCruiseCtrlMode "3.1.0";
BA_ "SigType" SG_ 2432593706 AdaptiveCruiseCtrlMode "DISCRETE";
BA_ "SPN" SG_ 2432593706 AdaptiveCruiseCtrlMode 1590;
BA_ "SAEDocument" SG_ 2432593706 AdaptiveCruiseCtrlMode "J1939-71";
BA_ "SigType" SG_ 2432593706 AdaptiveCruiseCtrlSetSpeed "RANGE";
BA_ "SPN" SG_ 2432593706 AdaptiveCruiseCtrlSetSpeed 1588;
BA_ "SAEDocument" SG_ 2432593706 AdaptiveCruiseCtrlSetSpeed "J1939-71";
BA_ "Status" SG_ 2432593706 AdaptiveCruiseCtrlSetSpeed "Not needed";
BA_ "SigType" SG_ 2432593706 DistanceToForwardVehicle "RANGE";
BA_ "SPN" SG_ 2432593706 DistanceToForwardVehicle 1587;
BA_ "SAEDocument" SG_ 2432593706 DistanceToForwardVehicle "J1939-71";
BA_ "Status" SG_ 2432593706 DistanceToForwardVehicle "Not needed";
BA_ "SigType" SG_ 2432593706 SpeedOfForwardVehicle "RANGE";
BA_ "SPN" SG_ 2432593706 SpeedOfForwardVehicle 1586;
BA_ "SAEDocument" SG_ 2432593706 SpeedOfForwardVehicle "J1939-71";
BA_ "Status" SG_ 2432593706 SpeedOfForwardVehicle "Not needed";
BA_ "Status" SG_ 2566763520 ParticulateTrapIntakeGasTemp "2.4.0";
BA_ "SAEDocument" SG_ 2566763520 ParticulateTrapIntakeGasTemp "J1939_73";
BA_ "SPN" SG_ 2566763520 ParticulateTrapIntakeGasTemp 3242;
BA_ "Variable" SG_ 2566763520 ParticulateTrapIntakeGasTemp "Exh_tSensTPFltUs";
BA_ "SigType" SG_ 2566763520 ExhaustGasTemp1 "RANGE";
BA_ "SPN" SG_ 2566763520 ExhaustGasTemp1 3241;
BA_ "SAEDocument" SG_ 2566763520 ExhaustGasTemp1 "J1939-71";
BA_ "Status" SG_ 2566763520 ExhaustGasTemp1 "Not needed";
BA_ "SigType" SG_ 2566763008 PrtcltTrpIntrmdtGsTmpPrlmnryFMI "RANGE";
BA_ "SPN" SG_ 2566763008 PrtcltTrpIntrmdtGsTmpPrlmnryFMI 3254;
BA_ "SAEDocument" SG_ 2566763008 PrtcltTrpIntrmdtGsTmpPrlmnryFMI "J1939-71";
BA_ "Status" SG_ 2566763008 PrtcltTrpIntrmdtGsTmpPrlmnryFMI "Not needed";
BA_ "SigType" SG_ 2566763008 PrtcltTrpDltPressPreliminaryFMI "RANGE";
BA_ "SPN" SG_ 2566763008 PrtcltTrpDltPressPreliminaryFMI 3253;
BA_ "SAEDocument" SG_ 2566763008 PrtcltTrpDltPressPreliminaryFMI "J1939-71";
BA_ "Status" SG_ 2566763008 PrtcltTrpDltPressPreliminaryFMI "Not needed";
BA_ "SigType" SG_ 2566763008 ExhaustGasTemp2PreliminaryFMI "RANGE";
BA_ "SPN" SG_ 2566763008 ExhaustGasTemp2PreliminaryFMI 3252;
BA_ "SAEDocument" SG_ 2566763008 ExhaustGasTemp2PreliminaryFMI "J1939-71";
BA_ "Status" SG_ 2566763008 ExhaustGasTemp2PreliminaryFMI "Not needed";
BA_ "Status" SG_ 2566763008 ParticulateTrapDiffPress "2.2.0";
BA_ "Variable" SG_ 2566763008 ParticulateTrapDiffPress "Exh_pSensPPFltDiff";
BA_ "SigType" SG_ 2566763008 ParticulateTrapDiffPress "RANGE";
BA_ "SPN" SG_ 2566763008 ParticulateTrapDiffPress 3251;
BA_ "SAEDocument" SG_ 2566763008 ParticulateTrapDiffPress "J1939-71";
BA_ "SigType" SG_ 2566763008 PrtclateTrapIntermediateGasTemp "RANGE";
BA_ "SPN" SG_ 2566763008 PrtclateTrapIntermediateGasTemp 3250;
BA_ "SAEDocument" SG_ 2566763008 PrtclateTrapIntermediateGasTemp "J1939-71";
BA_ "Status" SG_ 2566763008 PrtclateTrapIntermediateGasTemp "Not needed";
BA_ "SigType" SG_ 2566763008 ExhaustGasTemp2 "RANGE";
BA_ "SPN" SG_ 2566763008 ExhaustGasTemp2 3249;
BA_ "SAEDocument" SG_ 2566763008 ExhaustGasTemp2 "J1939-71";
BA_ "Status" SG_ 2566763008 ExhaustGasTemp2 "Not needed";
BA_ "SigType" SG_ 2566763264 PrtcltTrpOtltExhstGsTmpPrlmnryFM "RANGE";
BA_ "SPN" SG_ 2566763264 PrtcltTrpOtltExhstGsTmpPrlmnryFM 3248;
BA_ "SAEDocument" SG_ 2566763264 PrtcltTrpOtltExhstGsTmpPrlmnryFM "J1939-71";
BA_ "Status" SG_ 2566763264 PrtcltTrpOtltExhstGsTmpPrlmnryFM "Not needed";
BA_ "SigType" SG_ 2566763264 ExhaustGasTemp3PreliminaryFMI "RANGE";
BA_ "SPN" SG_ 2566763264 ExhaustGasTemp3PreliminaryFMI 3247;
BA_ "SAEDocument" SG_ 2566763264 ExhaustGasTemp3PreliminaryFMI "J1939-71";
BA_ "Status" SG_ 2566763264 ExhaustGasTemp3PreliminaryFMI "Not needed";
BA_ "Variable" SG_ 2566763264 ParticulateTrapOutletGasTemp "Exh_tSensTPFltDs";
BA_ "SigType" SG_ 2566763264 ParticulateTrapOutletGasTemp "RANGE";
BA_ "SPN" SG_ 2566763264 ParticulateTrapOutletGasTemp 3246;
BA_ "SAEDocument" SG_ 2566763264 ParticulateTrapOutletGasTemp "J1939-71";
BA_ "Status" SG_ 2566763264 ParticulateTrapOutletGasTemp "2.1.0";
BA_ "Variable" SG_ 2566763264 ExhaustGasTemp3 "Exh_tSensTPFltDs";
BA_ "SigType" SG_ 2566763264 ExhaustGasTemp3 "RANGE";
BA_ "SPN" SG_ 2566763264 ExhaustGasTemp3 3245;
BA_ "SAEDocument" SG_ 2566763264 ExhaustGasTemp3 "J1939-71";
BA_ "Status" SG_ 2566763264 ExhaustGasTemp3 "Not needed";
VAL_ 2566841088 SupportTSC1CtrlPurposeGroup4Of4 1 "P25ReservedForAssignmentBySAE" ;
VAL_ 2566841088 SupportVariableRateTSC1Message 1 "MsTransRate" ;
VAL_ 2566841088 SupportTSC1CtrlPurposeGroup3Of4 1 "P17ReservedForAssignmentBySAE" ;
VAL_ 2566841088 SupportTSC1CtrlPurposeGroup2Of4 1 "P9ReservedForAssignmentBySAE" ;
VAL_ 2566841088 SupportTSC1CtrlPurposeGroup1Of4 1 "P1AccelPedal_OperatorSelection" ;
VAL_ 2566768128 EngCSFuelIgniterRelayFdbk 3 "Not Available" 2 "Error" 1 "On" 0 "Off" ;
VAL_ 2566768128 EngCSFuelIgniterRelayCmd 3 "Not Available" 2 "Error" 1 "On" 0 "Off" ;
VAL_ 2566768128 EngStartEnableDevice2Config 15 "NotAvailable" 5 "1110Reserved" 4 "ElectricInletAirHeaterInstalled" 3 "EtherInjectionInstalled" 2 "FuelledStartInstalled" 1 "GlowPlugsInstalled" 0 "NoStartEnableDevice2Installed" ;
VAL_ 2566768128 EngStartEnableDevice1Config 15 "NotAvailable" 5 "1110Reserved" 4 "ElectricInletAirHeaterInstalled" 3 "EtherInjectionInstalled" 2 "FuelledStartInstalled" 1 "GlowPlugsInstalled" 0 "NoStartEnableDevice1Installed" ;
VAL_ 2566768128 EngStartEnableDevice2 2 "Reserved" 1 "StartEnableON" 0 "StartEnableOFF" ;
VAL_ 2566768128 EngStartEnableDevice1 3 "NotAvailible" 2 "Reserved" 1 "StartEnableON" 0 "StartEnableOFF" ;
VAL_ 2564816929 EngAutoStrtEnSwitch 3 "Not Available" 2 "Error" 1 "On" 0 "Off" ;
VAL_ 2564816929 VehLimSpeedGovIncSwitch 3 "Not available" 2 "Error" 1 "Switch in the on state-increase" 0 "Switch in the off state" ;
VAL_ 2564816929 VehLimSpeedGovDecSwitch 3 "Not available" 2 "Error" 1 "Switch in the on state-decrease" 0 "Switch in the off state" ;
VAL_ 2564816929 VehLimSpeedGovEnaSwitch 3 "Not available" 2 "Error" 1 "Switch enabled" 0 "Switch disabled" ;
VAL_ 2566844672 EngShutdownOverrideSwitch 3 "NotAvailable" 2 "Error" 1 "On" 0 "Off" ;
VAL_ 2566844672 EngTestModeSwitch 3 "NotAvailable" 2 "Error" 1 "On" 0 "Off" ;
VAL_ 2566844672 EngIdleDecrementSwitch 3 "NotAvailable" 2 "Error" 1 "On" 0 "Off" ;
VAL_ 2566844672 EngIdleIncrementSwitch 3 "NotAvailable" 2 "Error" 1 "On" 0 "Off" ;
VAL_ 2566844672 CruiseCtrlAccelerateSwitch 3 "NotAvailable" 2 "Error" 1 "CrsCtrlActivatorInPosAccelerate" 0 "CrsCtrlActvtrNotInPosAccelerate" ;
VAL_ 2566844672 CruiseCtrlResumeSwitch 3 "NotAvailable" 2 "Error" 1 "CruiseCtrlActivatorInPosResume" 0 "CrseCtrlActivatorNotInPosResume" ;
VAL_ 2566844672 CruiseCtrlCoastSwitch 3 "NotAvailable" 2 "Error" 1 "CruiseCtrlActivatorInPosCoast" 0 "CriseCtrlActivatorNotInPosCoast" ;
VAL_ 2566844672 CruiseCtrlSetSwitch 3 "NotAvailable" 2 "Error" 1 "CruiseCtrlActivatorInPosSet" 0 "CruiseCtrlActivatorNotInPosSet" ;
VAL_ 2566844672 ClutchSwitch 3 "NotAvailable" 2 "Error" 1 "ClutchPedalDepressed" 0 "ClutchPedalReleased" ;
VAL_ 2566844672 BrakeSwitch 3 "NotAvailable" 2 "Error" 1 "BrakePedalDepressed" 0 "BrakePedalReleased" ;
VAL_ 2566844672 CruiseCtrlEnableSwitch 3 "NotAvailable" 2 "Error" 1 "CruiseCtrlEnabled" 0 "CruiseCtrlDisabled" ;
VAL_ 2566844672 CruiseCtrlActive 3 "NotAvailable" 2 "Error" 1 "CruiseCtrlSwitchedOn" 0 "CruiseCtrlSwitchedOff" ;
VAL_ 2566844672 CruiseCtrlPauseSwitch 3 "TakeNoAction" 2 "ErrorIndicator" 1 "On" 0 "Off" ;
VAL_ 2566844672 ParkingBrakeSwitch 3 "NotAvailable" 2 "Error" 1 "ParkingBrakeSet" 0 "ParkingBrakeNotSet" ;
VAL_ 2566844672 TwoSpeedAxleSwitch 3 "NotAvailable" 2 "Error" 1 "HighSpeedRange" 0 "LowSpeedRange" ;
VAL_ 2566836224 TestIdentifier 82 "High Pressure Service Test" 72 "DFSOV Leak Test" 71 "Injector Leak Test" 70 "Doser Flow Test" 66 "Test of Cylinder Cut Out Test" 65 "Test of Cylinder Cut Out Test" 64 "Test of Cylinder Cut Out Test" 57 "Test of Cylinder Cut Out Test" 56 "Test of Cylinder Cut Out Test" 55 "Test of Cylinder Cut Out Test" 54 "Run Up Test" 18 "Compression Test" 52 "Actuator Test" ;
VAL_ 2565078784 TestIdentifier 82 "High Pressure Service Test" 72 "DFSOV Leak Test" 71 "Injector Leak Test" 70 "Doser Flow Test" 66 "Test of Cylinder Cut Out Test" 65 "Test of Cylinder Cut Out Test" 64 "Test of Cylinder Cut Out Test" 57 "Test of Cylinder Cut Out Test" 56 "Test of Cylinder Cut Out Test" 55 "Test of Cylinder Cut Out Test" 54 "Run Up Test" 18 "Compression Test" 52 "Actuator Test" ;
VAL_ 2566835968 RedStopLampStatus 3 "Not available" 2 "Reserved" 1 "Lamp on" 0 "Lamp off" ;
VAL_ 2566835968 ProtectLampStatus 3 "Not available" 2 "Reserved" 1 "Lamp on" 0 "Lamp off" ;
VAL_ 2566835968 AmberWarningLampStatus 3 "Not available" 2 "Reserved" 1 "Lamp on" 0 "Lamp off" ;
VAL_ 2566835968 MalfunctionIndicatorLampStatus 3 "Not available" 2 "Reserved" 1 "Lamp on" 0 "Lamp off" ;
VAL_ 2566835968 FailureModeIdentifier5 31 "Not available" 19 "Received network data in error" 18 "Below normal (moderatels severe)" 17 "Below normal (least severe)" 16 "Above normal (moderately severe)" 15 "Above normal (least severe)" 14 "Special intstructions" 13 "Out of calibration" 12 "Bad intelligent device" 11 "Root cause not known" 10 "Abnormal rate of change" 9 "Abnormal update rate" 8 "Abnormal frequency" 7 "Mechanical system not responding" 6 "Current above normal" 5 "Current below normal" 4 "Voltage below normal" 3 "Voltage above normal" 2 "Data erratic" 1 "Below normal (most severe)" 0 "Above normal (most severe)" ;
VAL_ 2566835968 FailureModeIdentifier4 31 "Not available" 19 "Received network data in error" 18 "Below normal (moderatels severe)" 17 "Below normal (least severe)" 16 "Above normal (moderately severe)" 15 "Above normal (least severe)" 14 "Special intstructions" 13 "Out of calibration" 12 "Bad intelligent device" 11 "Root cause not known" 10 "Abnormal rate of change" 9 "Abnormal update rate" 8 "Abnormal frequency" 7 "Mechanical system not responding" 6 "Current above normal" 5 "Current below normal" 4 "Voltage below normal" 3 "Voltage above normal" 2 "Data erratic" 1 "Below normal (most severe)" 0 "Above normal (most severe)" ;
VAL_ 2566835968 FailureModeIdentifier3 31 "Not available" 19 "Received network data in error" 18 "Below normal (moderatels severe)" 17 "Below normal (least severe)" 16 "Above normal (moderately severe)" 15 "Above normal (least severe)" 14 "Special intstructions" 13 "Out of calibration" 12 "Bad intelligent device" 11 "Root cause not known" 10 "Abnormal rate of change" 9 "Abnormal update rate" 8 "Abnormal frequency" 7 "Mechanical system not responding" 6 "Current above normal" 5 "Current below normal" 4 "Voltage below normal" 3 "Voltage above normal" 2 "Data erratic" 1 "Below normal (most severe)" 0 "Above normal (most severe)" ;
VAL_ 2566835968 FailureModeIdentifier2 31 "Not available" 19 "Received network data in error" 18 "Below normal (moderatels severe)" 17 "Below normal (least severe)" 16 "Above normal (moderately severe)" 15 "Above normal (least severe)" 14 "Special intstructions" 13 "Out of calibration" 12 "Bad intelligent device" 11 "Root cause not known" 10 "Abnormal rate of change" 9 "Abnormal update rate" 8 "Abnormal frequency" 7 "Mechanical system not responding" 6 "Current above normal" 5 "Current below normal" 4 "Voltage below normal" 3 "Voltage above normal" 2 "Data erratic" 1 "Below normal (most severe)" 0 "Above normal (most severe)" ;
VAL_ 2566835968 FailureModeIdentifier1 31 "Not available" 19 "Received network data in error" 18 "Below normal (moderatels severe)" 17 "Below normal (least severe)" 16 "Above normal (moderately severe)" 15 "Above normal (least severe)" 14 "Special intstructions" 13 "Out of calibration" 12 "Bad intelligent device" 11 "Root cause not known" 10 "Abnormal rate of change" 9 "Abnormal update rate" 8 "Abnormal frequency" 7 "Mechanical system not responding" 6 "Current above normal" 5 "Current below normal" 4 "Voltage below normal" 3 "Voltage above normal" 2 "Data erratic" 1 "Below normal (most severe)" 0 "Above normal (most severe)" ;
VAL_ 2566835712 PMFilterMonStatus 1 "Test not complete" 0 "Test complete" ;
VAL_ 2566835712 NOxCnvrtctlystMonStatus 1 "Test not complete" 0 "test complete" ;
VAL_ 2566835712 NHMCCnvrtctlystMonStatus 1 "Test not complete" 0 "Test complete" ;
VAL_ 2566835712 BstPressCtrlSystemMonStatus 1 "Test not complete" 0 "Test complete" ;
VAL_ 2566835712 NOxCnvrtctlystMonSupp 1 "Testsupportedbycontroller" 0 "TestNOTsupportedbycontroller" ;
VAL_ 2566835712 PMFilterMonSupp 1 "Testsupportedbycontroller" 0 "TestNOTsupportedbycontroller" ;
VAL_ 2566835712 NHMCCnvrtctlystMonSupp 1 "Testsupportedbycontroller" 0 "TestNOTsupportedbycontroller" ;
VAL_ 2566835712 BstPressCtrlSystemMonSupp 1 "Test Supported" 0 "TestNOTsupportedbycontroller" ;
VAL_ 2566835712 MisfireMonitoringSupport 3 "Not available" 2 "Reserved" 1 "test supported" 0 "test not supported" ;
VAL_ 2566835712 OBDCompliance 5 "Not intended to meet OBD II requ" 4 "OBD I" 3 "OBD and OBD II" 2 "OBD (Federal, EPA)" 1 "OBD II (California, ARB)" 0 "Reserver for assignment by SAE" ;
VAL_ 2566835712 SecondAirSystemMonStatus 1 "TestNotComplete" 0 "TestComplete" ;
VAL_ 2566835712 EvaporativeSystemMonStatus 1 "TestNotComplete" 0 "TestComplete" ;
VAL_ 2566835712 ACSystemRefrigerantMonStatus 1 "TestNotComplete" 0 "TestComplete" ;
VAL_ 2566835712 OxygenSensorHeaterMonStatus 1 "TestNotComplete" 0 "TestComplete" ;
VAL_ 2566835712 OxygenSensorMonStatus 1 "test not complete" 0 "test complete" ;
VAL_ 2566835712 EGRSystemMonitoringStatus 1 "TestNotComplete" 0 "TestComplete" ;
VAL_ 2566835712 CatalystMonStatus 0 "TestComplete" 1 "TestNotComplete" ;
VAL_ 2566835712 ColdStartAidSystemMonStatus 1 "TestNotComplete" 0 "TestComplete" ;
VAL_ 2566835712 HeatedCatalystMonStatus 1 "TestNotComplete" 0 "TestComplete" ;
VAL_ 2566835712 CatalystMonSupp 1 "TestSupported" 0 "TestNotSupported" ;
VAL_ 2566835712 ColdStartAidSystemMonSupp 1 "TestSupported" 0 "TestNotSupported" ;
VAL_ 2566835712 HeatedCatalystMonSupp 1 "TestSupported" 0 "TestNotSupported" ;
VAL_ 2566835712 EvaporativeSystemMonSupp 1 "TestSupported" 0 "TestNotSupported" ;
VAL_ 2566835712 SecondAirSystemMonSupp 1 "TestSupported" 0 "TestNotSupported" ;
VAL_ 2566835712 ACSystemRefrigerantMonSupp 1 "TestSupported" 0 "TestNotSupported" ;
VAL_ 2566835712 OxygenSensorMonSupp 1 "TestSupported" 0 "TestNotSupported" ;
VAL_ 2566835712 OxygenSensorHeaterMonSupp 1 "TestSupported" 0 "TestNotSupported" ;
VAL_ 2566835712 EGRSystemMonitoringSupp 1 "TestSupported" 0 "TestNotSupported" ;
VAL_ 2566835712 MisfireMonitoringStatus 1 "test not complete" 0 "test complete" ;
VAL_ 2566835712 ComprehensiveCompMonStatus 1 "test not complete" 0 "test complete" ;
VAL_ 2566835712 FuelSystemMonitoringStatus 1 "test not complete" 0 "test complete" ;
VAL_ 2566835712 ComprehensiveComponentMonSupp 3 "Not available" 2 "Reserved" 1 "test supported" 0 "test not supported" ;
VAL_ 2566835712 FuelSystemMonitoringSupport 1 "test supported" 0 "test not supported" ;
VAL_ 2566835456 FailureModeIdentifier1 31 "Not available" 19 "Received network data in error" 18 "Below normal (moderatels severe)" 17 "Below normal (least severe)" 16 "Above normal (moderately severe)" 15 "Above normal (least severe)" 14 "Special intstructions" 13 "Out of calibration" 12 "Bad intelligent device" 11 "Root cause not known" 10 "Abnormal rate of change" 9 "Abnormal update rate" 8 "Abnormal frequency" 7 "Mechanical system not responding" 6 "Current above normal" 5 "Current below normal" 4 "Voltage below normal" 3 "Voltage above normal" 2 "Data erratic" 1 "Below normal (most severe)" 0 "Above normal (most severe)" ;
VAL_ 2566835456 EngTorqueMode 15 "Not available" 11 "Remote accelerator" 10 "Braking system" 9 "High speed governor" 8 "Torque limiting" 7 "ABS control" 6 "Transmission control" 5 "ASR control" 4 "Road speed governor" 3 "PTO governor" 2 "Cruise control" 1 "Accelerator pedal/operator selec" 0 "Low idle governor/no request (de" ;
VAL_ 2566763776 FailureModeIdentifier5 31 "Not available" 19 "Received network data in error" 18 "Below normal (moderatels severe)" 17 "Below normal (least severe)" 16 "Above normal (moderately severe)" 15 "Above normal (least severe)" 14 "Special intstructions" 13 "Out of calibration" 12 "Bad intelligent device" 11 "Root cause not known" 10 "Abnormal rate of change" 9 "Abnormal update rate" 8 "Abnormal frequency" 7 "Mechanical system not responding" 6 "Current above normal" 5 "Current below normal" 4 "Voltage below normal" 3 "Voltage above normal" 2 "Data erratic" 1 "Below normal (most severe)" 0 "Above normal (most severe)" ;
VAL_ 2566763776 FailureModeIdentifier4 31 "Not available" 19 "Received network data in error" 18 "Below normal (moderatels severe)" 17 "Below normal (least severe)" 16 "Above normal (moderately severe)" 15 "Above normal (least severe)" 14 "Special intstructions" 13 "Out of calibration" 12 "Bad intelligent device" 11 "Root cause not known" 10 "Abnormal rate of change" 9 "Abnormal update rate" 8 "Abnormal frequency" 7 "Mechanical system not responding" 6 "Current above normal" 5 "Current below normal" 4 "Voltage below normal" 3 "Voltage above normal" 2 "Data erratic" 1 "Below normal (most severe)" 0 "Above normal (most severe)" ;
VAL_ 2566763776 FailureModeIdentifier3 31 "Not available" 19 "Received network data in error" 18 "Below normal (moderatels severe)" 17 "Below normal (least severe)" 16 "Above normal (moderately severe)" 15 "Above normal (least severe)" 14 "Special intstructions" 13 "Out of calibration" 12 "Bad intelligent device" 11 "Root cause not known" 10 "Abnormal rate of change" 9 "Abnormal update rate" 8 "Abnormal frequency" 7 "Mechanical system not responding" 6 "Current above normal" 5 "Current below normal" 4 "Voltage below normal" 3 "Voltage above normal" 2 "Data erratic" 1 "Below normal (most severe)" 0 "Above normal (most severe)" ;
VAL_ 2566763776 FailureModeIdentifier2 31 "Not available" 19 "Received network data in error" 18 "Below normal (moderatels severe)" 17 "Below normal (least severe)" 16 "Above normal (moderately severe)" 15 "Above normal (least severe)" 14 "Special intstructions" 13 "Out of calibration" 12 "Bad intelligent device" 11 "Root cause not known" 10 "Abnormal rate of change" 9 "Abnormal update rate" 8 "Abnormal frequency" 7 "Mechanical system not responding" 6 "Current above normal" 5 "Current below normal" 4 "Voltage below normal" 3 "Voltage above normal" 2 "Data erratic" 1 "Below normal (most severe)" 0 "Above normal (most severe)" ;
VAL_ 2566763776 FailureModeIdentifier1 31 "Not available" 19 "Received network data in error" 18 "Below normal (moderatels severe)" 17 "Below normal (least severe)" 16 "Above normal (moderately severe)" 15 "Above normal (least severe)" 14 "Special intstructions" 13 "Out of calibration" 12 "Bad intelligent device" 11 "Root cause not known" 10 "Abnormal rate of change" 9 "Abnormal update rate" 8 "Abnormal frequency" 7 "Mechanical system not responding" 6 "Current above normal" 5 "Current below normal" 4 "Voltage below normal" 3 "Voltage above normal" 2 "Data erratic" 1 "Below normal (most severe)" 0 "Above normal (most severe)" ;
VAL_ 2566763776 FlashRedStopLamp 3 "Unavailable / Do Not Flash" 2 "Reserved" 1 "Fast Flash" 0 "Slow Flash" ;
VAL_ 2566763776 FlashProtectLamp 3 "Unavailable / Do Not Flash" 2 "Reserved" 1 "Fast Flash" 0 "Slow Flash" ;
VAL_ 2566763776 FlashMalfuncIndicatorLamp 3 "Unavailable / Do Not Flash" 2 "Reserved" 1 "Fast Flash" 0 "Slow Flash" ;
VAL_ 2566763776 FlashAmberWarningLamp 3 "Unavailable / Do Not Flash" 2 "Reserved" 1 "Fast Flash" 0 "Slow Flash" ;
VAL_ 2566763776 RedStopLampStatus 3 "Not available" 2 "Reserved" 1 "Lamp on" 0 "Lamp off" ;
VAL_ 2566763776 ProtectLampStatus 3 "Not available" 2 "Reserved" 1 "Lamp on" 0 "Lamp off" ;
VAL_ 2566763776 AmberWarningLampStatus 3 "Not available" 2 "Reserved" 1 "Lamp on" 0 "Lamp off" ;
VAL_ 2566763776 MalfunctionIndicatorLampStatus 3 "Not available" 2 "Reserved" 1 "Lamp on" 0 "Lamp off" ;
VAL_ 2566834944 FailureModeIdentifier5 31 "Not available" 19 "Received network data in error" 18 "Below normal (moderatels severe)" 17 "Below normal (least severe)" 16 "Above normal (moderately severe)" 15 "Above normal (least severe)" 14 "Special intstructions" 13 "Out of calibration" 12 "Bad intelligent device" 11 "Root cause not known" 10 "Abnormal rate of change" 9 "Abnormal update rate" 8 "Abnormal frequency" 7 "Mechanical system not responding" 6 "Current above normal" 5 "Current below normal" 4 "Voltage below normal" 3 "Voltage above normal" 2 "Data erratic" 1 "Below normal (most severe)" 0 "Above normal (most severe)" ;
VAL_ 2566834944 FailureModeIdentifier4 31 "Not available" 19 "Received network data in error" 18 "Below normal (moderatels severe)" 17 "Below normal (least severe)" 16 "Above normal (moderately severe)" 15 "Above normal (least severe)" 14 "Special intstructions" 13 "Out of calibration" 12 "Bad intelligent device" 11 "Root cause not known" 10 "Abnormal rate of change" 9 "Abnormal update rate" 8 "Abnormal frequency" 7 "Mechanical system not responding" 6 "Current above normal" 5 "Current below normal" 4 "Voltage below normal" 3 "Voltage above normal" 2 "Data erratic" 1 "Below normal (most severe)" 0 "Above normal (most severe)" ;
VAL_ 2566834944 FailureModeIdentifier3 31 "Not available" 19 "Received network data in error" 18 "Below normal (moderatels severe)" 17 "Below normal (least severe)" 16 "Above normal (moderately severe)" 15 "Above normal (least severe)" 14 "Special intstructions" 13 "Out of calibration" 12 "Bad intelligent device" 11 "Root cause not known" 10 "Abnormal rate of change" 9 "Abnormal update rate" 8 "Abnormal frequency" 7 "Mechanical system not responding" 6 "Current above normal" 5 "Current below normal" 4 "Voltage below normal" 3 "Voltage above normal" 2 "Data erratic" 1 "Below normal (most severe)" 0 "Above normal (most severe)" ;
VAL_ 2566834944 FailureModeIdentifier2 31 "Not available" 19 "Received network data in error" 18 "Below normal (moderatels severe)" 17 "Below normal (least severe)" 16 "Above normal (moderately severe)" 15 "Above normal (least severe)" 14 "Special intstructions" 13 "Out of calibration" 12 "Bad intelligent device" 11 "Root cause not known" 10 "Abnormal rate of change" 9 "Abnormal update rate" 8 "Abnormal frequency" 7 "Mechanical system not responding" 6 "Current above normal" 5 "Current below normal" 4 "Voltage below normal" 3 "Voltage above normal" 2 "Data erratic" 1 "Below normal (most severe)" 0 "Above normal (most severe)" ;
VAL_ 2566834944 FailureModeIdentifier1 31 "Not available" 19 "Received network data in error" 18 "Below normal (moderatels severe)" 17 "Below normal (least severe)" 16 "Above normal (moderately severe)" 15 "Above normal (least severe)" 14 "Special intstructions" 13 "Out of calibration" 12 "Bad intelligent device" 11 "Root cause not known" 10 "Abnormal rate of change" 9 "Abnormal update rate" 8 "Abnormal frequency" 7 "Mechanical system not responding" 6 "Current above normal" 5 "Current below normal" 4 "Voltage below normal" 3 "Voltage above normal" 2 "Data erratic" 1 "Below normal (most severe)" 0 "Above normal (most severe)" ;
VAL_ 2566834944 FlashRedStopLamp 3 "Unavailable / Do Not Flash" 2 "Reserved" 1 "Fast Flash" 0 "Slow Flash" ;
VAL_ 2566834944 FlashProtectLamp 3 "Unavailable / Do Not Flash" 2 "Reserved" 1 "Fast Flash" 0 "Slow Flash" ;
VAL_ 2566834944 FlashMalfuncIndicatorLamp 3 "Unavailable / Do Not Flash" 2 "Reserved" 1 "Fast Flash" 0 "Slow Flash" ;
VAL_ 2566834944 FlashAmberWarningLamp 3 "Unavailable / Do Not Flash" 2 "Reserved" 1 "Fast Flash" 0 "Slow Flash" ;
VAL_ 2566834944 RedStopLampStatus 3 "Not available" 2 "Reserved" 1 "Lamp on" 0 "Lamp off" ;
VAL_ 2566834944 ProtectLampStatus 3 "Not available" 2 "Reserved" 1 "Lamp on" 0 "Lamp off" ;
VAL_ 2566834944 AmberWarningLampStatus 3 "Not available" 2 "Reserved" 1 "Lamp on" 0 "Lamp off" ;
VAL_ 2566834944 MalfunctionIndicatorLampStatus 3 "Not available" 2 "Reserved" 1 "Lamp on" 0 "Lamp off" ;
VAL_ 2566837248 FlashRedStopLamp 3 "Unavailable / Do Not Flash" 2 "Reserved" 1 "Fast Flash" 0 "Slow Flash" ;
VAL_ 2566837248 FlashProtectLamp 3 "Unavailable / Do Not Flash" 2 "Reserved" 1 "Fast Flash" 0 "Slow Flash" ;
VAL_ 2566837248 FlashMalfuncIndicatorLamp 3 "Unavailable / Do Not Flash" 2 "Reserved" 1 "Fast Flash" 0 "Slow Flash" ;
VAL_ 2566837248 FlashAmberWarningLamp 3 "Unavailable / Do Not Flash" 2 "Reserved" 1 "Fast Flash" 0 "Slow Flash" ;
VAL_ 2566837248 FailureModeIdentifier5 31 "Not available" 19 "Received network data in error" 18 "Below normal (moderatels severe)" 17 "Below normal (least severe)" 16 "Above normal (moderately severe)" 15 "Above normal (least severe)" 14 "Special intstructions" 13 "Out of calibration" 12 "Bad intelligent device" 11 "Root cause not known" 10 "Abnormal rate of change" 9 "Abnormal update rate" 8 "Abnormal frequency" 7 "Mechanical system not responding" 6 "Current above normal" 5 "Current below normal" 4 "Voltage below normal" 3 "Voltage above normal" 2 "Data erratic" 1 "Below normal (most severe)" 0 "Above normal (most severe)" ;
VAL_ 2566837248 FailureModeIdentifier4 31 "Not available" 19 "Received network data in error" 18 "Below normal (moderatels severe)" 17 "Below normal (least severe)" 16 "Above normal (moderately severe)" 15 "Above normal (least severe)" 14 "Special intstructions" 13 "Out of calibration" 12 "Bad intelligent device" 11 "Root cause not known" 10 "Abnormal rate of change" 9 "Abnormal update rate" 8 "Abnormal frequency" 7 "Mechanical system not responding" 6 "Current above normal" 5 "Current below normal" 4 "Voltage below normal" 3 "Voltage above normal" 2 "Data erratic" 1 "Below normal (most severe)" 0 "Above normal (most severe)" ;
VAL_ 2566837248 FailureModeIdentifier3 31 "Not available" 19 "Received network data in error" 18 "Below normal (moderatels severe)" 17 "Below normal (least severe)" 16 "Above normal (moderately severe)" 15 "Above normal (least severe)" 14 "Special intstructions" 13 "Out of calibration" 12 "Bad intelligent device" 11 "Root cause not known" 10 "Abnormal rate of change" 9 "Abnormal update rate" 8 "Abnormal frequency" 7 "Mechanical system not responding" 6 "Current above normal" 5 "Current below normal" 4 "Voltage below normal" 3 "Voltage above normal" 2 "Data erratic" 1 "Below normal (most severe)" 0 "Above normal (most severe)" ;
VAL_ 2566837248 FailureModeIdentifier2 31 "Not available" 19 "Received network data in error" 18 "Below normal (moderatels severe)" 17 "Below normal (least severe)" 16 "Above normal (moderately severe)" 15 "Above normal (least severe)" 14 "Special intstructions" 13 "Out of calibration" 12 "Bad intelligent device" 11 "Root cause not known" 10 "Abnormal rate of change" 9 "Abnormal update rate" 8 "Abnormal frequency" 7 "Mechanical system not responding" 6 "Current above normal" 5 "Current below normal" 4 "Voltage below normal" 3 "Voltage above normal" 2 "Data erratic" 1 "Below normal (most severe)" 0 "Above normal (most severe)" ;
VAL_ 2566837248 FailureModeIdentifier1 31 "Not available" 19 "Received network data in error" 18 "Below normal (moderatels severe)" 17 "Below normal (least severe)" 16 "Above normal (moderately severe)" 15 "Above normal (least severe)" 14 "Special intstructions" 13 "Out of calibration" 12 "Bad intelligent device" 11 "Root cause not known" 10 "Abnormal rate of change" 9 "Abnormal update rate" 8 "Abnormal frequency" 7 "Mechanical system not responding" 6 "Current above normal" 5 "Current below normal" 4 "Voltage below normal" 3 "Voltage above normal" 2 "Data erratic" 1 "Below normal (most severe)" 0 "Above normal (most severe)" ;
VAL_ 2566837248 RedStopLampStatus 3 "Not available" 2 "Reserved" 1 "Lamp on" 0 "Lamp off" ;
VAL_ 2566837248 ProtectLampStatus 3 "Not available" 2 "Reserved" 1 "Lamp on" 0 "Lamp off" ;
VAL_ 2566837248 AmberWarningLampStatus 3 "Not available" 2 "Reserved" 1 "Lamp on" 0 "Lamp off" ;
VAL_ 2566837248 MalfunctionIndicatorLampStatus 3 "Not available" 2 "Reserved" 1 "Lamp on" 0 "Lamp off" ;
VAL_ 2432593706 AdptveCruiseCtrlSetDistanceMode 7 "NotAvailable_NotValid" 6 "ErrorCondition" 5 "ConventionalCruiseCtrlMode" 4 "ACCDistanceMode5" 3 "ACCDistanceMode4" 2 "ACCDistanceMode3" 1 "ACCDistanceMode2" 0 "ACCDistanceMode1" ;
VAL_ 2432593706 AdaptiveCruiseCtrlMode 7 "NotAvailable_NotValid" 6 "DsbldErrrCndtnUsdTIndctThtACCIs" 5 "FinishMode" 4 "HldMdUsdTIndctThtACCHsLstThPrvs" 3 "OvertakeMode" 2 "DstncCtrlActvUsdTIndctThtACCIsO" 1 "SpeedCtrlActive" 0 "OffUsdTIndctACCIsEnbldInClbCnfg" ;
